VERSION ""

NS_ :

BS_:

BU_: VT3 VT2 VT1 Implement
VAL_TABLE_ NetworkInterconnUnitParametrics 16 "NetworkInterconnectionUnitType" 15 "NumberOfPorts" 14 "UptimeSinceLastPowerOnReset " 13 "AverageNumOfMsgsFilteredPerSec" 12 "AverageNumOfMsgsForwardedPerSec" 11 "AverageNumOfMsgsReceivedPerSec" 10 "NumOfMsgsWithExcessTransitDelayTime " 9 "NumOfMsgsLostDueToBufferOverflow " 8 "AverageTransitDelayTime" 7 "MaxTransitDelayTime" 6 "MaxNumOfMsgsFilteredPerSec" 5 "MaxNumOfMsgsForwardedPerSec" 4 "MaxNumOfMsgsReceivedPerSec" 3 "NumberOfFilterDatabaseEntries" 2 "MaxFilterDatabaseSize" 1 "BufferSize" 0 "RequestAllParameters" ;
VAL_TABLE_ FMI 0 "Above normal (most severe)" 1 "Below normal (most severe)" 2 "Data erratic" 3 "Voltage above normal" 4 "Voltage below normal" 5 "Current below normal" 6 "Current above normal" 7 "Mechanical system not responding" 8 "Abnormal frequency" 9 "Abnormal update rate" 10 "Abnormal rate of change" 11 "Root cause not known" 12 "Bad intelligent device" 13 "Out of calibration" 14 "Special intstructions" 15 "Above normal (least severe)" 16 "Above normal (moderately severe)" 17 "Below normal (least severe)" 18 "Below normal (moderately severe)" 19 "Received network data in error" 31 "Not available" 20 "Data Drifted High" 21 "Data Drifted Low" ;

BO_ 3221225472 VECTOR__INDEPENDENT_SIG_MSG: 0 Vector__XXX
 SG_ NumOfReportedFuncCharacteristics : 0|8@1+ (1,0) [0|255] "" Vector__XXX
 SG_ FirstListedFuncCharacteristic : 0|8@1+ (1,0) [0|255] "" Vector__XXX
 SG_ FirstListedFuncGen : 0|8@1+ (1,0) [0|255] "" Vector__XXX
 SG_ NumOfFirstListedFuncOptionBytes : 0|8@1+ (1,0) [0|2] "" Vector__XXX
 SG_ VTFuncOptions : 0|8@1+ (1,0) [0|250] "" Vector__XXX
 SG_ AuxType1_SupportFunc0 : 0|1@1+ (1,0) [0|1] "" Vector__XXX
 SG_ AuxType1_SupportFunc1 : 0|1@1+ (1,0) [0|1] "" Vector__XXX
 SG_ AuxType1_SupportFunc2 : 0|1@1+ (1,0) [0|1] "" Vector__XXX
 SG_ AuxType2_SupportFunc00 : 0|1@1+ (1,0) [0|1] "" Vector__XXX
 SG_ AuxType2_SupportFunc01 : 0|1@1+ (1,0) [0|1] "" Vector__XXX
 SG_ AuxType2_SupportFunc02 : 0|1@1+ (1,0) [0|1] "" Vector__XXX
 SG_ AuxType2_SupportFunc03 : 0|1@1+ (1,0) [0|1] "" Vector__XXX
 SG_ AuxType2_SupportFunc04 : 0|1@1+ (1,0) [0|1] "" Vector__XXX
 SG_ AuxType2_SupportFunc05 : 0|1@1+ (1,0) [0|1] "" Vector__XXX
 SG_ AuxType2_SupportFunc06 : 0|1@1+ (1,0) [0|1] "" Vector__XXX
 SG_ AuxType2_SupportFunc07 : 0|1@1+ (1,0) [0|1] "" Vector__XXX
 SG_ AuxType2_SupportFunc08 : 0|1@1+ (1,0) [0|1] "" Vector__XXX
 SG_ AuxType2_SupportFunc09 : 0|1@1+ (1,0) [0|1] "" Vector__XXX
 SG_ AuxType2_SupportFunc10 : 0|1@1+ (1,0) [0|1] "" Vector__XXX
 SG_ AuxType2_SupportFunc11 : 0|1@1+ (1,0) [0|1] "" Vector__XXX
 SG_ AuxType2_SupportFunc12 : 0|1@1+ (1,0) [0|1] "" Vector__XXX
 SG_ AuxType2_SupportFunc13 : 0|1@1+ (1,0) [0|1] "" Vector__XXX
 SG_ AuxType2_SupportFunc14 : 0|1@1+ (1,0) [0|1] "" Vector__XXX
 SG_ TCBasicFuncOptions : 0|8@1+ (1,0) [0|255] "" Vector__XXX
 SG_ TCGeoSupportedChannels : 0|8@1+ (1,0) [0|250] "" Vector__XXX
 SG_ TCGeoFuncOptions : 0|8@1+ (1,0) [0|0] "" Vector__XXX
 SG_ TCSectionNumberOfBooms : 0|8@1+ (1,0) [1|250] "" Vector__XXX
 SG_ TCSectionNumberOfSections : 0|8@1+ (1,0) [1|250] "" Vector__XXX
 SG_ BasicTECU_Class1NoOptions : 0|1@1+ (1,0) [0|1] "" Vector__XXX
 SG_ BasicTECU_Class2NoOptions : 0|1@1+ (1,0) [0|1] "" Vector__XXX
 SG_ BasicTECU_ClassRequiredLighting : 0|1@1+ (1,0) [0|1] "" Vector__XXX
 SG_ BasicTECU_NavigationOption : 0|1@1+ (1,0) [0|1] "" Vector__XXX
 SG_ BasicTECU_FrontHitchOption : 0|1@1+ (1,0) [0|1] "" Vector__XXX
 SG_ BasicTECU_GuidanceOption : 0|1@1+ (1,0) [0|1] "" Vector__XXX
 SG_ AdvanceTECU_Class3NoOptions : 0|1@1+ (1,0) [0|1] "" Vector__XXX
 SG_ AdvanceTECU_FullLightingMsgSet : 0|1@1+ (1,0) [0|1] "" Vector__XXX
 SG_ AdvanceTECU_NavigationOption : 0|1@1+ (1,0) [0|1] "" Vector__XXX
 SG_ AdvanceTECU_FrontHitchOption : 0|1@1+ (1,0) [0|1] "" Vector__XXX
 SG_ AdvanceTECU_GuidanceOption : 0|1@1+ (1,0) [0|1] "" Vector__XXX
 SG_ AdvanceTECU_PowertrainOption : 0|1@1+ (1,0) [0|1] "" Vector__XXX
 SG_ AdvanceTECU_MotionInitiationOpti : 0|1@1+ (1,0) [0|1] "" Vector__XXX
 SG_ SequenceControlFuncOptions : 0|8@1+ (1,0) [0|255] "" Vector__XXX
 SG_ StopAllImplementOperationsOption : 0|8@1+ (1,0) [0|0] "" Vector__XXX
 SG_ DiagnosticOptions : 0|8@1+ (1,0) [0|255] "" Vector__XXX
 SG_ MachineSelSpeedExitReason : 0|6@1+ (1,0) [0|63] "" Vector__XXX
 SG_ NumberOfOptionsBytes : 0|8@1+ (1,0) [0|250] "" Vector__XXX
 SG_ AuxControlType1FuncOptions : 0|8@1- (1,0) [0|255] "" Vector__XXX
 SG_ ImmediateOperandValue : 0|32@1+ (1,0) [0|0] "" Vector__XXX
 SG_ CertTypeAuxControlFunc : 0|1@1+ (1,0) [0|1] "" Vector__XXX
 SG_ CertTypeAuxControlInUnit : 0|1@1+ (1,0) [0|1] "" Vector__XXX
 SG_ CertTypeDataLogger : 0|1@1+ (1,0) [0|1] "" Vector__XXX
 SG_ CertTypeDataLoggerWSMaster : 0|1@1+ (1,0) [0|1] "" Vector__XXX
 SG_ CertTypeDataLoggerWSMember : 0|1@1+ (1,0) [0|1] "" Vector__XXX
 SG_ CertTypeFileClient : 0|1@1+ (1,0) [0|1] "" Vector__XXX
 SG_ CertTypeSecControlClient : 0|1@1+ (1,0) [0|1] "" Vector__XXX
 SG_ CertTypeSeqControlMaster : 0|1@1+ (1,0) [0|1] "" Vector__XXX
 SG_ CertTypeTCSectionControl : 0|1@1+ (1,0) [0|1] "" Vector__XXX
 SG_ CertTypeTCSectionControlWSMember : 0|1@1+ (1,0) [0|1] "" Vector__XXX

BO_ 2565340673 VT21_MyWS: 33 Implement
 SG_ UnsupportedVtFunction m253 : 8|8@1+ (1,0) [0|255] "" Vector__XXX
 SG_ AuxiliaryInputID_1 m34 : 120|16@1+ (1,0) [0|65535] "" Vector__XXX
 SG_ AuxiliaryFunctionID_1 m34 : 104|16@1+ (1,0) [0|65535] "" Vector__XXX
 SG_ NumOfPreferredFunctions m34 : 96|8@1- (1,0) [0|255] "" Vector__XXX
 SG_ ModelIdentificationCode m34 : 80|16@1+ (1,0) [0|65535] "" Vector__XXX
 SG_ ArbitraryAddressCapable m34 : 79|1@1+ (1,0) [0|1] "" Vector__XXX
 SG_ IndustryGroup m34 : 76|3@1+ (1,0) [0|7] "" Vector__XXX
 SG_ VehicleSystemInstance m34 : 72|4@1+ (1,0) [0|15] "" Vector__XXX
 SG_ VehicleSystem2 m34 : 65|7@1+ (1,0) [0|127] "" Vector__XXX
 SG_ ZoomValue_PanZoom m16 : 64|32@1- (1,0) [-32|32] "" Vector__XXX
 SG_ OperatingState2 m33 : 57|1@1+ (1,0) [0|1] "" Vector__XXX
 SG_ Function m34 : 56|8@1+ (1,0) [0|255] "" Vector__XXX
 SG_ OperatingState1 m33 : 56|1@1+ (1,0) [0|1] "" Vector__XXX
 SG_ YPosChangeTopLeftLong m180 : 56|16@1- (1,0) [-32768|32767] "" Vector__XXX
 SG_ LineDirection m169 : 56|8@1+ (1,0) [0|1] "" Vector__XXX
 SG_ FunctionInstance m34 : 51|5@1+ (1,0) [0|31] "" Vector__XXX
 SG_ ECUInstance m34 : 48|3@1+ (1,0) [0|7] "" Vector__XXX
 SG_ NewValueY m182 : 48|16@1+ (1,0) [0|65535] "" Vector__XXX
 SG_ GraphicRepresentationObjectID m181 : 48|16@1+ (1,0) [0|255] "" Vector__XXX
 SG_ FontStyle m170 : 48|8@1+ (1,0) [0|255] "" Vector__XXX
 SG_ YPosChangeTopLeft m165 : 48|8@1+ (1,-127) [-127|128] "" Vector__XXX
 SG_ OffTimeDuration_Audio m163 : 48|16@1+ (1,0) [0|65535] "ms" Vector__XXX
 SG_ ButtonKeyCode m1 : 48|8@1+ (1,0) [0|255] "" Vector__XXX
 SG_ SoftKeyCode m0 : 48|8@1+ (1,0) [0|255] "" Vector__XXX
 SG_ Status_2 m9 : 48|8@1+ (1,0) [0|1] "" Vector__XXX
 SG_ NewViewportHeight m17 : 48|16@1+ (1,0) [0|65535] "" Vector__XXX
 SG_ ViewportY_PanZoom m16 : 48|16@1- (1,0) [-32768|32767] "" Vector__XXX
 SG_ ViewportY m14 : 48|16@1- (1,0) [-32768|32767] "" Vector__XXX
 SG_ EllipseHeight m11 : 48|16@1+ (1,0) [0|65535] "" Vector__XXX
 SG_ RectangleHeight_Draw m10 : 48|16@1+ (1,0) [0|65535] "" Vector__XXX
 SG_ EndPixelOffsetY m9 : 48|16@1- (1,0) [-32768|32767] "" Vector__XXX
 SG_ PixelOffsetY m8 : 48|16@1- (1,0) [-32768|32767] "" Vector__XXX
 SG_ CursorOffsetY m1 : 48|16@1- (1,0) [-32768|32767] "" Vector__XXX
 SG_ CursorPosY m0 : 48|16@1- (1,0) [-32768|32767] "" Vector__XXX
 SG_ NewStringValue m179 : 40|16@1+ (1,0) [0|65535] "" Vector__XXX
 SG_ Value2 m33 : 40|16@1+ (1,0) [0|65535] "" Vector__XXX
 SG_ NewHeigthAttribute m183 : 40|16@1+ (1,0) [0|0] "" Vector__XXX
 SG_ FontType m170 : 40|8@1+ (1,0) [0|255] "" Vector__XXX
 SG_ XPosChangeTopLeftLong m180 : 40|16@1- (1,0) [-32768|32767] "" Vector__XXX
 SG_ FillPatternObjectID m172 : 40|16@1+ (1,0) [0|65535] "" Vector__XXX
 SG_ LineArt m171 : 40|16@1+ (1,0) [0|65535] "" Vector__XXX
 SG_ LabelFontType m181 : 40|8@1+ (1,0) [0|255] "" Vector__XXX
 SG_ Height m169 : 40|16@1+ (1,0) [0|65535] "" Vector__XXX
 SG_ NewHeight m166 : 40|16@1+ (1,0) [0|65535] "" Vector__XXX
 SG_ XPosChangeTopLeft m165 : 40|8@1+ (1,-127) [-127|128] "" Vector__XXX
 SG_ TouchState m2 : 40|8@1+ (1,0) [0|255] "" Vector__XXX
 SG_ TextLength m13 : 40|8@1+ (1,0) [0|255] "bytes" Vector__XXX
 SG_ ManufacturerCode m34 : 37|11@1+ (1,0) [0|2047] "" Vector__XXX
 SG_ AuxErrorAnyOther m37 : 33|1@1+ (1,0) [0|1] "" Vector__XXX
 SG_ CursorPosX m0 : 32|16@1- (1,0) [-32768|32767] "" Vector__XXX
 SG_ CursorOffsetX m1 : 32|16@1- (1,0) [-32768|32767] "" Vector__XXX
 SG_ ForegroundColour m2 : 32|8@1+ (1,0) [0|255] "" Vector__XXX
 SG_ BackgroundColour m3 : 32|8@1+ (1,0) [0|255] "" Vector__XXX
 SG_ LineAttributesObjectID m4 : 32|16@1+ (1,0) [0|65535] "" Vector__XXX
 SG_ FillAttributesObjectID m5 : 32|16@1+ (1,0) [0|65535] "" Vector__XXX
 SG_ FontAttributesObjectID m6 : 32|16@1+ (1,0) [0|65535] "" Vector__XXX
 SG_ RectangleWidth_Erase m7 : 32|16@1+ (1,0) [0|65535] "" Vector__XXX
 SG_ RectangleHeight_Erase m7 : 48|16@1+ (1,0) [0|65535] "" Vector__XXX
 SG_ PixelOffsetX m8 : 32|16@1- (1,0) [-32768|32767] "" Vector__XXX
 SG_ EndPixelOffsetX m9 : 32|16@1- (1,0) [-32768|32767] "" Vector__XXX
 SG_ RectangleWidth_Draw m10 : 32|16@1+ (1,0) [0|65535] "" Vector__XXX
 SG_ EllipseWidth m11 : 32|16@1+ (1,0) [0|65535] "" Vector__XXX
 SG_ NumberOfPoints m12 : 32|8@1+ (1,0) [0|255] "" Vector__XXX
 SG_ TextOption m13 : 32|8@1+ (1,0) [0|1] "" Vector__XXX
 SG_ ViewportX m14 : 32|16@1- (1,0) [-32768|32767] "" Vector__XXX
 SG_ ZoomValue m15 : 32|32@1- (1,0) [-32|32] "" Vector__XXX
 SG_ ViewportX_PanZoom m16 : 32|16@1- (1,0) [-32768|32767] "" Vector__XXX
 SG_ NewViewportWidth m17 : 32|16@1+ (1,0) [0|65535] "" Vector__XXX
 SG_ ObjectID m18 : 32|16@1+ (1,0) [0|65534] "" Vector__XXX
 SG_ PictureGraphicsID_Canvas m19 : 32|16@1+ (1,0) [0|65534] "" Vector__XXX
 SG_ PictureGraphicsID_Viewport m20 : 32|16@1+ (1,0) [0|65534] "" Vector__XXX
 SG_ LastWideChar m193 : 32|16@1+ (1,0) [0|65535] "" Vector__XXX
 SG_ LockTimeout m189 : 32|16@1+ (1,0) [0|65535] "" Vector__XXX
 SG_ NewValueX m182 : 32|16@1+ (1,0) [0|65535] "" Vector__XXX
 SG_ NewObjectID m177 : 32|16@1+ (1,0) [0|65535] "" Vector__XXX
 SG_ NewAttributeValue m175 : 32|32@1+ (1,0) [0|0] "" Vector__XXX
 SG_ NewSoftKeyMaskObjectID m174 : 32|16@1+ (1,0) [0|65535] "" Vector__XXX
 SG_ FillColour m172 : 32|8@1+ (1,0) [0|255] "" Vector__XXX
 SG_ LineWidth m171 : 32|8@1+ (1,0) [0|255] "" Vector__XXX
 SG_ FontSize m170 : 32|8@1+ (1,0) [0|255] "" Vector__XXX
 SG_ NewValue m168 : 32|32@1+ (1,0) [0|65535] "" Vector__XXX
 SG_ OnTimeDuration_Audio m163 : 32|16@1+ (1,0) [0|65535] "ms" Vector__XXX
 SG_ AuxErrorInvalidInputID m37 : 32|1@1+ (1,0) [0|1] "" Vector__XXX
 SG_ VTChangeNumericValueValue m5 : 32|32@1+ (1,0) [0|4294967295] "" Vector__XXX
 SG_ ButtonObjectParentID m1 : 32|16@1+ (1,0) [0|65535] "" Vector__XXX
 SG_ KeyObjectParentID m0 : 32|16@1+ (1,0) [0|65535] "" Vector__XXX
 SG_ ObjectId_2 m9 : 32|16@1+ (1,0) [0|65535] "" Vector__XXX
 SG_ Value1 m33 : 24|16@1+ (1,0) [0|65535] "" Vector__XXX
 SG_ TotalNumberOfBytes m179 : 24|16@1- (1,0) [0|0] "bytes" Vector__XXX
 SG_ AttributeIDToChange m175 : 24|8@1+ (1,0) [0|0] "" Vector__XXX
 SG_ SubCommandID m184M : 24|8@1+ (1,0) [0|0] "" Vector__XXX
 SG_ NewWidthAttribute m183 : 24|16@1+ (1,0) [0|65535] "" Vector__XXX
 SG_ IndexOfThePointToReplace m182 : 24|8@1+ (1,0) [0|255] "" Vector__XXX
 SG_ StringVariableObjectID m181 : 24|16@1+ (1,0) [0|65535] "" Vector__XXX
 SG_ ChangeChildLocationObjectID m165 : 24|16@1+ (1,0) [0|65535] "" Vector__XXX
 SG_ ListIndex m177 : 24|8@1+ (1,0) [0|255] "" Vector__XXX
 SG_ NewPriority m176 : 24|8@1+ (1,0) [0|255] "" Vector__XXX
 SG_ AttributeID m185 : 24|8@1+ (1,0) [0|16777200] "" Vector__XXX
 SG_ NewActiveMaskObjectID m173 : 24|16@1+ (1,0) [0|65535] "" Vector__XXX
 SG_ FillType m172 : 24|8@1+ (1,0) [0|255] "" Vector__XXX
 SG_ LineColour m171 : 24|8@1+ (1,0) [0|255] "" Vector__XXX
 SG_ FontColour m170 : 24|8@1+ (1,0) [0|255] "" Vector__XXX
 SG_ Width m169 : 24|16@1+ (1,0) [0|65535] "" Vector__XXX
 SG_ NewBackgroundColour m167 : 24|8@1+ (1,0) [0|255] "" Vector__XXX
 SG_ NewWidth m166 : 24|16@1+ (1,0) [0|65535] "" Vector__XXX
 SG_ ChangeChildPositionObjectID m180 : 24|16@1+ (1,0) [0|65535] "" Vector__XXX
 SG_ SetFocusOpenForEditing m162 : 24|8@1+ (1,0) [0|255] "" Vector__XXX
 SG_ EnableOrDisable m161 : 24|8@1+ (1,0) [0|1] "" Vector__XXX
 SG_ ShowOrHide m160 : 24|8@1+ (1,0) [0|1] "" Vector__XXX
 SG_ AuxInputEnable m37 : 24|8@1+ (1,0) [0|1] "" Vector__XXX
 SG_ AssignmentErrorNotAccepted m36 : 24|1@1+ (1,0) [0|1] "" Vector__XXX
 SG_ ObjectOfChangedStringValueID m8 : 24|16@1+ (1,0) [0|65535] "" Vector__XXX
 SG_ VTChangeSoftKeyMaskObjectID m7 : 24|16@1+ (1,0) [0|65535] "" Vector__XXX
 SG_ VTSelectInputObjectStatus m3 : 24|8@1+ (1,0) [0|1] "" Vector__XXX
 SG_ YPosition m2 : 24|16@1+ (1,0) [0|65535] "" Vector__XXX
 SG_ AuxiliaryFunctionID m32 : 24|16@1+ (1,0) [0|65535] "" Vector__XXX
 SG_ Status_1 m9 : 24|8@1+ (1,0) [0|1] "" Vector__XXX
 SG_ IdentityNumber m34 : 16|21@1+ (1,0) [0|2097152] "" Vector__XXX
 SG_ FirstWideChar m193 : 16|16@1+ (1,0) [0|65535] "" Vector__XXX
 SG_ MemoryRequired m192 : 16|32@1+ (1,0) [0|4294967295] "" Vector__XXX
 SG_ ObjectIDOfDataMaskToLock m189 : 16|16@1+ (1,0) [0|65535] "" Vector__XXX
 SG_ DataOrAlarmMaskObjectID m174 : 16|16@1+ (1,0) [0|65535] "" Vector__XXX
 SG_ Frequency_Audio m163 : 16|16@1+ (1,0) [0|65535] "hz" Vector__XXX
 SG_ ButtonObjectID m1 : 16|16@1+ (1,0) [0|65535] "" Vector__XXX
 SG_ KeyObjectID m0 : 16|16@1+ (1,0) [0|65535] "" Vector__XXX
 SG_ WSMaintenanceVersion m255M : 16|8@1+ (1,0) [0|255] "" Vector__XXX
 SG_ AuxiliaryInputNumber m32 : 16|8@1+ (1,0) [0|255] "" Vector__XXX
 SG_ ExtendedVersionLabelToDelete m214 : 8|256@1+ (1,0) [0|3338120000] "" Vector__XXX
 SG_ ExtendedVersionLabelToLoad m213 : 8|256@1+ (1,0) [0|3338120000] "" Vector__XXX
 SG_ ExtendedVersionLabelToStore m212 : 8|256@1+ (1,0) [0|3338120000] "" Vector__XXX
 SG_ MacroObjectID_2 m188 : 8|16@1+ (1,0) [0|65535] "" Vector__XXX
 SG_ AuxCapabilitiesRequestType m39 : 8|8@1+ (1,0) [0|255] "" Vector__XXX
 SG_ WSMaintenanceInitiating m3 : 8|1@1+ (1,0) [0|1] "" Vector__XXX
 SG_ VersionLabelToDelete m210 : 8|56@1+ (1,0) [0|3338120000] "" Vector__XXX
 SG_ VersionLabelToLoad m209 : 8|56@1+ (1,0) [0|3338120000] "" Vector__XXX
 SG_ VersionLabelToStore m208 : 8|56@1+ (1,0) [0|3338120000] "" Vector__XXX
 SG_ CodePlane m193 : 8|8@1+ (1,0) [0|16] "" Vector__XXX
 SG_ MacroObjectID m190 : 8|8@1+ (1,0) [0|255] "" Vector__XXX
 SG_ LockUnlockCommand m189 : 8|8@1+ (1,0) [0|1] "" Vector__XXX
 SG_ ColourMapObjectID m186 : 8|16@1+ (1,0) [0|65535] "" Vector__XXX
 SG_ ObjectToGetAttributeID m185 : 8|16@1+ (1,0) [0|65535] "" Vector__XXX
 SG_ GraphicsContextObjectID m184 : 8|16@1+ (1,0) [0|65535] "" Vector__XXX
 SG_ PolygonObjectToScaleID m183 : 8|16@1+ (1,0) [0|65535] "" Vector__XXX
 SG_ PolygonObjectToChangeID m182 : 8|16@1+ (1,0) [0|65535] "" Vector__XXX
 SG_ ObjectToAssociateLabelWithID m181 : 8|16@1+ (1,0) [0|65535] "" Vector__XXX
 SG_ ParentObjectID m8 : 8|16@1+ (1,0) [0|65535] "" Vector__XXX
 SG_ ObjectToChangeStringValueID m179 : 8|16@1+ (1,0) [0|65535] "" Vector__XXX
 SG_ ListInputObjectID m177 : 8|16@1+ (1,0) [0|65535] "" Vector__XXX
 SG_ AlarmMaskObjectID m176 : 8|16@1+ (1,0) [0|65535] "" Vector__XXX
 SG_ ObjectToChangeAttributeID m175 : 8|16@1+ (1,0) [0|65535] "" Vector__XXX
 SG_ MaskType m174 : 8|8@1+ (1,0) [0|255] "" Vector__XXX
 SG_ WorkingSetObjectID m173 : 8|16@1+ (1,0) [0|65535] "" Vector__XXX
 SG_ ObjectToChangeFillAttributesID m172 : 8|16@1+ (1,0) [0|65535] "" Vector__XXX
 SG_ ObjectToChangeLineAttributesID m171 : 8|16@1+ (1,0) [0|65535] "" Vector__XXX
 SG_ ObjectToChangeFontID m170 : 8|16@1+ (1,0) [0|65535] "" Vector__XXX
 SG_ ObjectToChangeEndPointID m169 : 8|16@1+ (1,0) [0|65535] "" Vector__XXX
 SG_ ObjectToChangeNumValueID m168 : 8|16@1+ (1,0) [0|65535] "" Vector__XXX
 SG_ ObjectToChangeColourID m167 : 8|16@1+ (1,0) [0|65535] "" Vector__XXX
 SG_ ObjectToSizeID m166 : 8|16@1+ (1,0) [0|65535] "" Vector__XXX
 SG_ ChangeChildLocationParentObjectI m165 : 8|16@1+ (1,0) [0|65535] "" Vector__XXX
 SG_ AudioVolume m164 : 8|8@1+ (1,0) [0|100] "%" Vector__XXX
 SG_ NumberOfRepetitions_Audio m163 : 8|8@1+ (1,0) [0|255] "" Vector__XXX
 SG_ SelectInputObjectID m162 : 8|16@1+ (1,0) [0|65535] "" Vector__XXX
 SG_ ObjectoEnableDisbaleID m161 : 8|16@1+ (1,0) [0|65535] "" Vector__XXX
 SG_ ObjectToShowHideID m160 : 8|16@1+ (1,0) [0|65535] "" Vector__XXX
 SG_ InputStatusObjectId m37 : 8|16@1+ (1,0) [0|255] "" Vector__XXX
 SG_ AuxModelIdentification m35 : 8|16@1+ (1,0) [0|65535] "" Vector__XXX
 SG_ NumberOfInpuUnits m34 : 8|8@1+ (1,0) [0|255] "" Vector__XXX
 SG_ AuxiliaryFunctionObjectID m36 : 8|16@1+ (1,0) [0|65535] "" Vector__XXX
 SG_ ObjectPoolRecord m17 : 8|56@1+ (1,0) [0|3338120000] "" Vector__XXX
 SG_ ChangeChildPositionParentObjectI m180 : 8|16@1+ (1,0) [0|65535] "" Vector__XXX
 SG_ VTChangeSoftKeyMaskParentID m7 : 8|16@1+ (1,0) [0|65535] "" Vector__XXX
 SG_ VTChangeActiveMaskObjectID m6 : 8|16@1+ (1,0) [0|65535] "" Vector__XXX
 SG_ VTChangeNumericValueObjectID m5 : 8|16@1+ (1,0) [0|65535] "" Vector__XXX
 SG_ VTEscObjectID m4 : 8|16@1+ (1,0) [0|65535] "" Vector__XXX
 SG_ VTSelectInputObjectID m3 : 8|16@1+ (1,0) [0|65535] "" Vector__XXX
 SG_ XPosition m2 : 8|16@1+ (1,0) [0|65535] "" Vector__XXX
 SG_ ButtonActivationCode m1 : 8|8@1+ (1,0) [0|2] "" Vector__XXX
 SG_ KeyActivationCode m0 : 8|8@1+ (1,0) [0|2] "" Vector__XXX
 SG_ InputObjectId m33 : 8|16@1+ (1,0) [0|255] "" Vector__XXX
 SG_ SourceAddressOfAuxiliaryInputDev m32 : 8|8@1+ (1,0) [0|255] "" Vector__XXX
 SG_ ObjectId_1 m9 : 8|16@1+ (1,0) [0|65535] "" Vector__XXX
 SG_ VTFunctionECUtoVT M : 0|8@1+ (1,0) [0|255] "" Vector__XXX

BO_ 2633895169 WSMSTR_MyWS: 8 Implement
 SG_ NumberOfMembers : 0|8@1+ (1,0) [0|0] "" Vector__XXX

BO_ 2565799425 ACL_MyWS: 8 Implement
 SG_ ArbitraryAddressCapable : 63|1@1+ (1,0) [0|1] "" Vector__XXX
 SG_ IndustryGroup M : 60|3@1+ (1,0) [0|7] "" Vector__XXX
 SG_ VehicleSystemInstance : 56|4@1+ (1,0) [0|15] "" Vector__XXX
 SG_ VehicleSystem m0 : 49|7@1+ (1,0) [0|127] "" Vector__XXX
 SG_ VehicleSystem5 m5 : 49|7@1+ (1,0) [0|127] "" Vector__XXX
 SG_ VehicleSystem4 m4 : 49|7@1+ (1,0) [0|127] "" Vector__XXX
 SG_ VehicleSystem3 m3 : 49|7@1+ (1,0) [0|127] "" Vector__XXX
 SG_ VehicleSystem2 m2 : 49|7@1+ (1,0) [0|127] "" Vector__XXX
 SG_ VehicleSystem1 m1 : 49|7@1+ (1,0) [0|127] "" Vector__XXX
 SG_ Function : 40|8@1+ (1,0) [0|255] "" Vector__XXX
 SG_ FunctionInstance : 35|5@1+ (1,0) [0|31] "" Vector__XXX
 SG_ ECUInstance : 32|3@1+ (1,0) [0|7] "" Vector__XXX
 SG_ ManufacturerCode : 21|11@1+ (1,0) [0|2047] "" Vector__XXX
 SG_ IdentityNumber : 0|21@1+ (1,0) [0|2097152] "" Vector__XXX

BO_ 2364597502 HB: 1 Vector__XXX
 SG_ HeartbeatSequenceNumber : 0|8@1+ (1,0) [0|0] "" Vector__XXX

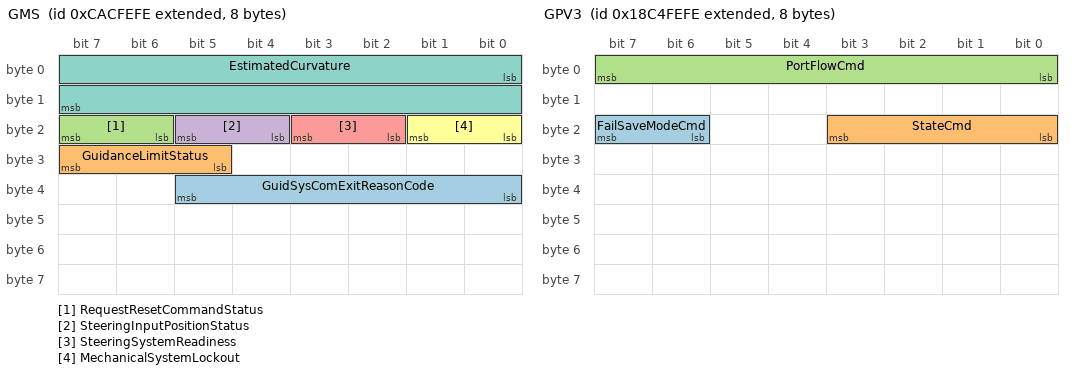
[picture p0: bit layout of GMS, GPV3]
BO_ 2360147710 GMS: 8 Vector__XXX
 SG_ GuidSysComExitReasonCode : 32|6@1+ (1,0) [0|63] "" Vector__XXX
 SG_ GuidanceLimitStatus : 29|3@1+ (1,0) [0|7] "" Vector__XXX
 SG_ RequestResetCommandStatus : 22|2@1+ (1,0) [0|3] "" Vector__XXX
 SG_ SteeringInputPositionStatus : 20|2@1+ (1,0) [0|3] "" Vector__XXX
 SG_ SteeringSystemReadiness : 18|2@1+ (1,0) [0|3] "" Vector__XXX
 SG_ MechanicalSystemLockout : 16|2@1+ (1,0) [0|3] "" Vector__XXX
 SG_ EstimatedCurvature : 0|16@1+ (0.25,-8032) [-8032|8031.75] "1/km" Vector__XXX

BO_ 2360213246 GSC: 8 Vector__XXX
 SG_ CurvatureCommandStatus : 16|2@1+ (1,0) [0|3] "" Vector__XXX
 SG_ CurvatureCommand : 0|16@1+ (0.25,-8032) [-8032|8031.75] "1/km" Vector__XXX

BO_ 2563047166 GPV3: 8 Vector__XXX
 SG_ FailSaveModeCmd : 22|2@1+ (1,0) [0|3] "" Vector__XXX
 SG_ StateCmd : 16|4@1+ (1,0) [0|15] "" Vector__XXX
 SG_ PortFlowCmd : 0|8@1+ (0.4,0) [0|100] "%" Vector__XXX

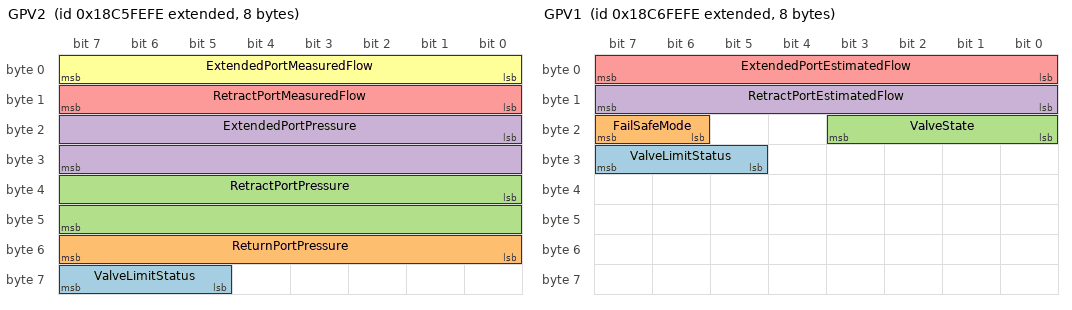
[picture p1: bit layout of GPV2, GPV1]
BO_ 2563112702 GPV2: 8 Vector__XXX
 SG_ ValveLimitStatus : 61|3@1+ (1,0) [0|7] "" Vector__XXX
 SG_ ReturnPortPressure : 48|8@1+ (16,0) [0|4000] "kPa" Vector__XXX
 SG_ RetractPortPressure : 32|16@1+ (5,0) [0|321275] "kPa" Vector__XXX
 SG_ ExtendedPortPressure : 16|16@1+ (5,0) [0|321275] "kPa" Vector__XXX
 SG_ RetractPortMeasuredFlow : 8|8@1+ (1,-125) [-125|125] "%" Vector__XXX
 SG_ ExtendedPortMeasuredFlow : 0|8@1+ (1,-125) [-125|125] "%" Vector__XXX

BO_ 2563178238 GPV1: 8 Vector__XXX
 SG_ ValveLimitStatus : 29|3@1+ (1,0) [0|7] "" Vector__XXX
 SG_ FailSafeMode : 22|2@1+ (1,0) [0|3] "" Vector__XXX
 SG_ ValveState : 16|4@1+ (1,0) [0|15] "" Vector__XXX
 SG_ RetractPortEstimatedFlow : 8|8@1+ (1,-125) [-125|125] "%" Vector__XXX
 SG_ ExtendedPortEstimatedFlow : 0|8@1+ (1,-125) [-125|125] "%" Vector__XXX

BO_ 2628452094 FSClient: 9 Vector__XXX
 SG_ VI_VolumeName m64 : 56|16@1+ (1,0) [0|65535] "" Vector__XXX
 SG_ VI_Flag_OverwriteExisting m64 : 48|1@1+ (1,0) [0|1] "" Vector__XXX
 SG_ MF_DestinationPathNameLength m48 : 40|16@1+ (1,0) [0|65535] "" Vector__XXX
 SG_ RF_ReportHiddenFiles m34 : 40|8@1+ (1,0) [0|255] "" Vector__XXX
 SG_ SF_Offset m33 : 32|32@1- (1,0) [-2147483648|2147483647] "" Vector__XXX
 SG_ RF_Count m34 : 24|16@1+ (1,0) [0|65535] "" Vector__XXX
 SG_ SF_PositionMode m33 : 24|8@1+ (1,0) [0|255] "" Vector__XXX
 SG_ OF_PathName m32 : 24|16@1+ (1,0) [0|65535] "" Vector__XXX
 SG_ MF_SourcePathNameLength m48 : 24|16@1+ (1,0) [0|65535] "" Vector__XXX
 SG_ WF_Count m35 : 24|16@1+ (1,0) [0|65535] "" Vector__XXX
 SG_ DF_PathName m49 : 24|16@1+ (1,0) [0|65535] "" Vector__XXX
 SG_ SA_PathName m51 : 24|16@1+ (1,0) [0|65535] "" Vector__XXX
 SG_ VI_Space m64 : 16|32@1+ (1,0) [0|4294967295] "" Vector__XXX
 SG_ OF_FlagExclusiveAccess m32 : 20|1@1+ (1,0) [0|1] "" Vector__XXX
 SG_ OF_FlagAppend m32 : 19|1@1+ (1,0) [0|1] "" Vector__XXX
 SG_ SET_ATTR_Hidden m51 : 18|2@1+ (1,0) [0|3] "" Vector__XXX
 SG_ OF_FlagCreateNew m32 : 18|1@1+ (1,0) [0|1] "" Vector__XXX
 SG_ MF_MoveModeRecursive m48 : 18|1@1+ (1,0) [0|1] "" Vector__XXX
 SG_ DF_DeleteModeRecursive m49 : 18|1@1+ (1,0) [0|1] "" Vector__XXX
 SG_ MF_MoveModeForce m48 : 17|1@1+ (1,0) [0|1] "" Vector__XXX
 SG_ DF_DeleteModeForce m49 : 17|1@1+ (1,0) [0|1] "" Vector__XXX
 SG_ VI_Flag_UsingSpaceSpecified m64 : 49|1@1+ (1,0) [0|1] "" Vector__XXX
 SG_ SET_ATTR_ReadOnly m51 : 16|2@1+ (1,0) [0|3] "" Vector__XXX
 SG_ CF_Handle m36 : 16|8@1+ (1,0) [0|255] "" Vector__XXX
 SG_ WF_Handle m35 : 16|8@1+ (1,0) [0|255] "" Vector__XXX
 SG_ RF_Handle m34 : 16|8@1+ (1,0) [0|255] "" Vector__XXX
 SG_ SF_Handle m33 : 16|8@1+ (1,0) [0|255] "" Vector__XXX
 SG_ OF_FlagReadWrite m32 : 16|2@1+ (1,0) [0|3] "" Vector__XXX
 SG_ CCD_PathName m17 : 16|16@1+ (1,0) [0|65535] "" Vector__XXX
 SG_ MF_MoveModeCopy m48 : 16|1@1+ (1,0) [0|1] "" Vector__XXX
 SG_ DF_DeleteMode m49 : 16|1@1+ (1,0) [0|1] "" Vector__XXX
 SG_ GA_PathName m50 : 16|16@1+ (1,0) [0|65535] "" Vector__XXX
 SG_ FDT_PathName m52 : 16|16@1+ (1,0) [0|65535] "" Vector__XXX
 SG_ VS_VolumeName m2 : 16|16@1+ (1,0) [0|0] "" Vector__XXX
 SG_ VS_RequestVolumeToPrepareForRemo m2 : 9|1@1- (1,0) [0|1] "" Vector__XXX
 SG_ CCD_TAN m17 : 8|8@1+ (1,0) [0|255] "" Vector__XXX
 SG_ GCD_TAN m16 : 8|8@1+ (1,0) [0|255] "" Vector__XXX
 SG_ FDT_TAN m52 : 8|8@1+ (1,0) [0|255] "" Vector__XXX
 SG_ SA_TAN m51 : 8|8@1+ (1,0) [0|255] "" Vector__XXX
 SG_ GA_TAN m50 : 8|8@1+ (1,0) [0|255] "" Vector__XXX
 SG_ RF_TAN m34 : 8|8@1+ (1,0) [0|255] "" Vector__XXX
 SG_ CF_TAN m36 : 8|8@1+ (1,0) [0|255] "" Vector__XXX
 SG_ WF_TAN m35 : 8|8@1+ (1,0) [0|255] "" Vector__XXX
 SG_ SF_TAN m33 : 8|8@1+ (1,0) [0|255] "" Vector__XXX
 SG_ OF_TAN m32 : 8|8@1+ (1,0) [0|255] "" Vector__XXX
 SG_ MF_TAN m48 : 8|8@1+ (1,0) [0|255] "" Vector__XXX
 SG_ DF_TAN m49 : 8|8@1+ (1,0) [0|255] "" Vector__XXX
 SG_ VI_TAN m64 : 8|8@1+ (1,0) [0|255] "" Vector__XXX
 SG_ VS_ReportVolumeUsedByClient m2 : 8|1@1+ (1,0) [0|1] "" Vector__XXX
 SG_ CM_VersionNumber m0 : 8|8@1+ (1,0) [0|255] "" Vector__XXX
 SG_ FSClientCommand M : 0|8@1+ (1,0) [0|255] "" Vector__XXX

BO_ 2628517630 FSServer: 35 Vector__XXX
 SG_ GCD_PathName m16 : 88|16@1+ (1,0) [0|65535] "" Vector__XXX
 SG_ GCD_FreeSpace m16 : 56|32@1+ (512,0) [0|4294966744] "Bytes" Vector__XXX
 SG_ FDT_TimeHour m52 : 51|5@1+ (1,0) [0|23] "Hour" Vector__XXX
 SG_ FDT_TimeMinutes m52 : 45|6@1+ (1,0) [0|59] "Minutes" Vector__XXX
 SG_ FDT_TimeSeconds m52 : 40|5@1+ (2,0) [0|58] "Seconds" Vector__XXX
 SG_ OF_ATTR_VolumeIsCaseSensitive m32 : 39|1@1+ (1,0) [0|1] "" Vector__XXX
 SG_ OF_ATTR_VolumeRemovable m32 : 38|1@1+ (1,0) [0|1] "" Vector__XXX
 SG_ OF_ATTR_SupportsLongFilenames m32 : 37|1@1+ (1,0) [0|1] "" Vector__XXX
 SG_ OF_ATTR_Directory m32 : 36|1@1+ (1,0) [0|1] "" Vector__XXX
 SG_ OF_ATTR_IsVolume m32 : 35|1@1+ (1,0) [0|1] "" Vector__XXX
 SG_ FDT_DateYear m52 : 33|7@1+ (1,1980) [1980|2107] "Year" Vector__XXX
 SG_ OF_ATTR_Hidden m32 : 33|1@1+ (1,0) [0|1] "" Vector__XXX
 SG_ SF_Position m33 : 32|32@1+ (1,0) [0|4294967295] "" Vector__XXX
 SG_ OF_ATTR_ReadOnly m32 : 32|1@1+ (1,0) [0|1] "" Vector__XXX
 SG_ GA_Size m50 : 32|32@1+ (1,0) [0|4294967295] "" Vector__XXX
 SG_ VS_VolumeName m2 : 32|16@1+ (1,0) [0|65535] "" Vector__XXX
 SG_ VI_VolumeIsCaseSensitive m64 : 31|1@1+ (1,0) [0|1] "" Vector__XXX
 SG_ GA_ATTR_VolumeIsCaseSensitive m50 : 31|1@1+ (1,0) [0|1] "" Vector__XXX
 SG_ VI_ATTR_VolumeRemovable m64 : 30|1@1+ (1,0) [0|1] "" Vector__XXX
 SG_ GA_ATTR_VolumeRemovable m50 : 30|1@1+ (1,0) [0|1] "" Vector__XXX
 SG_ VI_ATTR_SupportsLongFilenames m64 : 29|1@1+ (1,0) [0|1] "" Vector__XXX
 SG_ FDT_DateMonth m52 : 29|4@1+ (1,0) [0|12] "Month" Vector__XXX
 SG_ GA_ATTR_SupportsLongFilenames m50 : 29|1@1+ (1,0) [0|1] "" Vector__XXX
 SG_ GA_ATTR_Directory m50 : 28|1@1+ (1,0) [0|1] "" Vector__XXX
 SG_ VI_ATTR_Directory m64 : 28|1@1+ (1,0) [0|1] "" Vector__XXX
 SG_ VI_ATTR_IsVolume m64 : 27|1@1+ (1,0) [0|1] "" Vector__XXX
 SG_ GA_ATTR_IsVolume m50 : 27|1@1+ (1,0) [0|1] "" Vector__XXX
 SG_ VI_ATTR_VolSupportsHiddenAttr m64 : 26|1@1+ (1,0) [0|1] "" Vector__XXX
 SG_ GA_ATTR_VolSupportsHiddenAttr m50 : 26|1@1+ (1,0) [0|1] "" Vector__XXX
 SG_ VI_ATTR_Hidden m64 : 25|1@1+ (1,0) [0|1] "" Vector__XXX
 SG_ GA_ATTR_Hidden m50 : 25|1@1+ (1,0) [0|1] "" Vector__XXX
 SG_ VI_ATTR_ReadOnly m64 : 24|1@1+ (1,0) [0|1] "" Vector__XXX
 SG_ FDT_DateDay m52 : 24|5@1+ (1,0) [0|31] "Day" Vector__XXX
 SG_ GA_ATTR_ReadOnly m50 : 24|1@1+ (1,0) [0|1] "" Vector__XXX
 SG_ OF_Handle m32 : 24|8@1+ (1,0) [0|255] "" Vector__XXX
 SG_ GCD_TotalSpace m16 : 24|32@1+ (512,0) [0|4294966744] "Bytes" Vector__XXX
 SG_ RF_Count m34 : 24|16@1+ (1,0) [0|65535] "Bytes" Vector__XXX
 SG_ GSP_SupportMultipleVolumes m1 : 24|1@1+ (1,0) [0|255] "" Vector__XXX
 SG_ WF_Count m35 : 24|16@1+ (1,0) [0|65535] "" Vector__XXX
 SG_ VS_ErrorCode m2 : 24|8@1+ (1,0) [0|255] "" Vector__XXX
 SG_ FDT_ErrorCode m52 : 16|8@1+ (1,0) [0|255] "" Vector__XXX
 SG_ RF_ErrorCode m34 : 16|8@1+ (1,0) [0|255] "" Vector__XXX
 SG_ SF_ErrorCode m33 : 16|8@1+ (1,0) [0|255] "" Vector__XXX
 SG_ FSNumberOfOpenFiles m0 : 16|8@1- (1,0) [0|255] "" Vector__XXX
 SG_ OF_ErrorCode m32 : 16|8@1+ (1,0) [0|255] "" Vector__XXX
 SG_ WF_ErrorCode m35 : 16|8@1+ (1,0) [0|255] "" Vector__XXX
 SG_ CF_ErrorCode m36 : 16|8@1+ (1,0) [0|255] "" Vector__XXX
 SG_ MF_ErrorCode m48 : 16|8@1+ (1,0) [0|255] "" Vector__XXX
 SG_ GA_ErrorCode m50 : 16|8@1+ (1,0) [0|255] "" Vector__XXX
 SG_ SA_ErrorCode m51 : 16|8@1+ (1,0) [0|255] "" Vector__XXX
 SG_ GCD_ErrorCode m16 : 16|8@1+ (1,0) [0|255] "" Vector__XXX
 SG_ CCD_ErrorCode m17 : 16|8@1+ (1,0) [0|255] "" Vector__XXX
 SG_ GSP_MaxNrSimultaneousFilesOpen m1 : 16|8@1+ (1,0) [0|255] "" Vector__XXX
 SG_ DF_ErrorCode m49 : 16|8@1+ (1,0) [0|255] "" Vector__XXX
 SG_ VI_ErrorCode m64 : 16|8@1+ (1,0) [0|255] "" Vector__XXX
 SG_ VS_MaxTimeBeforeVolRemoval m2 : 16|8@1+ (1,0) [0|250] "min/bit" Vector__XXX
 SG_ FSBusyWriting m0 : 9|1@1+ (1,0) [0|1] "" Vector__XXX
 SG_ FSBusyReading m0 : 8|1@1+ (1,0) [0|1] "" Vector__XXX
 SG_ OF_TAN m32 : 8|8@1+ (1,0) [0|255] "" Vector__XXX
 SG_ SF_TAN m33 : 8|8@1+ (1,0) [0|255] "" Vector__XXX
 SG_ RF_TAN m34 : 8|8@1+ (1,0) [0|255] "" Vector__XXX
 SG_ WF_TAN m35 : 8|8@1+ (1,0) [0|255] "" Vector__XXX
 SG_ CF_TAN m36 : 8|8@1+ (1,0) [0|255] "" Vector__XXX
 SG_ MF_TAN m48 : 8|8@1+ (1,0) [0|255] "" Vector__XXX
 SG_ GA_TAN m50 : 8|8@1+ (1,0) [0|255] "" Vector__XXX
 SG_ SA_TAN m51 : 8|8@1+ (1,0) [0|255] "" Vector__XXX
 SG_ FDT_TAN m52 : 8|8@1+ (1,0) [0|255] "" Vector__XXX
 SG_ GCD_TAN m16 : 8|8@1+ (1,0) [0|255] "" Vector__XXX
 SG_ CCD_TAN m17 : 8|8@1+ (1,0) [0|255] "" Vector__XXX
 SG_ GSP_VersionNumber m1 : 8|8@1+ (1,0) [0|255] "" Vector__XXX
 SG_ DF_TAN m49 : 8|8@1+ (1,0) [0|255] "" Vector__XXX
 SG_ VI_TAN m64 : 8|8@1+ (1,0) [0|255] "" Vector__XXX
 SG_ VS_VolumeStatus m2 : 8|8@1+ (1,0) [0|3] "" Vector__XXX
 SG_ FSServerCommand M : 0|8@1+ (1,0) [0|255] "" Vector__XXX

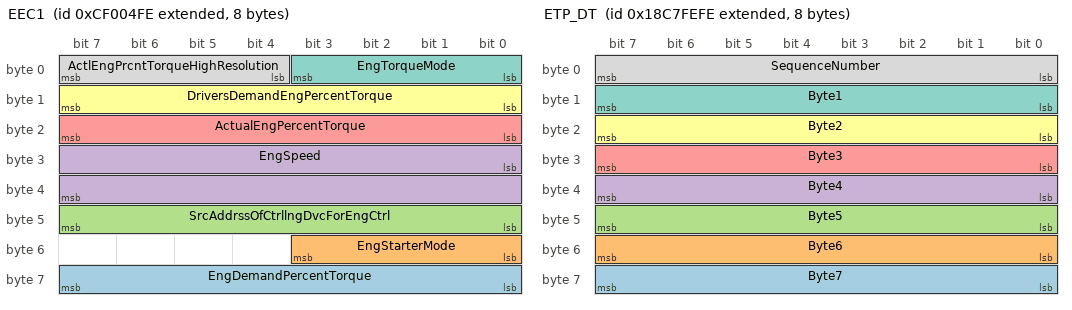
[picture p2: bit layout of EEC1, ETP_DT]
BO_ 2364540158 EEC1: 8 Vector__XXX
 SG_ EngDemandPercentTorque : 56|8@1+ (1,-125) [-125|125] "%" Vector__XXX
 SG_ EngStarterMode : 48|4@1+ (1,0) [0|15] "" Vector__XXX
 SG_ SrcAddrssOfCtrllngDvcForEngCtrl : 40|8@1+ (1,0) [0|255] "" Vector__XXX
 SG_ EngSpeed : 24|16@1+ (0.125,0) [0|8031.875] "rpm" Vector__XXX
 SG_ ActualEngPercentTorque : 16|8@1+ (1,-125) [-125|125] "%" Vector__XXX
 SG_ DriversDemandEngPercentTorque : 8|8@1+ (1,-125) [-125|125] "%" Vector__XXX
 SG_ EngTorqueMode : 0|4@1+ (1,0) [0|15] "" Vector__XXX
 SG_ ActlEngPrcntTorqueHighResolution : 4|4@1+ (0.125,0) [0|0.875] "%" Vector__XXX

BO_ 2563243774 ETP_DT: 8 Vector__XXX
 SG_ Byte7 : 56|8@1+ (1,0) [0|255] "" Vector__XXX
 SG_ Byte6 : 48|8@1+ (1,0) [0|255] "" Vector__XXX
 SG_ Byte5 : 40|8@1+ (1,0) [0|255] "" Vector__XXX
 SG_ Byte4 : 32|8@1+ (1,0) [0|255] "" Vector__XXX
 SG_ Byte3 : 24|8@1+ (1,0) [0|255] "" Vector__XXX
 SG_ Byte2 : 16|8@1+ (1,0) [0|255] "" Vector__XXX
 SG_ Byte1 : 8|8@1+ (1,0) [0|255] "" Vector__XXX
 SG_ SequenceNumber : 0|8@1+ (1,0) [1|255] "" Vector__XXX

BO_ 2563309310 ETP_CM: 8 Vector__XXX
 SG_ PGNumber : 40|24@1+ (1,0) [0|16777200] "" Vector__XXX
 SG_ DataPacketOffset m22 : 16|24@1+ (1,0) [0|16777215] "" Vector__XXX
 SG_ NextPacketNumberToSend m21 : 16|24@1+ (1,0) [1|16777215] "" Vector__XXX
 SG_ NumberOfBytesTransfered m23 : 8|32@1+ (1,0) [1786|117440505] "" Vector__XXX
 SG_ NumberOfPacketsOffset m22 : 8|8@1+ (1,0) [1|255] "" Vector__XXX
 SG_ NumberOfPacketsToSend m21 : 8|8@1+ (1,0) [1|255] "" Vector__XXX
 SG_ NumberOfBytesToTransfer m20 : 8|32@1+ (1,0) [1786|117440505] "" Vector__XXX
 SG_ ControlByte M : 0|8@1+ (1,0) [0|255] "" Vector__XXX
 SG_ ConnectionAbortReason m255 : 8|8@1+ (1,0) [0|255] "" Vector__XXX

BO_ 2314732030 GNSSPositionRapidUpdate: 8 Vector__XXX
 SG_ Longitude : 32|32@1- (1E-007,0) [-180|180] "deg" Vector__XXX
 SG_ Latitude : 0|32@1- (1E-007,0) [-90|90] "deg" Vector__XXX

BO_ 2583168510 GNSSPositionData: 47 Vector__XXX
 SG_ AgeOfDGNSSCorrections1 : 360|16@1+ (0.01,0) [0|655.32] "sec" Vector__XXX
 SG_ ReferenceStationID1 : 348|12@1+ (1,0) [0|4095] "" Vector__XXX
 SG_ RefrenceStationType1 : 344|4@1+ (1,0) [0|15] "" Vector__XXX
 SG_ NumberOfReferenceStations : 336|8@1+ (1,0) [0|252] "" Vector__XXX
 SG_ GeoidalSeparation : 304|32@1- (0.01,0) [-21470000|21470000] "m" Vector__XXX
 SG_ PDOP : 288|16@1- (0.01,0) [-327.64|327.64] "" Vector__XXX
 SG_ HDOP : 272|16@1- (0.01,0) [-327.64|327.64] "" Vector__XXX
 SG_ NumberOfSVs : 264|8@1+ (1,0) [0|252] "" Vector__XXX
 SG_ GNSSIntegrity : 256|2@1+ (1,0) [0|3] "" Vector__XXX
 SG_ GNSSMethod : 252|4@1+ (1,0) [0|15] "" Vector__XXX
 SG_ TypeOfSystem : 248|4@1+ (1,0) [0|4] "" Vector__XXX
 SG_ AltitudeHigh : 216|32@1- (4294.967295,0) [-1705215488|1705215488] "m" Vector__XXX
 SG_ AltitudeLow : 184|32@1+ (1E-006,0) [0|4294] "m" Vector__XXX
 SG_ LongitudeHigh : 152|32@1- (4.29497E-007,0) [-180|180] "deg" Vector__XXX
 SG_ LongitudeLow : 120|32@1+ (1E-016,0) [0|4.294E-007] "deg" Vector__XXX
 SG_ LatitudeHigh : 88|32@1- (4.29497E-007,0) [-90|90] "deg" Vector__XXX
 SG_ LatitudeLow : 56|32@1+ (1E-016,0) [0|4.294E-007] "deg" Vector__XXX
 SG_ PositionTime : 24|32@1+ (0.0001,0) [0|86401] "hour" Vector__XXX
 SG_ PositionDate : 8|16@1+ (1,0) [0|65532] "day" Vector__XXX
 SG_ SequenceID : 0|8@1+ (1,0) [0|255] "" Vector__XXX

BO_ 2583299838 GNSSPseudoRangeNoiseStatistic: 15 Vector__XXX
 SG_ STDofAltError : 104|16@1+ (0.01,0) [0|655.32] "m" Vector__XXX
 SG_ STDofLonError : 88|16@1+ (0.01,0) [0|655.32] "m" Vector__XXX
 SG_ STDofLatError : 72|16@1+ (0.01,0) [0|655.32] "m" Vector__XXX
 SG_ OrientationOfMinorAxis : 56|16@1+ (0.0001,0) [0|6.2832] "rad" Vector__XXX
 SG_ STDofMinorAxis : 40|16@1+ (0.01,0) [0|655.32] "m" Vector__XXX
 SG_ STDofMajorAxis : 24|16@1+ (0.01,0) [0|655.32] "m" Vector__XXX
 SG_ RMSofPositionUncertainty : 8|16@1+ (0.01,0) [0|655.32] "m" Vector__XXX
 SG_ SequenceID : 0|8@1+ (1,0) [0|255] "" Vector__XXX

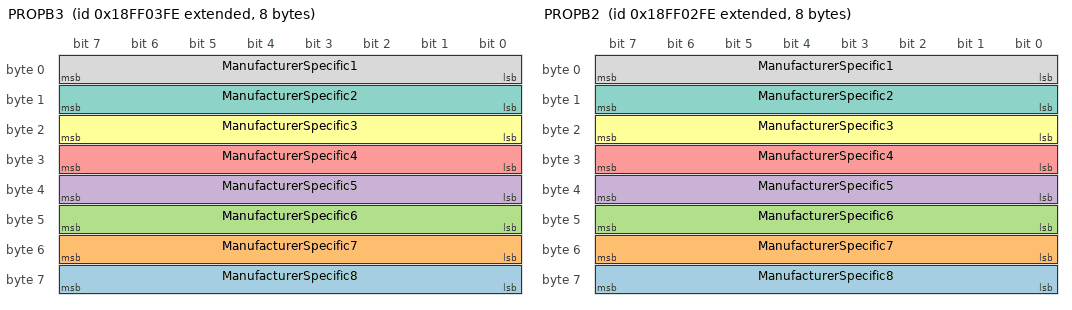
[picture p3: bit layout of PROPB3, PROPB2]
BO_ 2566849534 PROPB3: 8 Vector__XXX
 SG_ ManufacturerSpecific8 : 56|8@1+ (1,0) [0|255] "" Vector__XXX
 SG_ ManufacturerSpecific7 : 48|8@1+ (1,0) [0|255] "" Vector__XXX
 SG_ ManufacturerSpecific6 : 40|8@1+ (1,0) [0|255] "" Vector__XXX
 SG_ ManufacturerSpecific5 : 32|8@1+ (1,0) [0|255] "" Vector__XXX
 SG_ ManufacturerSpecific4 : 24|8@1+ (1,0) [0|255] "" Vector__XXX
 SG_ ManufacturerSpecific3 : 16|8@1+ (1,0) [0|255] "" Vector__XXX
 SG_ ManufacturerSpecific2 : 8|8@1+ (1,0) [0|255] "" Vector__XXX
 SG_ ManufacturerSpecific1 : 0|8@1+ (1,0) [0|255] "" Vector__XXX

BO_ 2566849278 PROPB2: 8 Vector__XXX
 SG_ ManufacturerSpecific8 : 56|8@1+ (1,0) [0|255] "" Vector__XXX
 SG_ ManufacturerSpecific7 : 48|8@1+ (1,0) [0|255] "" Vector__XXX
 SG_ ManufacturerSpecific6 : 40|8@1+ (1,0) [0|255] "" Vector__XXX
 SG_ ManufacturerSpecific5 : 32|8@1+ (1,0) [0|255] "" Vector__XXX
 SG_ ManufacturerSpecific4 : 24|8@1+ (1,0) [0|255] "" Vector__XXX
 SG_ ManufacturerSpecific3 : 16|8@1+ (1,0) [0|255] "" Vector__XXX
 SG_ ManufacturerSpecific2 : 8|8@1+ (1,0) [0|255] "" Vector__XXX
 SG_ ManufacturerSpecific1 : 0|8@1+ (1,0) [0|255] "" Vector__XXX

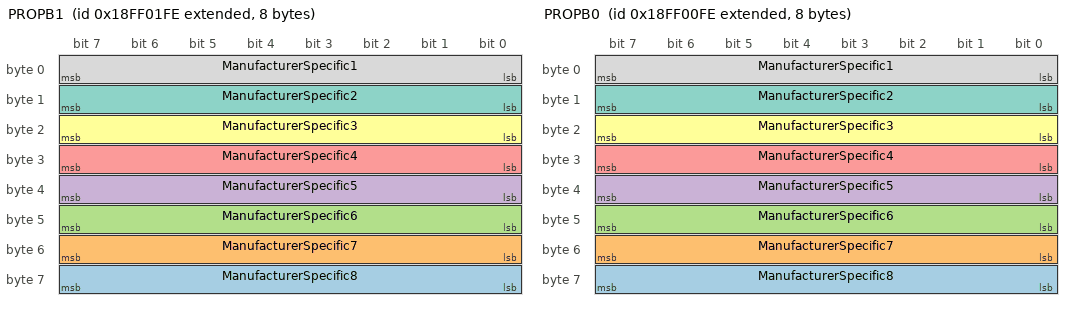
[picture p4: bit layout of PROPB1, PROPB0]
BO_ 2566849022 PROPB1: 8 Vector__XXX
 SG_ ManufacturerSpecific8 : 56|8@1+ (1,0) [0|255] "" Vector__XXX
 SG_ ManufacturerSpecific7 : 48|8@1+ (1,0) [0|255] "" Vector__XXX
 SG_ ManufacturerSpecific6 : 40|8@1+ (1,0) [0|255] "" Vector__XXX
 SG_ ManufacturerSpecific5 : 32|8@1+ (1,0) [0|255] "" Vector__XXX
 SG_ ManufacturerSpecific4 : 24|8@1+ (1,0) [0|255] "" Vector__XXX
 SG_ ManufacturerSpecific3 : 16|8@1+ (1,0) [0|255] "" Vector__XXX
 SG_ ManufacturerSpecific2 : 8|8@1+ (1,0) [0|255] "" Vector__XXX
 SG_ ManufacturerSpecific1 : 0|8@1+ (1,0) [0|255] "" Vector__XXX

BO_ 2566848766 PROPB0: 8 Vector__XXX
 SG_ ManufacturerSpecific8 : 56|8@1+ (1,0) [0|255] "" Vector__XXX
 SG_ ManufacturerSpecific7 : 48|8@1+ (1,0) [0|255] "" Vector__XXX
 SG_ ManufacturerSpecific6 : 40|8@1+ (1,0) [0|255] "" Vector__XXX
 SG_ ManufacturerSpecific5 : 32|8@1+ (1,0) [0|255] "" Vector__XXX
 SG_ ManufacturerSpecific4 : 24|8@1+ (1,0) [0|255] "" Vector__XXX
 SG_ ManufacturerSpecific3 : 16|8@1+ (1,0) [0|255] "" Vector__XXX
 SG_ ManufacturerSpecific2 : 8|8@1+ (1,0) [0|255] "" Vector__XXX
 SG_ ManufacturerSpecific1 : 0|8@1+ (1,0) [0|255] "" Vector__XXX

CM_ BO_ 3221225472 "This is a message for not used signals, created by Vector CANdb++ DBC OLE DB Provider.";
CM_ SG_ 3221225472 NumOfReportedFuncCharacteristics "Number of functionality characteristics reported in this message";
CM_ SG_ 3221225472 FirstListedFuncCharacteristic "This parameter reports which functionalities characteristics are supported by a control function connected to 
the ISO 11783 network.";
CM_ SG_ 3221225472 FirstListedFuncGen "This parameter reports the generation of the first listed functionality.";
CM_ SG_ 3221225472 VTFuncOptions "This parameter reports which VT functionality options are supported by an implement working set master or a 
VT that is connected to the ISO 11783 network. ";
CM_ SG_ 3221225472 TCBasicFuncOptions "This  parameter  reports  which  basic  task  controller  functionality  options  are  supported  by  an  implement 
working set master or a task controller that is connected to the ISO 11783 network.";
CM_ SG_ 3221225472 TCGeoSupportedChannels "This  parameter  reports  the  number  of  control  channels  are  required  by  a  TC-GEO  implement  working  set 
master or supported by a TC-GEO service type task controller that is connected to the ISO 11783 network. ";
CM_ SG_ 3221225472 TCGeoFuncOptions "This parameter reports which task controller geo functionality options are supported by an implement working 
set master or a task controller that is connected to the ISO 11783 network. ";
CM_ SG_ 3221225472 TCSectionNumberOfBooms "This parameter reports how many booms are required by an implement working set master or supported by a 
task controller geo that is connected to the ISO 11783 network. ";
CM_ SG_ 3221225472 TCSectionNumberOfSections "This parameter reports how many sections are required by an implement working set master or supported by 
a task controller geo that is connected to the ISO 11783 network. ";
CM_ SG_ 3221225472 SequenceControlFuncOptions "This parameter reports which sequence control (SQC) functionality options are supported by an implement 
working set master or a sequence control master that is connected to the ISO 11783 network. ";
CM_ SG_ 3221225472 StopAllImplementOperationsOption "This  parameter  reports  which  stop  all  implement  operations  functionality  options  are  supported  by  an 
implement working set master or a stop all implement operations input unit that is connected to the ISO 11783 
network. ";
CM_ SG_ 3221225472 DiagnosticOptions "This  parameter  reports  which  diagnostics  functionality  options  are  supported  by  a  controller  or  external 
diagnostic tool that is connected to the ISO 11783 network. ";
CM_ SG_ 3221225472 MachineSelSpeedExitReason "Parameter used to indicate why the vehicle speed control unit cannot currently accept remote commands or 
has most recently stopped accepting remote commands. ";
CM_ SG_ 3221225472 NumberOfOptionsBytes "This parameter reports the number of bytes that follow to report which options are supported by a functionality 
provided by a control function connected to the ISO 11783 network. ";
CM_ SG_ 3221225472 AuxControlType1FuncOptions "This  parameter  reports  which  Auxiliary  control  type  1  functionality  type  functions  are  supported  by  an 
implement working set auxiliary function or an auxiliary function input unit that is connected to the ISO 11783 
network. ";
CM_ SG_ 3221225472 CertTypeAuxControlFunc "Parameter used to indicate the type of compliance test performed. ";
CM_ SG_ 3221225472 CertTypeAuxControlInUnit "Parameter used to indicate the type of compliance test performed.";
CM_ SG_ 3221225472 CertTypeDataLogger "Parameter used to indicate the type of compliance test performed. ";
CM_ SG_ 3221225472 CertTypeDataLoggerWSMaster "Parameter used to indicate the type of compliance test performed. ";
CM_ SG_ 3221225472 CertTypeDataLoggerWSMember "Parameter used to indicate the type of compliance test performed. ";
CM_ SG_ 3221225472 CertTypeFileClient "Parameter used to indicate the type of compliance test performed. ";
CM_ SG_ 3221225472 CertTypeSecControlClient "Parameter used to indicate the type of compliance test performed. ";
CM_ SG_ 3221225472 CertTypeSeqControlMaster "Parameter used to indicate the type of compliance test performed. ";
CM_ SG_ 3221225472 CertTypeTCSectionControl "Parameter used to indicate the type of compliance test performed. ";
CM_ SG_ 3221225472 CertTypeTCSectionControlWSMember "Parameter used to indicate the type of compliance test performed. ";
CM_ BO_ 2565340673 "ECU to VT";
CM_ SG_ 2565340673 AuxErrorAnyOther "Any other error";
CM_ SG_ 2565340673 AuxErrorInvalidInputID "Invalid Auxiliary Input Object ID";
CM_ SG_ 2565340673 AuxInputEnable "Auxiliary Input Enable";
CM_ SG_ 2565340673 AuxModelIdentification "Model Identification Code of the Auxiliary Input Unit";
CM_ BO_ 2633895169 "Working Set Master";
CM_ BO_ 2565799425 "Address Claimed";
CM_ BO_ 2360147710 "Guidance Machine Status: It provides information and status from the steering control system to the guidance system.";
CM_ SG_ 2360147710 GuidSysComExitReasonCode "Parameter used to indicate why the guidance system cannot currently accept remote commands or has most 
recently stopped accepting remote commands. ";
CM_ SG_ 2360147710 GuidanceLimitStatus "Parameter used to report the Tractor ECU's present limit status associated with guidance commands that are 
persistent (i.e. not transient/temporary/one-shot). ";
CM_ SG_ 2360147710 RequestResetCommandStatus "The machine steering system request to the automatic guidance system to change Curvature Command Status state.";
CM_ SG_ 2360147710 SteeringInputPositionStatus "The machine steering system indicates if manual steering is in correct position for guidance to function.";
CM_ SG_ 2360147710 SteeringSystemReadiness "The machine steering system indicates that it is free from faults that would preclude guidance system operation.";
CM_ SG_ 2360147710 MechanicalSystemLockout "The state of a lockout switch that allows operators to disable automatic steering system functions.";
CM_ SG_ 2360147710 EstimatedCurvature "The machine steering system's estimate of the curvature of the current turn.";
CM_ BO_ 2360213246 "Guidance System Command";
CM_ SG_ 2360213246 CurvatureCommandStatus "This parameter indicates whether the guidance system is attempting to control steering with this command.";
CM_ SG_ 2360213246 CurvatureCommand "Desired course curvature over ground that a machine's steering system is required to achieve.";
CM_ BO_ 2563047166 "General Purpose valve command";
CM_ BO_ 2563112702 "General Purpose valve measured flow";
CM_ SG_ 2563112702 ValveLimitStatus "Parameter used to report the tractor ECUs present limit status associated with a parameter whose commands are persistent";
CM_ BO_ 2563178238 "General purpose valve estimated flow";
CM_ SG_ 2563178238 ValveLimitStatus "Parameter used to report the tractor ECUs present limit status associated with a parameter whose commands are persistent";
CM_ BO_ 2628452094 "File Client to Server";
CM_ SG_ 2628452094 VI_VolumeName "Length of path name string for Initailize Volume Request";
CM_ SG_ 2628452094 VI_Flag_OverwriteExisting "Create a new volume if not yet existing (fails if existing volume)";
CM_ SG_ 2628452094 MF_DestinationPathNameLength "Length of destination path name string for Move File";
CM_ SG_ 2628452094 RF_ReportHiddenFiles "Report Hidden Files";
CM_ SG_ 2628452094 SF_Offset "Offset for Seek File";
CM_ SG_ 2628452094 RF_Count "Number of bytes or number of directory entries to be read";
CM_ SG_ 2628452094 SF_PositionMode "Position Mode for Seek File";
CM_ SG_ 2628452094 OF_PathName "Length of path name string for Open File";
CM_ SG_ 2628452094 MF_SourcePathNameLength "Length of source path name string for Move File";
CM_ SG_ 2628452094 WF_Count "Byte count of data to be written to file";
CM_ SG_ 2628452094 DF_PathName "Length of path name string for Delete File";
CM_ SG_ 2628452094 SA_PathName "Length of path name string for Set File Attributes";
CM_ SG_ 2628452094 VI_Space "The space in units of 512";
CM_ SG_ 2628452094 OF_FlagExclusiveAccess "Open file with exclusive access (fails if already open)";
CM_ SG_ 2628452094 OF_FlagAppend "Open file for appending data to the end of the file";
CM_ SG_ 2628452094 SET_ATTR_Hidden "SetFile Attribute Hidden";
CM_ SG_ 2628452094 OF_FlagCreateNew "Create a new file if not yet existing";
CM_ SG_ 2628452094 MF_MoveModeRecursive "Recursive mode for Move File";
CM_ SG_ 2628452094 DF_DeleteModeRecursive "Recursive mode for Move File";
CM_ SG_ 2628452094 MF_MoveModeForce "Force mode for Move File";
CM_ SG_ 2628452094 DF_DeleteModeForce "Force mode for Move File";
CM_ SG_ 2628452094 VI_Flag_UsingSpaceSpecified "Create volume using space specified";
CM_ SG_ 2628452094 SET_ATTR_ReadOnly "SetFile Attribute Read-Only";
CM_ SG_ 2628452094 CF_Handle "Handle for Close File";
CM_ SG_ 2628452094 WF_Handle "Handle for Write File";
CM_ SG_ 2628452094 RF_Handle "Handle for Read File";
CM_ SG_ 2628452094 SF_Handle "Handle for Seek File";
CM_ SG_ 2628452094 OF_FlagReadWrite "Read/Write/Both/Directory Flag for Open File";
CM_ SG_ 2628452094 CCD_PathName "Length of path name string for Change Current Directory";
CM_ SG_ 2628452094 MF_MoveModeCopy "Copy mode for Move File";
CM_ SG_ 2628452094 DF_DeleteMode "Copy mode for Move File";
CM_ SG_ 2628452094 GA_PathName "Length of path name string for Get File Attributes";
CM_ SG_ 2628452094 FDT_PathName "Length of path name string for Get File Date and Time";
CM_ SG_ 2628452094 CCD_TAN "Transaction Number for Change Default Directory";
CM_ SG_ 2628452094 GCD_TAN "Transaction Number for Get Default Directory";
CM_ SG_ 2628452094 FDT_TAN "Transaction Number for Get File Data & Time";
CM_ SG_ 2628452094 SA_TAN "Transaction Number for Set File Attribute";
CM_ SG_ 2628452094 GA_TAN "Transaction Number for Get File Attribute";
CM_ SG_ 2628452094 RF_TAN "Transaction Number for Read File";
CM_ SG_ 2628452094 CF_TAN "Transaction Number for Close File";
CM_ SG_ 2628452094 WF_TAN "Transaction Number for Write File";
CM_ SG_ 2628452094 SF_TAN "Transaction Number for Seek File";
CM_ SG_ 2628452094 OF_TAN "Transaction Number for Open File";
CM_ SG_ 2628452094 MF_TAN "Transaction Number for Move File";
CM_ SG_ 2628452094 DF_TAN "Transaction Number for Delete File";
CM_ SG_ 2628452094 VI_TAN "Transaction Number for Initailize Volume Request";
CM_ SG_ 2628452094 FSClientCommand "File Server - Client Command";
CM_ BO_ 2628517630 "File Server to Client";
CM_ SG_ 2628517630 GCD_PathName "Length of path name string for Get Current Directory";
CM_ SG_ 2628517630 GCD_FreeSpace "Free Volume Space for Get Current Directory";
CM_ SG_ 2628517630 FDT_TimeHour "Hour of File Time";
CM_ SG_ 2628517630 FDT_TimeMinutes "Minutes of File Time";
CM_ SG_ 2628517630 FDT_TimeSeconds "Day of File Time";
CM_ SG_ 2628517630 FDT_DateYear "Year of File Date";
CM_ SG_ 2628517630 SF_Position "Position of Seek File response";
CM_ SG_ 2628517630 GA_Size "The number of bytes in a file.";
CM_ SG_ 2628517630 GA_ATTR_VolumeRemovable "Attribute Removable MediaAttribute Removable Media";
CM_ SG_ 2628517630 FDT_DateMonth "Month of File Date";
CM_ SG_ 2628517630 GA_ATTR_SupportsLongFilenames "File Attribute ArchiveFile Attribute Archive";
CM_ SG_ 2628517630 VI_ATTR_Directory "File Attribute DirectoryFile Attribute DirectoryFile Attribute DirectoryFile Attribute Directory";
CM_ SG_ 2628517630 GA_ATTR_IsVolume "File Attribute SystemFile Attribute System";
CM_ SG_ 2628517630 GA_ATTR_Hidden "File Attribute HiddenFile Attribute Hidden";
CM_ SG_ 2628517630 FDT_DateDay "Day of File Date";
CM_ SG_ 2628517630 GA_ATTR_ReadOnly "File Attribute Read-OnlyFile Attribute Read-Only";
CM_ SG_ 2628517630 OF_Handle "Handle for Open File";
CM_ SG_ 2628517630 GCD_TotalSpace "Total Volume Space for Get Current Directory";
CM_ SG_ 2628517630 RF_Count "Number of read bytes or number of read directory entries";
CM_ SG_ 2628517630 GSP_SupportMultipleVolumes "File Server Capabilities for Get File Server Properties";
CM_ SG_ 2628517630 WF_Count "Number of written bytes";
CM_ SG_ 2628517630 FDT_ErrorCode "Error Code for Get File Data & Time";
CM_ SG_ 2628517630 RF_ErrorCode "Error Code for Read File";
CM_ SG_ 2628517630 SF_ErrorCode "ErrorCode for Seek File";
CM_ SG_ 2628517630 FSNumberOfOpenFiles "Number of open files";
CM_ SG_ 2628517630 OF_ErrorCode "Error Code for Open File";
CM_ SG_ 2628517630 WF_ErrorCode "Error Code for Write File";
CM_ SG_ 2628517630 CF_ErrorCode "Error Code for Close File";
CM_ SG_ 2628517630 MF_ErrorCode "Error Code for Move File";
CM_ SG_ 2628517630 GA_ErrorCode "Error Code for Get File Attribute";
CM_ SG_ 2628517630 SA_ErrorCode "Error Code for Set File Attribute";
CM_ SG_ 2628517630 GCD_ErrorCode "ErrorCode for Get Current Directory";
CM_ SG_ 2628517630 CCD_ErrorCode "Error Code for Change Current Directory";
CM_ SG_ 2628517630 GSP_MaxNrSimultaneousFilesOpen "The number of files that can maximally be opened simultaneous at the File Server.";
CM_ SG_ 2628517630 DF_ErrorCode "Error Code for Delete File";
CM_ SG_ 2628517630 VI_ErrorCode "Error Code for Volume Initialization";
CM_ SG_ 2628517630 FSBusyWriting "Busy writing";
CM_ SG_ 2628517630 FSBusyReading "Busy reading";
CM_ SG_ 2628517630 OF_TAN "Transaction Number for Open File";
CM_ SG_ 2628517630 SF_TAN "Transaction Number for Seek File";
CM_ SG_ 2628517630 RF_TAN "Transaction Number for Rename File";
CM_ SG_ 2628517630 WF_TAN "Transaction Number for Write File";
CM_ SG_ 2628517630 CF_TAN "Transaction Number for Close File";
CM_ SG_ 2628517630 MF_TAN "Transaction Number for Move File";
CM_ SG_ 2628517630 GA_TAN "Transaction Number for Get File Attributes";
CM_ SG_ 2628517630 SA_TAN "Transaction Number for Set File Attributes";
CM_ SG_ 2628517630 FDT_TAN "Transaction Number for Get File Data & Time";
CM_ SG_ 2628517630 GCD_TAN "Transaction Number for Get Current Directory";
CM_ SG_ 2628517630 CCD_TAN "Transaction Number for Change Current Directory";
CM_ SG_ 2628517630 GSP_VersionNumber "The version of ISO11783-13 that this File Server meets.";
CM_ SG_ 2628517630 DF_TAN "Transaction Number for Delete File";
CM_ SG_ 2628517630 VI_TAN "Transaction Number for Volume Initialization";
CM_ SG_ 2628517630 FSServerCommand "File Server Command";
CM_ BO_ 2364540158 "Electronic Engine Controller #1";
CM_ SG_ 2364540158 EngStarterMode "There are several phases in a starting action and different reasons why a start cannot take place.";
CM_ SG_ 2364540158 SrcAddrssOfCtrllngDvcForEngCtrl "The source address of the SAE J1939 device currently controlling the engine.";
CM_ SG_ 2364540158 ActualEngPercentTorque "The calculated output torque of the engine.";
CM_ SG_ 2364540158 DriversDemandEngPercentTorque "The requested torque output of the engine by the driver.";
CM_ SG_ 2364540158 EngTorqueMode "State signal which indicates which engine torque mode is currently generating, limiting, or controlling the torque.";
CM_ SG_ 2364540158 ActlEngPrcntTorqueHighResolution "This parameter displays an additional torque in percent of the reference engine torque.";
CM_ BO_ 2563243774 "Extended TP (Data)";
CM_ BO_ 2563309310 "Extended TP (Command)";
CM_ BO_ 2314732030 "This PGN provides latitude and longitude referenced to WGS84";
CM_ BO_ 2583168510 "This PGN conveys a comprehensive set of Global Navigation Satellite System (GNSS) parameters, including position 
information
";
CM_ SG_ 2583168510 AgeOfDGNSSCorrections1 "Age of Differential corrections";
CM_ SG_ 2583168510 ReferenceStationID1 "Reference Station ID";
CM_ SG_ 2583168510 NumberOfReferenceStations "Numeric count, event counter, sequence counter";
CM_ SG_ 2583168510 GeoidalSeparation "The difference between the earth ellipsoid and mean-sea-level (geoid) defined by the reference datum used in the position solution ' -' = mean-sea-level below ellipsoid
";
CM_ SG_ 2583168510 PDOP "Dilution of Precision (DOP) indicates the contribution of satellite configuration geometry to positioning error
";
CM_ SG_ 2583168510 HDOP "Dilution of Precision (DOP) indicates the contribution of satellite configuration geometry to positioning error
";
CM_ SG_ 2583168510 NumberOfSVs "Numeric count, event counter, sequence counter";
CM_ SG_ 2583168510 AltitudeHigh "Altitude referenced to WGS-84";
CM_ SG_ 2583168510 AltitudeLow "Altitude referenced to WGS-84";
CM_ SG_ 2583168510 LongitudeHigh "Longitude referenced to WGS-84";
CM_ SG_ 2583168510 LongitudeLow "Longitude referenced to WGS-84";
CM_ SG_ 2583168510 LatitudeHigh "Latitude referenced to WGS-84";
CM_ SG_ 2583168510 LatitudeLow "Latitude referenced to WGS-84";
CM_ SG_ 2583168510 PositionTime "24 hour clock, 0 =  midnight,  time is in UTC";
CM_ SG_ 2583168510 PositionDate "Days since January 1, 1970,  Date is relative to UTC Time";
CM_ SG_ 2583168510 SequenceID "An upward counting number used to tie related information together between different PGNs.
";
CM_ BO_ 2583299838 "GNSS pseudorange measurement noise statistics can be translated in the position domain in order to give statistical measures 
of the quality of the position solution. Intended for use with a Receiver Autonomous Integrity Monitoring (RAIM) application.
";
CM_ SG_ 2583299838 STDofAltError "Error distances expressed in meters";
CM_ SG_ 2583299838 STDofLonError "Error distances expressed in meters";
CM_ SG_ 2583299838 STDofLatError "Error distances expressed in meters.";
CM_ SG_ 2583299838 OrientationOfMinorAxis "Degrees clockwise relative to True North.";
CM_ SG_ 2583299838 STDofMinorAxis "Error distances expressed in meters.";
CM_ SG_ 2583299838 STDofMajorAxis "Error distances expressed in meters.";
CM_ SG_ 2583299838 RMSofPositionUncertainty "Error distances expressed in meters.";
CM_ SG_ 2583299838 SequenceID "An upward counting number used to tie related information together between different PGNs.
";
CM_ BO_ 2566849534 "Proprietary B3";
CM_ BO_ 2566849278 "Proprietary B2";
CM_ BO_ 2566849022 "Proprietary B1";
CM_ BO_ 2566848766 "Proprietary B0";
BA_DEF_  "ISO11783_11_SpecVersion" STRING ;
BA_DEF_  "ISO11783_7_SpecVersion" STRING ;
BA_DEF_  "ISO11783_6_SpecVersion" STRING ;
BA_DEF_ SG_  "DDI" INT 0 65535;
BA_DEF_ BO_  "SingleFrame" INT 0 1;
BA_DEF_ BU_  "NodeLayerModules" STRING ;
BA_DEF_  "ProtocolType" STRING ;
BA_DEF_  "BusType" STRING ;
BA_DEF_ BU_  "NmStationAddress" INT 0 255;
BA_DEF_ BU_  "NmJ1939AAC" INT 0 1;
BA_DEF_ BU_  "NmJ1939IndustryGroup" INT 0 7;
BA_DEF_ BU_  "NmJ1939Function" INT 0 255;
BA_DEF_ BU_  "NmJ1939FunctionInstance" INT 0 7;
BA_DEF_ BU_  "NmJ1939ManufacturerCode" INT 0 2047;
BA_DEF_ BU_  "NmJ1939IdentityNumber" INT 0 2097151;
BA_DEF_ BO_  "VFrameFormat" ENUM  "StandardCAN","ExtendedCAN","reserved","J1939PG","vector_leerstring";
BA_DEF_ BO_  "GenMsgSendType" ENUM  "cyclic","NotUsed","IfActive","NotUsed","NotUsed","NotUsed","NotUsed","NotUsed","noMsgSendType","vector_leerstring";
BA_DEF_ BO_  "GenMsgCycleTime" INT 0 3600000;
BA_DEF_ BO_  "GenMsgRequestable" INT 0 1;
BA_DEF_ BO_  "GenMsgCycleTimeFast" INT 0 3600000;
BA_DEF_ SG_  "SPN" INT 0 524287;
BA_DEF_  "DatabaseVersion" STRING ;
BA_DEF_ SG_  "GenSigSendType" ENUM  "Cyclic","OnWrite","OnWriteWithRepetition","OnChange","OnChangeWithRepetition","IfActive","IfActiveWithRepetition","NoSigSendType";
BA_DEF_ SG_  "SigType" ENUM  "Default","Range","RangeSigned","ASCII","Discrete","Control","ReferencePGN","DTC","StringDelimiter","StringLength","StringLengthControl","MessageCounter","MessageChecksum";
BA_DEF_  "ISO11783_12_SpecVersion" STRING ;
BA_DEF_  "ISO11783_13_SpecVersion" STRING ;
BA_DEF_ SG_  "GenSigStartValue" INT -2147483648 2147483647;
BA_DEF_ BU_  "ISO11783IOPVersion" ENUM  "0","1","2","3","4";
BA_DEF_ BU_  "ISO11783PDDVersion" ENUM  "0","1","2","3";
BA_DEF_ SG_  "SystemSignalLongSymbol" STRING ;
BA_DEF_DEF_  "ISO11783_11_SpecVersion" "";
BA_DEF_DEF_  "ISO11783_7_SpecVersion" "";
BA_DEF_DEF_  "ISO11783_6_SpecVersion" "";
BA_DEF_DEF_  "DDI" 0;
BA_DEF_DEF_  "SingleFrame" 1;
BA_DEF_DEF_  "NodeLayerModules" "";
BA_DEF_DEF_  "ProtocolType" "";
BA_DEF_DEF_  "BusType" "";
BA_DEF_DEF_  "NmStationAddress" 254;
BA_DEF_DEF_  "NmJ1939AAC" 0;
BA_DEF_DEF_  "NmJ1939IndustryGroup" 0;
BA_DEF_DEF_  "NmJ1939Function" 0;
BA_DEF_DEF_  "NmJ1939FunctionInstance" 0;
BA_DEF_DEF_  "NmJ1939ManufacturerCode" 0;
BA_DEF_DEF_  "NmJ1939IdentityNumber" 0;
BA_DEF_DEF_  "VFrameFormat" "J1939PG";
BA_DEF_DEF_  "GenMsgSendType" "noMsgSendType";
BA_DEF_DEF_  "GenMsgCycleTime" 0;
BA_DEF_DEF_  "GenMsgRequestable" 1;
BA_DEF_DEF_  "GenMsgCycleTimeFast" 0;
BA_DEF_DEF_  "SPN" 0;
BA_DEF_DEF_  "DatabaseVersion" "";
BA_DEF_DEF_  "GenSigSendType" "NoSigSendType";
BA_DEF_DEF_  "SigType" "Default";
BA_DEF_DEF_  "ISO11783_12_SpecVersion" "";
BA_DEF_DEF_  "ISO11783_13_SpecVersion" "";
BA_DEF_DEF_  "GenSigStartValue" 0;
BA_DEF_DEF_  "ISO11783IOPVersion" "3";
BA_DEF_DEF_  "ISO11783PDDVersion" "3";
BA_DEF_DEF_  "SystemSignalLongSymbol" "";
BA_ "ISO11783_12_SpecVersion" "2013-01-29 IS (ISO/TC 23/SC 19)";
BA_ "DatabaseVersion" "7.5 SP2";
BA_ "ProtocolType" "ISO11783";
BA_ "ISO11783_6_SpecVersion" "2010-05-11 FDIS";
BA_ "ISO11783_7_SpecVersion" "2009-01-29 FDIS";
BA_ "ISO11783_11_SpecVersion" "2007-04-01 IS";
BA_ "BusType" "CAN";
BA_ "ISO11783_13_SpecVersion" "2010-01-29 2007 With Amendments ";
BA_ "NmJ1939FunctionInstance" BU_ VT3 2;
BA_ "NmStationAddress" BU_ VT3 40;
BA_ "NmJ1939AAC" BU_ VT3 1;
BA_ "NmJ1939IndustryGroup" BU_ VT3 2;
BA_ "NmJ1939Function" BU_ VT3 29;
BA_ "NmJ1939ManufacturerCode" BU_ VT3 1861;
BA_ "NmJ1939IdentityNumber" BU_ VT3 3;
BA_ "NmJ1939FunctionInstance" BU_ VT2 1;
BA_ "NmStationAddress" BU_ VT2 39;
BA_ "NmJ1939AAC" BU_ VT2 1;
BA_ "NmJ1939IndustryGroup" BU_ VT2 2;
BA_ "NmJ1939Function" BU_ VT2 29;
BA_ "NmJ1939ManufacturerCode" BU_ VT2 1861;
BA_ "NmJ1939IdentityNumber" BU_ VT2 2;
BA_ "NmStationAddress" BU_ VT1 38;
BA_ "NmJ1939AAC" BU_ VT1 1;
BA_ "NmJ1939IndustryGroup" BU_ VT1 2;
BA_ "NmJ1939Function" BU_ VT1 29;
BA_ "NmJ1939ManufacturerCode" BU_ VT1 1861;
BA_ "NmJ1939IdentityNumber" BU_ VT1 1;
BA_ "NmStationAddress" BU_ Implement 1;
BA_ "NmJ1939AAC" BU_ Implement 1;
BA_ "NmJ1939IdentityNumber" BU_ Implement 1111;
BA_ "NodeLayerModules" BU_ Implement "ISO11783_IL.dll";
BA_ "GenMsgSendType" BO_ 2565340673 2;
BA_ "GenMsgCycleTime" BO_ 2565340673 1000;
BA_ "GenMsgSendType" BO_ 2364597502 0;
BA_ "GenMsgCycleTime" BO_ 2364597502 100;
BA_ "GenMsgSendType" BO_ 2360147710 8.48332452797837E-317;
BA_ "GenMsgCycleTime" BO_ 2360147710 100;
BA_ "GenMsgSendType" BO_ 2360213246 8.48390950170305E-317;
BA_ "GenMsgCycleTime" BO_ 2360213246 100;
BA_ "GenMsgSendType" BO_ 2563047166 8.48466048148473E-317;
BA_ "GenMsgCycleTime" BO_ 2563047166 1000;
BA_ "GenMsgSendType" BO_ 2563112702 8.48555770469758E-317;
BA_ "GenMsgCycleTime" BO_ 2563112702 100;
BA_ "GenMsgSendType" BO_ 2563178238 8.48652212083826E-317;
BA_ "GenMsgCycleTime" BO_ 2563178238 100;
BA_ "GenMsgSendType" BO_ 2314732030 8.51951780093012E-317;
BA_ "GenMsgCycleTime" BO_ 2314732030 100;
BA_ "GenMsgSendType" BO_ 2583168510 8.52390115134002E-317;
BA_ "GenMsgCycleTime" BO_ 2583168510 100;
BA_ "SingleFrame" BO_ 2583168510 0;
BA_ "GenMsgSendType" BO_ 2583299838 8.52558097453588E-317;
BA_ "GenMsgCycleTime" BO_ 2583299838 1000;
BA_ "SingleFrame" BO_ 2583299838 0;
BA_ "GenMsgSendType" BO_ 2566849534 8.52715012702708E-317;
BA_ "GenMsgCycleTime" BO_ 2566849534 100;
BA_ "GenMsgSendType" BO_ 2566849278 8.52871927951827E-317;
BA_ "GenMsgCycleTime" BO_ 2566849278 100;
BA_ "GenMsgSendType" BO_ 2566849022 8.53028843200946E-317;
BA_ "GenMsgCycleTime" BO_ 2566849022 100;
BA_ "GenMsgSendType" BO_ 2566848766 8.53185758450065E-317;
BA_ "GenMsgCycleTime" BO_ 2566848766 100;
BA_ "GenSigStartValue" SG_ 3221225472 TCSectionNumberOfBooms 1;
BA_ "GenSigStartValue" SG_ 3221225472 TCSectionNumberOfSections 1;
BA_ "SystemSignalLongSymbol" SG_ 3221225472 AdvanceTECU_MotionInitiationOpti "AdvanceTECU_MotionInitiationOption";
BA_ "SystemSignalLongSymbol" SG_ 3221225472 StopAllImplementOperationsOption "StopAllImplementOperationsOptions";
BA_ "SPN" SG_ 3221225472 MachineSelSpeedExitReason 5818;
BA_ "SPN" SG_ 2565340673 ArbitraryAddressCapable 2844;
BA_ "SPN" SG_ 2565340673 IndustryGroup 2846;
BA_ "SPN" SG_ 2565340673 VehicleSystemInstance 2843;
BA_ "SPN" SG_ 2565340673 Function 2841;
BA_ "SPN" SG_ 2565340673 FunctionInstance 2839;
BA_ "SPN" SG_ 2565340673 ECUInstance 2840;
BA_ "SigType" SG_ 2565340673 NewStringValue 9;
BA_ "SigType" SG_ 2565340673 ManufacturerCode 1;
BA_ "SPN" SG_ 2565340673 ManufacturerCode 2838;
BA_ "SPN" SG_ 2565340673 IdentityNumber 2837;
BA_ "SigType" SG_ 2565340673 ExtendedVersionLabelToDelete 3;
BA_ "SigType" SG_ 2565340673 ExtendedVersionLabelToLoad 3;
BA_ "SigType" SG_ 2565340673 ExtendedVersionLabelToStore 3;
BA_ "SigType" SG_ 2565340673 VersionLabelToDelete 3;
BA_ "SigType" SG_ 2565340673 VersionLabelToLoad 3;
BA_ "SigType" SG_ 2565340673 VersionLabelToStore 3;
BA_ "SystemSignalLongSymbol" SG_ 2565340673 ChangeChildLocationParentObjectI "ChangeChildLocationParentObjectID";
BA_ "SystemSignalLongSymbol" SG_ 2565340673 ChangeChildPositionParentObjectI "ChangeChildPositionParentObjectID";
BA_ "SigType" SG_ 2633895169 NumberOfMembers 3;
BA_ "SPN" SG_ 2565799425 ArbitraryAddressCapable 2844;
BA_ "SPN" SG_ 2565799425 IndustryGroup 2846;
BA_ "SPN" SG_ 2565799425 VehicleSystemInstance 2843;
BA_ "SPN" SG_ 2565799425 Function 2841;
BA_ "SPN" SG_ 2565799425 FunctionInstance 2839;
BA_ "SPN" SG_ 2565799425 ECUInstance 2840;
BA_ "SigType" SG_ 2565799425 ManufacturerCode 1;
BA_ "SPN" SG_ 2565799425 ManufacturerCode 2838;
BA_ "SPN" SG_ 2565799425 IdentityNumber 2837;
BA_ "SPN" SG_ 2364597502 HeartbeatSequenceNumber 7345;
BA_ "SigType" SG_ 2364597502 HeartbeatSequenceNumber 1;
BA_ "SPN" SG_ 2360147710 GuidSysComExitReasonCode 5725;
BA_ "SPN" SG_ 2360147710 GuidanceLimitStatus 5726;
BA_ "SigType" SG_ 2360147710 RequestResetCommandStatus 4;
BA_ "SPN" SG_ 2360147710 RequestResetCommandStatus 5240;
BA_ "SigType" SG_ 2360147710 SteeringInputPositionStatus 4;
BA_ "SPN" SG_ 2360147710 SteeringInputPositionStatus 5241;
BA_ "SigType" SG_ 2360147710 SteeringSystemReadiness 4;
BA_ "SPN" SG_ 2360147710 SteeringSystemReadiness 5242;
BA_ "SigType" SG_ 2360147710 MechanicalSystemLockout 4;
BA_ "SPN" SG_ 2360147710 MechanicalSystemLockout 5243;
BA_ "SigType" SG_ 2360147710 EstimatedCurvature 1;
BA_ "SPN" SG_ 2360147710 EstimatedCurvature 5238;
BA_ "SigType" SG_ 2360213246 CurvatureCommandStatus 4;
BA_ "SPN" SG_ 2360213246 CurvatureCommandStatus 5239;
BA_ "SigType" SG_ 2360213246 CurvatureCommand 1;
BA_ "SPN" SG_ 2360213246 CurvatureCommand 5237;
BA_ "SigType" SG_ 2563047166 FailSaveModeCmd 4;
BA_ "SPN" SG_ 2563047166 StateCmd 2933;
BA_ "SPN" SG_ 2563047166 PortFlowCmd 2944;
BA_ "SigType" SG_ 2563047166 PortFlowCmd 1;
BA_ "SPN" SG_ 2563112702 ValveLimitStatus 5192;
BA_ "SPN" SG_ 2563112702 ReturnPortPressure 2943;
BA_ "SigType" SG_ 2563112702 ReturnPortPressure 1;
BA_ "SPN" SG_ 2563112702 RetractPortPressure 2942;
BA_ "SigType" SG_ 2563112702 RetractPortPressure 1;
BA_ "SPN" SG_ 2563112702 ExtendedPortPressure 2941;
BA_ "SigType" SG_ 2563112702 ExtendedPortPressure 1;
BA_ "SPN" SG_ 2563112702 RetractPortMeasuredFlow 2938;
BA_ "SigType" SG_ 2563112702 RetractPortMeasuredFlow 1;
BA_ "SPN" SG_ 2563112702 ExtendedPortMeasuredFlow 2937;
BA_ "SigType" SG_ 2563112702 ExtendedPortMeasuredFlow 1;
BA_ "SPN" SG_ 2563178238 ValveLimitStatus 5193;
BA_ "SPN" SG_ 2563178238 FailSafeMode 2934;
BA_ "SigType" SG_ 2563178238 FailSafeMode 4;
BA_ "SPN" SG_ 2563178238 ValveState 2932;
BA_ "SPN" SG_ 2563178238 RetractPortEstimatedFlow 2940;
BA_ "SigType" SG_ 2563178238 RetractPortEstimatedFlow 1;
BA_ "SPN" SG_ 2563178238 ExtendedPortEstimatedFlow 2939;
BA_ "SigType" SG_ 2563178238 ExtendedPortEstimatedFlow 1;
BA_ "SigType" SG_ 2628452094 VI_VolumeName 9;
BA_ "SigType" SG_ 2628452094 OF_PathName 9;
BA_ "SigType" SG_ 2628452094 DF_PathName 9;
BA_ "SigType" SG_ 2628452094 SA_PathName 9;
BA_ "SigType" SG_ 2628452094 CCD_PathName 9;
BA_ "SigType" SG_ 2628452094 GA_PathName 9;
BA_ "SigType" SG_ 2628452094 FDT_PathName 9;
BA_ "SigType" SG_ 2628452094 VS_VolumeName 8;
BA_ "SystemSignalLongSymbol" SG_ 2628452094 VS_RequestVolumeToPrepareForRemo "VS_RequestVolumeToPrepareForRemoval";
BA_ "SigType" SG_ 2628517630 GCD_PathName 9;
BA_ "SigType" SG_ 2628517630 VS_VolumeName 9;
BA_ "SPN" SG_ 2364540158 EngDemandPercentTorque 2432;
BA_ "SigType" SG_ 2364540158 EngDemandPercentTorque 1;
BA_ "SPN" SG_ 2364540158 EngStarterMode 1675;
BA_ "SPN" SG_ 2364540158 SrcAddrssOfCtrllngDvcForEngCtrl 1483;
BA_ "SPN" SG_ 2364540158 EngSpeed 190;
BA_ "SigType" SG_ 2364540158 EngSpeed 1;
BA_ "SPN" SG_ 2364540158 ActualEngPercentTorque 513;
BA_ "SigType" SG_ 2364540158 ActualEngPercentTorque 1;
BA_ "SPN" SG_ 2364540158 DriversDemandEngPercentTorque 512;
BA_ "SigType" SG_ 2364540158 DriversDemandEngPercentTorque 1;
BA_ "SPN" SG_ 2364540158 EngTorqueMode 899;
BA_ "SPN" SG_ 2364540158 ActlEngPrcntTorqueHighResolution 4154;
BA_ "SigType" SG_ 2563243774 Byte7 1;
BA_ "SigType" SG_ 2563243774 Byte6 1;
BA_ "SigType" SG_ 2563243774 Byte5 1;
BA_ "SigType" SG_ 2563243774 Byte4 1;
BA_ "SigType" SG_ 2563243774 Byte3 1;
BA_ "SigType" SG_ 2563243774 Byte2 1;
BA_ "SigType" SG_ 2563243774 Byte1 1;
BA_ "SigType" SG_ 2563243774 SequenceNumber 1;
BA_ "GenSigStartValue" SG_ 2563243774 SequenceNumber 1;
BA_ "SigType" SG_ 2563309310 PGNumber 6;
BA_ "SigType" SG_ 2563309310 DataPacketOffset 1;
BA_ "SigType" SG_ 2563309310 NextPacketNumberToSend 1;
BA_ "GenSigStartValue" SG_ 2563309310 NextPacketNumberToSend 1;
BA_ "SigType" SG_ 2563309310 NumberOfBytesTransfered 1;
BA_ "GenSigStartValue" SG_ 2563309310 NumberOfBytesTransfered 1786;
BA_ "SigType" SG_ 2563309310 NumberOfPacketsOffset 1;
BA_ "GenSigStartValue" SG_ 2563309310 NumberOfPacketsOffset 1;
BA_ "SigType" SG_ 2563309310 NumberOfPacketsToSend 1;
BA_ "GenSigStartValue" SG_ 2563309310 NumberOfPacketsToSend 1;
BA_ "SigType" SG_ 2563309310 NumberOfBytesToTransfer 1;
BA_ "GenSigStartValue" SG_ 2563309310 NumberOfBytesToTransfer 1786;
BA_ "SigType" SG_ 2563309310 ControlByte 1;
BA_ "SigType" SG_ 2583168510 AgeOfDGNSSCorrections1 1;
BA_ "SigType" SG_ 2583168510 ReferenceStationID1 1;
BA_ "SigType" SG_ 2583168510 NumberOfReferenceStations 1;
BA_ "SigType" SG_ 2583168510 GeoidalSeparation 2;
BA_ "SigType" SG_ 2583168510 PDOP 2;
BA_ "SigType" SG_ 2583168510 HDOP 2;
BA_ "SigType" SG_ 2583168510 NumberOfSVs 1;
BA_ "SigType" SG_ 2583168510 GNSSIntegrity 4;
BA_ "SigType" SG_ 2583168510 LongitudeLow 1;
BA_ "SigType" SG_ 2583168510 LatitudeLow 1;
BA_ "SigType" SG_ 2583168510 PositionTime 1;
BA_ "SigType" SG_ 2583168510 PositionDate 1;
BA_ "SigType" SG_ 2583168510 SequenceID 1;
BA_ "SigType" SG_ 2583299838 STDofAltError 1;
BA_ "SigType" SG_ 2583299838 STDofLonError 1;
BA_ "SigType" SG_ 2583299838 STDofLatError 1;
BA_ "SigType" SG_ 2583299838 OrientationOfMinorAxis 1;
BA_ "SigType" SG_ 2583299838 STDofMinorAxis 1;
BA_ "SigType" SG_ 2583299838 STDofMajorAxis 1;
BA_ "SigType" SG_ 2583299838 RMSofPositionUncertainty 1;
BA_ "SigType" SG_ 2583299838 SequenceID 1;
BA_ "SigType" SG_ 2566849534 ManufacturerSpecific8 1;
BA_ "SigType" SG_ 2566849534 ManufacturerSpecific7 1;
BA_ "SigType" SG_ 2566849534 ManufacturerSpecific6 1;
BA_ "SigType" SG_ 2566849534 ManufacturerSpecific5 1;
BA_ "SigType" SG_ 2566849534 ManufacturerSpecific4 1;
BA_ "SigType" SG_ 2566849534 ManufacturerSpecific3 1;
BA_ "SigType" SG_ 2566849534 ManufacturerSpecific2 1;
BA_ "SigType" SG_ 2566849534 ManufacturerSpecific1 1;
BA_ "SigType" SG_ 2566849278 ManufacturerSpecific8 1;
BA_ "SigType" SG_ 2566849278 ManufacturerSpecific7 1;
BA_ "SigType" SG_ 2566849278 ManufacturerSpecific6 1;
BA_ "SigType" SG_ 2566849278 ManufacturerSpecific5 1;
BA_ "SigType" SG_ 2566849278 ManufacturerSpecific4 1;
BA_ "SigType" SG_ 2566849278 ManufacturerSpecific3 1;
BA_ "SigType" SG_ 2566849278 ManufacturerSpecific2 1;
BA_ "SigType" SG_ 2566849278 ManufacturerSpecific1 1;
BA_ "SigType" SG_ 2566849022 ManufacturerSpecific8 1;
BA_ "SigType" SG_ 2566849022 ManufacturerSpecific7 1;
BA_ "SigType" SG_ 2566849022 ManufacturerSpecific6 1;
BA_ "SigType" SG_ 2566849022 ManufacturerSpecific5 1;
BA_ "SigType" SG_ 2566849022 ManufacturerSpecific4 1;
BA_ "SigType" SG_ 2566849022 ManufacturerSpecific3 1;
BA_ "SigType" SG_ 2566849022 ManufacturerSpecific2 1;
BA_ "SigType" SG_ 2566849022 ManufacturerSpecific1 1;
BA_ "SigType" SG_ 2566848766 ManufacturerSpecific8 1;
BA_ "SigType" SG_ 2566848766 ManufacturerSpecific7 1;
BA_ "SigType" SG_ 2566848766 ManufacturerSpecific6 1;
BA_ "SigType" SG_ 2566848766 ManufacturerSpecific5 1;
BA_ "SigType" SG_ 2566848766 ManufacturerSpecific4 1;
BA_ "SigType" SG_ 2566848766 ManufacturerSpecific3 1;
BA_ "SigType" SG_ 2566848766 ManufacturerSpecific2 1;
BA_ "SigType" SG_ 2566848766 ManufacturerSpecific1 1;
VAL_ 3221225472 FirstListedFuncCharacteristic 0 "No functionalities reported " 1 "Virtual terminal " 2 "Virtual terminal working set " 3 "Auxiliary control Type 1 inputs " 4 "Auxiliary control Type 1 functions " 5 "Auxiliary control Type 2 inputs " 6 "Auxiliary control Type 2 functions" 7 "Task controller basic" 8 "Task controller basic working set " 9 "Task controller geo  " 10 "Task controller geo working set " 11 "Task controller section control " 12 "Task controller section control working set " 13 "Basic Tractor ECU  " 14 "Basic Tractor ECU implement set " 15 "Advance Tractor ECU  " 16 "Advance Tractor ECU implement set " 17 "File server " 18 "File server client " 19 "Sequence control server" 20 "Sequence control client " 21 "Stop all implement operations input" 22 "Stop all implement operations implement set " 23 "Diagnostic tool " 24 "Diagnostic ECU " 253 "Error indication" 254 "Not available" ;
VAL_ 3221225472 MachineSelSpeedExitReason 0 "No reason/all clear " 1 "Operator presence not detected" 2 "Implement released control of function " 3 "Operator override of function" 4 "Operator control not in valid position" 5 "Remote command timeout" 6 "Remote command out of range/invalid " 7 "Function not calibrated " 8 "Operator control fault " 9 "Function fault " 22 "Vehicle transmission gear does not allow remote commands" 62 "Error" 63 "Not available (parameter not supported)" ;
VAL_ 3221225472 CertTypeAuxControlFunc 0 "Not certified" 1 "Certification test performed" ;
VAL_ 3221225472 CertTypeAuxControlInUnit 0 "Not certified" 1 "Certification test performed" ;
VAL_ 3221225472 CertTypeDataLogger 0 "Not certified" 1 "Certification test performed" ;
VAL_ 3221225472 CertTypeDataLoggerWSMaster 0 "Not certified" 1 "Certification test performed" ;
VAL_ 3221225472 CertTypeDataLoggerWSMember 0 "Not certified" 1 "Certification test performed" ;
VAL_ 3221225472 CertTypeFileClient 0 "Not certified" 1 "Certification test performed" ;
VAL_ 3221225472 CertTypeSecControlClient 0 "Not certified" 1 "Certification test performed" ;
VAL_ 3221225472 CertTypeSeqControlMaster 0 "Not certified" 1 "Certification test performed" ;
VAL_ 3221225472 CertTypeTCSectionControl 0 "Not certified" 1 "Certification test performed" ;
VAL_ 3221225472 CertTypeTCSectionControlWSMember 0 "Not certified" 1 "Certification test performed" ;
VAL_ 2565340673 IndustryGroup 7 "Reserved for SAE" 5 "IndustrialProcessCtrlStationary" 4 "Marine" 3 "Construction" 2 "Agricultural and Forestry" 1 "On-Highway" 0 "Global" 6 "Reserved for SAE" ;
VAL_ 2565340673 VehicleSystem2 0 "Non-specific System" 127 "Not Available" 1 "Tractor" 2 "Tillage" 3 "Secondary Tillage" 4 "Planters/Seeders" 5 "Fertilizers" 6 "Sprayers" 7 "Harvesters" 8 "Root Harvesters" 9 "Forage" 10 "Irrigation" 11 "Transport/Trailer" 12 "Farm Yard Operations" 13 "Powered Auxiliary Device" 14 "Special Crops" 15 "Earth Work" 16 "Skidder" 17 "Sensor Systems" 19 "Timber Harvesters" 20 "Forwarders" 21 "Timber loaders" 22 "Timber Processing Machines" 23 "Mulchers" 24 "Utility Vehicles" 25 "Slurry Applicators" ;
VAL_ 2565340673 OperatingState2 0 "InputNotActivatedInLearnMode" 1 "InputActivatedInLearnMode" ;
VAL_ 2565340673 Function 43 "Transmission Display" 44 "Exhaust Emission Control" 45 "Vehicle Dynamic Stability Control" 46 "Oil Sensor Unit" 47 "Information System Controller" 48 "Ramp Control" 49 "Clutch/Converter Control" 50 "Auxiliary Heater" 51 "Forward-Looking Collision Warning System" 52 "Chassis Controller" 53 "Alternator/Charging System" 54 "Communications Unit, Cellular" 55 "Communications Unit, Satellite" 56 "Communications Unit, Radio" 57 "Steering Column Unit" 58 "Fan Drive Control" 59 "Starter" 60 "Cab Display" 61 "File Server/Printer" 62 "On-Board Diagnostic Unit" 63 "Engine Valve Controller" 64 "Endurance Braking" 65 "Gas Flow Measurement" 66 "I/O Controller" 67 "Electrical System Controller" 68 "Aftertreatment system gas measurement" 69 "Engine Emission Aftertreatement System" 70 "Auxiliary Regeneration Device" 71 "Transfer Case Control" 72 "Coolant Valve Controller" 73 "Rollover Detection Control" 74 "Lubrication System" 75 "Supplemental Fan" 76 "Temperature Sensor" 77 "Fuel Properties Sensor" 78 "Fire Suppression System" 79 "Reserved" 80 "Reserved" 81 "Reserved" 82 "Reserved" 83 "Reserved" 84 "Reserved" 85 "Reserved" 86 "Reserved" 87 "Reserved" 88 "Reserved" 89 "Reserved" 90 "Reserved" 91 "Reserved" 92 "Reserved" 93 "Reserved" 94 "Reserved" 95 "Reserved" 96 "Reserved" 97 "Reserved" 98 "Reserved" 99 "Reserved" 100 "Reserved" 0 "Engine" 1 "Auxiliary Power Unit (APU)" 2 "Electric Propulsion Control" 3 "Transmission" 4 "Battery Pack Monitor" 5 "Shift Control/Console" 6 "Power TakeOff - (Main or Rear)" 7 "Axle - Steering" 8 "Axle - Drive" 9 "Brakes - System Controller" 10 "Brakes - Steer Axle" 11 "Brakes - Drive Axle" 12 "Retarder - Engine" 13 "Retarder - Driveline" 14 "Cruise Control" 15 "Fuel System" 16 "Steering Controller" 17 "Suspension - Steer Axle" 18 "Suspension - Drive Axle" 19 "Instrument Cluster" 20 "Trip Recorder" 21 "Cab Climate Control" 22 "Aerodynamic Control" 23 "Vehicle Navigation" 24 "Vehicle Security" 25 "Network Interconnect ECU" 26 "Body Controller" 27 "Power TakeOff (Secondary or Front)" 28 "Off Vehicle Gateway" 29 "Virtual Terminal (in cab)" 30 "Management Computer" 31 "Propulsion Battery Charger" 32 "Headway Controller" 33 "System Monitor" 34 "Hydraulic Pump Controller" 35 "Suspension - System Controller" 36 "Pneumatic - System Controller" 37 "Cab Controller" 38 "Tire Pressure Control" 39 "Ignition Control Module" 40 "Seat Control" 41 "Lighting - Operator Controls" 42 "Water Pump Control" 101 "Reserved" 102 "Reserved" 103 "Reserved" 104 "Reserved" 105 "Reserved" 106 "Reserved" 107 "Reserved" 108 "Reserved" 109 "Reserved" 110 "Reserved" 111 "Reserved" 112 "Reserved" 113 "Reserved" 114 "Reserved" 115 "Reserved" 116 "Reserved" 117 "Reserved" 118 "Reserved" 119 "Reserved" 120 "Reserved" 121 "Reserved" 122 "Reserved" 123 "Reserved" 124 "Reserved" 125 "Reserved" 126 "Reserved" 127 "Reserved" ;
VAL_ 2565340673 OperatingState1 0 "LearnModeInactive" 1 "LearnModeActive" ;
VAL_ 2565340673 Status_2 0 "Hidden" 1 "Shown" ;
VAL_ 2565340673 ManufacturerCode 234 "Mondial electronic GmbH" 235 "SailorMade Marine Telemetry - Tetra Technology Ltd." 236 "Norac Systems International Inc" 237 "Agtron Enterprises Inc" 238 "ZF Friedrichshafen AG" 239 "May & Scofield Ltd" 240 "Vanair Mfg" 241 "Schneider Automation SAS " 242 "Kokusandenki Co. Ltd" 243 "eRide, Inc." 244 "Techno-Matic" 245 "Capstan Ag Systems, Inc." 246 "Class 1, Inc" 247 "ePULSE" 248 "Cooper Standard Automotive Active Systems Group" 264 "Autolync" 265 "MTS Sensor Technologie GmbH" 266 "International Thermal Research Ltd" 267 "Red Lion Controls, Inc" 268 "Accurate Technologies" 269 "Saft America Inc.,  Space & Defense Division" 270 "Tennant" 271 "Cole Hersee" 312 "Lectronix, Inc." 313 "Ilmor Engineering, Inc" 314 "CSM GmbH" 315 "Icom Incorporated" 316 "ITT Flow Control" 317 "Navtronics Bvba" 318 "SAT Plan" 319 "Cadec Global" 320 "Miedema Landbouwwerktuigenfabriek B.V." 321 "Ultra Electronics, Electrics" 322 "MICHENKA s.r.o." 323 "Mobileye Vision Technologies Ltd." 324 "Snap-on Diagnostics" 325 "ASM Automation Sensorik Messtechnik GmbH" 326 "Akron Brass Company" 327 "Sonceboz SA" 272 "Gross Mechanical Laboratories, Inc" 273 "Active Research Limited" 274 "LTW Technology Co., LTD" 275 "Navico Egersund AS" 276 "Aqua-Hot Heating Systems" 277 "LHP Telematics" 278 "Takata Electronics" 279 "Geometris LP" 280 "Leica Geosystems Pty Ltd" 299 "Rauch Landmaschinen GmbH" 300 "Systron Donner Automotive" 301 "Parker Hannifin (UK) Ltd FDE group" 302 "Nissin Kogyo Co., LTD" 303 "CTS Corporation" 304 "EmpirBus AB" 305 "NovAtel Inc" 306 "Sleipner Motor AB" 307 "MBW Technologies" 308 "Cyntrx" 309 "Krauss-Maffei Wegmann GmbH & Co. KG" 310 "TECNORD srl" 311 "Patrick Power Products" 281 "Precision Governors LLC" 282 "Medallion Instrumentation Systems" 283 "CWF Hamilton & Co Ltd" 284 "Mobile Tech Chile" 285 "Sea Recovery Corp" 286 "Coelmo srl" 287 "NTech Industries, Inc" 288 "Mitsubishi FUSO Truck & Bus Corp." 289 "Watlow" 290 "Kuebler GmbH" 291 "Groeneveld Transport Efficiency BV" 292 "IKUSI - Angel Iglesias S.A." 293 "Spyder Controls Corp." 294 "Grayhill Inc." 295 "BEP Marine" 296 "micro dynamics GmbH" 297 "Zonar Systems Inc" 298 "Holley Performance" 253 "Mobile Control Systems" 254 "GE Sensing" 255 "MEAS France" 256 "Tyco Electronics AMP" 257 "Honda Motor Co., Ltd" 258 "ARAG" 259 "Jetter AG" 260 "Reichhardt GmbH" 261 "Red Dot Corporation" 262 "HydraForce, Inc" 263 "IMMI" 223 "Vaueo Retarder Co., Ltd." 224 "EMMI Network, S.L." 225 "SKF" 226 "Monaco Coach Corporation" 227 "Lykketronic A/S" 228 "ZF Marine Electronics" 229 "Garmin International Inc." 230 "Saucon Technologies" 231 "Topcon Positioning Systems, Inc." 0 "Reserved" 1 "Allied Signal Inc." 2 "Allison Transmission, GMC" 3 "Ametek, US Gauge Division" 4 "Ametek-Dixson" 5 "AMP Inc." 6 "Berifors Electronics AB" 7 "Case Corp." 8 "Caterpillar Inc." 9 "Chrysler Corp." 10 "Cummins Engine Co." 11 "Dearborn Group Inc." 12 "Deere & Company, Precision Farming" 13 "Delco Electronics" 14 "Detroit Diesel Corporation" 15 "Dickey-John Corp." 16 "Eaton Corp." 17 "Eaton Corp. Res & Dev" 18 "Eaton Corp, Transmission Division" 19 "Eaton Corp. Trucking Info Services" 20 "Eaton Ltd" 21 "Echilin Inc., Midland Brake Inc." 22 "Ford Motor Co., Electronic Concepts $ Systems" 23 "Ford Motor Co., Heavy Truck" 24 "Ford Motor Co., Vehicle Controls" 25 "Daimler Trucks North America LLC" 26 "General Motors Corp., Service Technology Group" 27 "GMC" 28 "Grote Ind. Inc." 29 "Hino Motors Ltd." 30 "Isuzu Motors Ltd." 31 "J Pollak Corp." 32 "Jacobs Vehicle Systems" 33 "John Deere" 34 "Kelsey Hayes Co." 35 "Kenworth Truck Co." 36 "Lucas Ltd." 37 "Mack Trucks Inc." 38 "Micro Processor Systems Inc." 39 "Microfirm Inc." 40 "Motorola AIEG Inc." 41 "Motorola Inc." 42 "International Truck and Engine Corp. Engine Electronics" 43 "International Truck and Engine Corp. Vehicle Electronics" 44 "Nippondenso Co. Ltd." 45 "PACCAR" 46 "Noregon Systems, Inc" 47 "Phillips Semiconductor" 48 "Pollak Alphabet" 49 "RE America Inc." 50 "Robert Bosch Corp" 51 "Robert Bosch GmbH" 52 "Meritor Automotive, Inc." 53 "Continental Automotive Systems US, Inc." 54 "Meritor Wabco" 55 "Ryder System Inc." 56 "SAIC" 57 "Sauer-Danfoss Co." 58 "SPX Corporation, OTC Division" 59 "VES Inc." 60 "Volvo Trucks North America Inc." 61 "Volvo Truck Corp." 62 "Wabco" 63 "ZF Industries Inc." 64 "unused" 65 "MAN Nutzfahrzeuge AG" 66 "John Deere Construction Equipment Division" 67 "Funk Manufacturing Company" 68 "Scania" 69 "Trimble Navigation" 70 "Flex-Coil Limited" 71 "Vansco Electronics Ltd." 72 "Sisu Corporation" 73 "LeTourneau, Inc." 74 "Eaton Axle-Brake Division" 75 "Deere & Co. Agricultural Division" 76 "unused" 77 "Deere Power Systems Group" 78 "Frank W. Murphy Manufacturing, Inc." 79 "Daimler Benz AG - Engine Division (PBM)" 80 "Twin Disc, Inc." 81 "Fire Research Corp" 82 "Bobcat/Ingersoll-Rand" 83 "Bendix VORAD Technologies" 84 "New Holland UK Limited" 85 "Kohler Co." 86 "C.E. Niehoff & Company" 87 "J.C. Bamford Excavators Ltd (JCB)" 88 "Satloc Precision GPS" 89 "Kverneland Group, Electronics Division" 90 "Knorr-Bremse SfN GmbH" 91 "BSG Bodensee Steuergeraete GmbH" 92 "Ag-Chem Equipment Co., Inc." 93 "Perkins Engines Company Ltd." 94 "CNH Global N.V." 95 "Pacific Insight Electronics Corp." 96 "Mech@tronic IT GmbH" 97 "Ag Leader Technology, Inc." 98 "Mueller-Elektronik GmbH & Co." 99 "International Transmissions Ltd (ITL)" 100 "VDO Technik AG" 101 "Sensoria" 102 "AGCO GmbH & Co." 103 "CLAAS Agrosystems GmbH & Co. KG" 104 "Claas Selbstfahrende Erntemaschinen GmbH" 105 "Kiepe Elektrik GmbH & Co. KG" 106 "BAE Systems Controls, Inc." 107 "Grimme Landmaschinen GmbH & Co. KG" 108 "WTK-Elecktronik GmbH" 109 "TeeJet Technologies Denmark" 110 "EPIQ Sensor-Nite" 111 "Maschinenfabrik Bernard Krone GmbH" 112 "MECALAC" 113 "Stress-Tek, Inc." 114 "EControls, Inc." 115 "NACCO Materials Handling Group, Inc." 116 "BEELINE Technologies" 117 "HUSCO International" 118 "Intron GmbH" 119 "IntegriNautics" 120 "RDS Technology Ltd." 121 "HED (Hydro Electronic Devices, Inc.)" 122 "FG Wilson (Engineering) Limited" 123 "Basler Electric" 124 "Hydac Electronic" 125 "Nevada Automotive Test Center" 126 "Driver Tech" 127 "Holland USA" 128 "Gerhard Duecker GmbH & Co. KG" 129 "OMNEX Control Systems, Inc." 130 "Nido - Universal Machines B.V." 131 "ITT Industries" 132 "Mulag-Fahrzeugwerk" 133 "Bucher Schoerling GmbH" 134 "Iris Technology Ltd." 135 "Airmar Technology Corporation" 136 "Komatsu Ltd." 137 "Maretron" 138 "Georg Fritzmeier GmbH & Co. KG" 139 "Caterpillar Trimble Control Technologies (CTCT), LLC" 140 "Lowrance Electronics, Inc." 141 "Thales Navigation Ltd." 142 "TRW Automotive (Commercial Steering Systems)" 143 "W. Gmeiner GmbH & Co." 144 "Mercury Marine" 145 "MurCal Controls" 146 "Maxima Technologies" 147 "Nautibus Electronic GmbH" 148 "Blue Water Data, Inc." 149 "Holset" 150 "Fleetguard" 151 "Raven Industries Inc. - Flow Controls Division" 152 "elobau GmbH & Co. KG" 153 "Woodward, Industrial Controls Division" 154 "Westerbeke Corporation" 155 "Vetronix Corporation" 156 "ITT Industries - Cannon" 157 "ISSPRO Inc." 158 "Firestone Industrial Products Company" 159 "NTech Industries Inc." 160 "Nido" 161 "Offshore Systems (UK) Limited" 162 "Axiomatic Technologies" 163 "BRP Inc." 164 "DaimlerChrysler Off-Highway" 165 "CPAC Systems AB" 166 "Phoenix International" 167 "JLG Industries Inc." 168 "Xantrex" 169 "Marlin Technologies Inc." 170 "Computronics Corporation Ltd." 171 "Wachendorff Elektronik GmbH & Co. KG" 172 "Yanmar Marine USA" 173 "Ryeso, Inc." 174 "AB Volvo Penta" 175 "Veris Technologies, Inc." 176 "Moritz Aerospace" 177 "Diagnostic System Associates" 178 "Siemens VDO Automotive AG" 179 "TeeJet Technologies Denmark" 180 "Smart Power Systems" 181 "Coretronics, Inc." 182 "Vehicle Systems Engineering B.V." 183 "KDS Controls, Inc." 184 "EIA Electronics" 185 "Beede Electrical Instrument Company" 186 "Altronic, Inc." 187 "Air-Weigh" 188 "EMP Corp." 189 "QUALCOMM" 190 "Hella KGaA Hueck & Co." 191 "XRS Corporation" 192 "Floscan" 193 "Nobletec" 194 "TriMark Corporation" 195 "General Engine Products" 196 "LEMKEN GmbH & Co. KG" 197 "Mechron Power Systems" 198 "Mystic Valley Communications" 199 "Actia Corp." 200 "MGM Brakes" 201 "Disenos y Tecnologia S.A." 202 "Curtis Instruments, Inc." 203 "MILtronik GmbH" 204 "The Morey Corporation" 205 "SmarTire Systems Inc" 206 "port GmbH" 207 "Otto Engineering" 208 "Drew Technologies, Inc." 209 "Bell Equip. Co. SA (PTY) LTD" 210 "Iteris, Inc." 211 "DNA Group" 212 "Sure Power Industries, Inc." 213 "CNH Belgium N.V." 214 "MC elettronica Srl" 215 "Aetna Engineering/Fireboy-Xintex" 216 "Paneltronics Inc." 217 "RM Michaelides Software & Elektronik GmbH" 218 "Gits Manufacturing Company" 219 "Cat OEM Solutions" 220 "Beede Electrical Instrument Company, Inc." 221 "SiE" 222 "Generac Power Systems, Inc." 1850 "Teleflex" 1851 "Raymarine" 1852 "Navionics" 1853 "Japan Radio Co." 1854 "Northstar Technologies" 1855 "Furuno USA" 1856 "Trimble" 1857 "Simrad" 1858 "Litton" 1859 "Kvasar AB" 1860 "MMP" 1861 "Vector North America" 1862 "Sanshin" 1863 "Thomas G. Faria Co." 232 "TSD Integrated Controls" 233 "Yacht Monitoring Solutions Inc." 249 "Schaltbau GmbH" 250 "Kuhn Group" 251 "German Agricultural Society" 252 "Sensor-Technik Wiedemann GmbH" 328 "Qwerty Electronik AB" 329 "Deif A/S" 330 "Kidde Aerospace and Defense" 331 "Horton, Inc." 332 "HWH Corporation" 333 "Hadley Products Corporation" 334 "Takata-Petri AG" 335 "Evo Electric Ltd" 336 "APE s.r.o." 337 "Carraro S.p.A." 338 "GRAF-SYTECO" 339 "Competence Center ISOBUS e.V." 340 "Continental AG" 341 "Boning GmbH & Co" 342 "THOMAS MAGNETE GmbH" 343 "Baumer Group" 344 "Parvus Corporation" 345 "Korean Maritime University" 346 "Control Solutions" 347 "Honeywell" 348 "Amazonen Werke H. Dreyer" 349 "Suonentiet" 350 "Noris Marine Systems GmbH & Co KG" 351 "Thrane & Thrane" 352 "SAME DEUTZ-FAHR" 353 "Hegemon Electronics, Inc." 354 "Junkkari OY" 355 "Mastervolt International B.V." 356 "Fischer Panda Generators, Inc" 357 "Hardi International A/S" 358 "Victron Energy BV" 359 "Ludwig Bergmann GmbH" 360 "HJS Emission Technology GmbH & Co KG" 361 "InMach" 362 "Alois Poettinger Maschinenfabrik GmbH" 363 "BEI Duncan" 364 "OEM Controls Inc." 365 "Digi-Star, LLC" 366 "Viewnyx Corp." 367 "Fliegl Agrartechnik" 368 "HANSENHOF_electronic" 369 "Power Torque Engineering Ltd" 370 "Rolls-Royce Marine AS" 371 "Heinzmann GmbH & Co. KG" 373 "Electronic Design Inc." 374 "Northern Lights, Inc." 381 "B&G" 372 "Delphi" 375 "Williams Controls Inc." 376 "Quake Global" 377 "ifm electronic gmbh" 378 "Glendinning Marine Products" 379 "Yamabiko Corporation" 380 "Suntech International Ltd." 382 "National Agricultural and Food Research Organization" 383 "MCL Industries" 384 "Camano Light" 385 "Johnson Outdoor Marine Electronics" 386 "JLG Automation BVBA" 387 "Orscheln Products, LLC" 388 "Innomatix, LLC" 389 "Benchmark Electronics, Minnesota Division" 390 "Partech Inc." 391 "Electronic Design for Industry, Inc" 392 "Tianyuan Technology Co Ltd." 393 "Harvest Tec, Inc" 394 "Capi 2 Nederland BV" 395 "GENTEC S.R.L." 396 "Beyond Measure" 397 "Sanyo-kiki Co Ltd." 398 "Hilite International" 399 "ISEKI & Co., Ltd." 400 "Livorsi Marine" 401 "Torqeedo GmbH" 402 "Simma Software, Inc." 403 "Trackwell ADS, Inc." 404 "Com Nav Marine Ltd" 405 "Wema System AS" 406 "Vecima Networks Inc." 407 "Comtech Mobile Datacom" 408 "Corvus Energy Ltd." 409 "Transfluid S.r.L." 410 "COBO S.p.A. Divisione 3B6" 411 "Hy-Drive Technologies Ltd." 412 "WebTech Wireless Inc." 413 "Datapross Nijbroek bv" 414 "Cattron Group International" 415 "Valid Manufacturing Ltd." 416 "Kubota Corporation" 417 "KZValve" 418 "Intellistick Inc" 419 "Fusion Electronics Ltd" 420 "Vermeer Corporation, ACS Group" 421 "Vertex Standard Co., Ltd" 422 "True Heading AB" 423 "BSM Wireless, Inc." 424 "Odyne LLC" 425 "Methode Electronics Inc, MDI" 426 "Egersund Marine Electronics AS" 427 "em-trak Marine Electronics Ltd" 428 "Mfg_428" 429 "Rota Engineering Ltd." 455 "ADZ NAGANO GmbH" 456 "General Kinetics" 457 "RUSELPROM-ElectricDrive Ltd" 458 "Control Solutions, Inc." 459 "Alltek Marine Electronics Corp" 460 "San Giorgio S.E.I.N." 461 "HAWE Hydraulik SE" 462 "IHI Shibaura Machinery Corporation" 463 "PROBOTIQ" 464 "Leach International Corporation" 465 "Ashcroft Inc" 466 "Veethree Electronics and Marine LLC" 467 "Lely Industries N.V." 468 "Tyco Fire Protection Products" 469 "RA Consulting GmbH" 470 "SI-TEX Marine Electronics" 471 "Sea Cross Marine AB" 472 "Tenneco Inc." 473 "Boss Industries, Inc." 474 "Persen Technologies Inc." 475 "GME" 476 "Hummingbird Marine Electronics" 477 "OilQuick AB" 478 "OceanSat BV" 479 "Vapor Bus International" 430 "Auteq Telematica S.A." 431 "Tohatsu Corporation" 432 "S&A Systems, Inc." 433 "Rowe Electronics" 434 "Stored Energy Systems" 435 "Zunhammer GmbH" 436 "Kinze Manufacturing" 437 "Digital Yacht Limited" 438 "Comar Systems Ltd" 439 "Hyundai Heavy Industries" 440 "Cummins Power Generation" 441 "PTG Reifendruckregelsysteme GmbH" 442 "Horsch Maschinen GmbH" 443 "SignalQuest, Inc." 444 "ITT Power Solutions" 445 "KAT MECHATRONIC, Electronic Product Division" 446 "CertTech, L.L.C." 447 "Great Plains Mfg." 448 "Stanadyne Corporation, Electronics Systems" 449 "Polaris Industries Inc" 450 "Dycor Technologies Ltd." 451 "Parker Hannifin Corp" 452 "WIKA Alexander Wiegand SE & Co. KG" 453 "Cooper Bussmann" 454 "NGK Spark Plug Co. Ltd" 480 "EnerDel, Inc." 481 "Chetco Digital Instruments" 482 "Tricon Electronics" 483 "Valeo" 484 "Headsight Inc." 485 "MATT automotive" 486 "Westport Innovations Inc." 487 "DSE Test Solutions A/S" 488 "The Charles Machine Works, Inc." 489 "Appareo Systems" 490 "QuikQ" 491 "Penny and Giles Ltd" 492 "Inergy Automotive Systems" 493 "Watcheye" 494 "Synerject" 495 "HOLMER Maschinenbau GmbH" 496 "W. Gessmann GmbH" 497 "SENTRON Sistemas Embarcados" 498 "Innovative Design Solutions, Inc." 499 "LCJ Capteurs" 500 "Oxbo International Corporation" 501 "Agrotronix S.A." 502 "Attwood Corporation" 503 "Naviop S.R.L." 504 "Vesper Marine" 505 "Yetter Farm Equipment" 506 "IHI STAR Machinery Corporation" 507 "Test Center ISOBUS" 508 "Transtech Innovations" 509 "MOTORTECH GmbH" 510 "Marinesoft Co. Ltd" 511 "Sulky" 512 "Inpower LLC" 513 "FarmscanAg" 514 "DISTek Integration, Inc." 515 "GINAF Trucks Nederland B.V." 516 "AVAT Automation GmbH" 517 "Noland Engineering" 518 "Transas USA Inc." 519 "Peeters Landbouwmachines b.v." 520 "Trapeze" ;
VAL_ 2565340673 TextOption 0 "Opaque" 1 "Transparent" ;
VAL_ 2565340673 ButtonObjectParentID 2 "ButtonsStillHeld" 1 "ButtonHasBeenLatched" 0 "ButtonHasBeenUnlatched" ;
VAL_ 2565340673 KeyObjectParentID 2 "KeyIsStillHeld" 1 "KeyHasBeenPressed" 0 "KeyHasBeenReleased" ;
VAL_ 2565340673 SubCommandID 0 "SetGraphicsCursor" 1 "MoveGraphicsCursor" 2 "SetForegroundColour" 3 "SetBackgroundColour" 4 "SetLineAttributesObjectID" 5 "SetFillAttributesObjectID" 6 "SetFontAttributesID" 7 "EraseRectangle" 8 "DrawPoint" 9 "DrawLine" 10 "DrawRectangle" 11 "DrawClosedEllipse" 12 "DrawPolygon" 13 "DrawText" 14 "PanViewport" 15 "ZoomViewport" 16 "PanAndZoomViewport" 17 "ChangeViewportSize" 18 "DrawVTObject" 19 "CopyCanvasToPictureGraphic" 20 "CopyViewportToPictureGraphic" ;
VAL_ 2565340673 EnableOrDisable 1 "Enable" 0 "Disable" ;
VAL_ 2565340673 ShowOrHide 1 "Show" 0 "Hide" ;
VAL_ 2565340673 AssignmentErrorNotAccepted 1 "AssignmentNotAccepted" 0 "AssignmentAccepted" ;
VAL_ 2565340673 Status_1 0 "Hidden" 1 "Shown" ;
VAL_ 2565340673 ButtonObjectID 2 "ButtonsStillHeld" 1 "ButtonHasBeenLatched" 0 "ButtonHasBeenUnlatched" ;
VAL_ 2565340673 KeyObjectID 2 "KeyIsStillHeld" 1 "KeyHasBeenPressed" 0 "KeyHasBeenReleased" ;
VAL_ 2565340673 WSMaintenanceVersion 3 "CompliantWithVTVersion3" 4 "CompliantWithVTVersion4" 255 "CompliantWithVTVersion2AndPrior" ;
VAL_ 2565340673 AuxCapabilitiesRequestType 0 "RequestCapabilitiesOfAuxiliaryInputs" 1 "RequestCapabilitiesOfAuxFunctions" ;
VAL_ 2565340673 LockUnlockCommand 0 "UnlockMask" 1 "LockMask" ;
VAL_ 2565340673 MaskType 2 "Alarm" 1 "Data" ;
VAL_ 2565340673 ButtonActivationCode 2 "ButtonsStillHeld" 1 "ButtonHasBeenLatched" 0 "ButtonHasBeenUnlatched" 3 "ButtonPressAborted" ;
VAL_ 2565340673 KeyActivationCode 2 "KeyIsStillHeld" 1 "KeyHasBeenPressed" 0 "KeyHasBeenReleased" 3 "KeyPressAborted" ;
VAL_ 2565340673 VTFunctionECUtoVT 253 "UnsupportedVTFunction" 8 "VTChangeStringValueResponse" 180 "ChangeChildPosition" 17 "ObjectPoolTransfer" 196 "GetWindowMaskData" 7 "VTChangeSoftKeyMaskResponse" 6 "VTChangeActiveMaskResponse" 5 "VTChangeNumericValueResponse" 4 "VTESCResponse" 3 "VTSelectInputObjectResponse" 179 "ChangeStringValue" 255 "WorkingSetMaintenance" 223 "GetVersions" 210 "DeleteVersion" 209 "LoadVersion" 208 "StoreVersion" 199 "GetHardware" 195 "GetTextFontData" 194 "GetNumberOfSoftKeys" 192 "GetMemory" 178 "DeleteObjectPool" 177 "ChangeListItem" 176 "ChangePriority" 175 "ChangeAttribute" 174 "ChangeSoftKeyMask" 173 "ChangeActiveMask" 172 "ChangeFillAttributes" 171 "ChangeLineAttributes" 170 "ChangeFontAttributes" 169 "ChangeEndPoint" 168 "ChangeNumericValue" 167 "ChangeBackgroundColour" 166 "ChangeSize" 165 "ChangeChildLocation" 164 "SetAudioVolume" 163 "ControlAudioDevice" 162 "SelectInputObject" 161 "EnableDisableObject" 160 "ShowHideObject" 146 "ESC" 32 "AuxiliaryAssignmentResponse" 18 "EndOfObjectPool" 2 "PointingEventResponse" 1 "ButtonActivationResponse" 0 "SoftKeyActivationResponse" 181 "SetObjectLabel" 182 "ChangePolygonPoint" 183 "ChangePolygonScale" 184 "GraphicsContextCommand" 185 "GetAttribute" 186 "SelectColourMap" 9 "VTOnUserLayoutHideShowResponse" 34 "AuxiliaryPreferredAssignment" 189 "LockUnlockMask" 190 "ExecuteMacro" 35 "AuxiliaryInputMaintenance" 37 "AuxiliaryInputStatusEnableCommandResponse" 193 "GetSupported WideChars" 33 "Auxiliary Input Status" 36 "AuxiliaryAssignmentResponseType2" 187 "Identify VT" 197 "GetSupportedObjects" 188 "ExecuteExtendedMacro" 211 "ExtendedGetVersions" 212 "ExtendedStoreVersion" 213 "ExtendedLoadVersion" 214 "ExtendedDeleteVersion" 39 "AuxiliaryCapabilitiesRequest" ;
VAL_ 2565799425 IndustryGroup 7 "Reserved for SAE" 5 "IndustrialProcessCtrlStationary" 4 "Marine" 3 "Construction" 2 "Agricultural and Forestry" 1 "On-Highway" 0 "Global" ;
VAL_ 2565799425 VehicleSystem 127 "Not Available" 0 "Non-specific System" ;
VAL_ 2565799425 VehicleSystem5 0 "Ind. Process Control Stationary" 127 "Not Available" ;
VAL_ 2565799425 VehicleSystem4 0 "Non-specific System" 127 "Not Available" 10 "System Tools" 20 "Safety Systems" 25 "Inter/Intranetwork Device" 30 "Electrical Distribution" 40 "Steering and Control Surfaces" 50 "Propulsion" 60 "Navigation" 70 "Communications" 80 "Instrumentation/General Systems (deprecate)" 90 "Internal Environment" 100 "Deck, Cargo and Fishing Equipment" 35 "Electrical Generation" 75 "Sensor Communication Interface" 85 "External Environment" 120 "Display" 125 "Entertainment" ;
VAL_ 2565799425 VehicleSystem3 0 "Non-specific System" 127 "Not Available" 1 "Skid Steer Loader" 2 "Articulated Dump Truck" 3 "Backhoe" 4 "Crawler" 5 "Excavator" 6 "Forklift" 7 "Four Wheel Drive Loader" 8 "Grader" ;
VAL_ 2565799425 VehicleSystem2 0 "Non-specific System" 127 "Not Available" 1 "Tractor" 2 "Tillage" 3 "Secondary Tillage" 4 "Planters/Seeders" 5 "Fertilizers" 6 "Sprayers" 7 "Harvesters" 8 "Root Harvesters" 9 "Forage" 10 "Irrigation" 11 "Transport/Trailer" 12 "Farm Yard Operations" 13 "Powered Auxiliary Device" 14 "Special Crops" 15 "Earth Work" 16 "Skidder" 17 "Sensor Systems" 19 "Timber Harvesters" 20 "Forwarders" 21 "Timber loaders" 22 "Timber Processing Machines" 23 "Mulchers" 24 "Utility Vehicles" 25 "Slurry Applicators" ;
VAL_ 2565799425 VehicleSystem1 0 "Non-specific System" 127 "Not Available" 1 "Tractor" 2 "Trailer" ;
VAL_ 2565799425 Function 43 "Transmission Display" 44 "Exhaust Emission Control" 45 "Vehicle Dynamic Stability Control" 46 "Oil Sensor Unit" 47 "Information System Controller" 48 "Ramp Control" 49 "Clutch/Converter Control" 50 "Auxiliary Heater" 51 "Forward-Looking Collision Warning System" 52 "Chassis Controller" 53 "Alternator/Charging System" 54 "Communications Unit, Cellular" 55 "Communications Unit, Satellite" 56 "Communications Unit, Radio" 57 "Steering Column Unit" 58 "Fan Drive Control" 59 "Starter" 60 "Cab Display" 61 "File Server/Printer" 62 "On-Board Diagnostic Unit" 63 "Engine Valve Controller" 64 "Endurance Braking" 65 "Gas Flow Measurement" 66 "I/O Controller" 67 "Electrical System Controller" 68 "Aftertreatment system gas measurement" 69 "Engine Emission Aftertreatement System" 70 "Auxiliary Regeneration Device" 71 "Transfer Case Control" 72 "Coolant Valve Controller" 73 "Rollover Detection Control" 74 "Lubrication System" 75 "Supplemental Fan" 76 "Temperature Sensor" 77 "Fuel Properties Sensor" 78 "Fire Suppression System" 79 "Reserved" 80 "Reserved" 81 "Reserved" 82 "Reserved" 83 "Reserved" 84 "Reserved" 85 "Reserved" 86 "Reserved" 87 "Reserved" 88 "Reserved" 89 "Reserved" 90 "Reserved" 91 "Reserved" 92 "Reserved" 93 "Reserved" 94 "Reserved" 95 "Reserved" 96 "Reserved" 97 "Reserved" 98 "Reserved" 99 "Reserved" 100 "Reserved" 0 "Engine" 1 "Auxiliary Power Unit (APU)" 2 "Electric Propulsion Control" 3 "Transmission" 4 "Battery Pack Monitor" 5 "Shift Control/Console" 6 "Power TakeOff - (Main or Rear)" 7 "Axle - Steering" 8 "Axle - Drive" 9 "Brakes - System Controller" 10 "Brakes - Steer Axle" 11 "Brakes - Drive Axle" 12 "Retarder - Engine" 13 "Retarder - Driveline" 14 "Cruise Control" 15 "Fuel System" 16 "Steering Controller" 17 "Suspension - Steer Axle" 18 "Suspension - Drive Axle" 19 "Instrument Cluster" 20 "Trip Recorder" 21 "Cab Climate Control" 22 "Aerodynamic Control" 23 "Vehicle Navigation" 24 "Vehicle Security" 25 "Network Interconnect ECU" 26 "Body Controller" 27 "Power TakeOff (Secondary or Front)" 28 "Off Vehicle Gateway" 29 "Virtual Terminal (in cab)" 30 "Management Computer" 31 "Propulsion Battery Charger" 32 "Headway Controller" 33 "System Monitor" 34 "Hydraulic Pump Controller" 35 "Suspension - System Controller" 36 "Pneumatic - System Controller" 37 "Cab Controller" 38 "Tire Pressure Control" 39 "Ignition Control Module" 40 "Seat Control" 41 "Lighting - Operator Controls" 42 "Water Pump Control" 101 "Reserved" 102 "Reserved" 103 "Reserved" 104 "Reserved" 105 "Reserved" 106 "Reserved" 107 "Reserved" 108 "Reserved" 109 "Reserved" 110 "Reserved" 111 "Reserved" 112 "Reserved" 113 "Reserved" 114 "Reserved" 115 "Reserved" 116 "Reserved" 117 "Reserved" 118 "Reserved" 119 "Reserved" 120 "Reserved" 121 "Reserved" 122 "Reserved" 123 "Reserved" 124 "Reserved" 125 "Reserved" 126 "Reserved" 127 "Reserved" ;
VAL_ 2565799425 ManufacturerCode 234 "Mondial electronic GmbH" 235 "SailorMade Marine Telemetry - Tetra Technology Ltd." 236 "Norac Systems International Inc" 237 "Agtron Enterprises Inc" 238 "ZF Friedrichshafen AG" 239 "May & Scofield Ltd" 240 "Vanair Mfg" 241 "Schneider Automation SAS " 242 "Kokusandenki Co. Ltd" 243 "eRide, Inc." 244 "Techno-Matic" 245 "Capstan Ag Systems, Inc." 246 "Class 1, Inc" 247 "ePULSE" 248 "Cooper Standard Automotive Active Systems Group" 264 "Autolync" 265 "MTS Sensor Technologie GmbH" 266 "International Thermal Research Ltd" 267 "Red Lion Controls, Inc" 268 "Accurate Technologies" 269 "Saft America Inc.,  Space & Defense Division" 270 "Tennant" 271 "Cole Hersee" 312 "Lectronix, Inc." 313 "Ilmor Engineering, Inc" 314 "CSM GmbH" 315 "Icom Incorporated" 316 "ITT Flow Control" 317 "Navtronics Bvba" 318 "SAT Plan" 319 "Cadec Global" 320 "Miedema Landbouwwerktuigenfabriek B.V." 321 "Ultra Electronics, Electrics" 322 "MICHENKA s.r.o." 323 "Mobileye Vision Technologies Ltd." 324 "Snap-on Diagnostics" 325 "ASM Automation Sensorik Messtechnik GmbH" 326 "Akron Brass Company" 327 "Sonceboz SA" 272 "Gross Mechanical Laboratories, Inc" 273 "Active Research Limited" 274 "LTW Technology Co., LTD" 275 "Navico Egersund AS" 276 "Aqua-Hot Heating Systems" 277 "LHP Telematics" 278 "Takata Electronics" 279 "Geometris LP" 280 "Leica Geosystems Pty Ltd" 299 "Rauch Landmaschinen GmbH" 300 "Systron Donner Automotive" 301 "Parker Hannifin (UK) Ltd FDE group" 302 "Nissin Kogyo Co., LTD" 303 "CTS Corporation" 304 "EmpirBus AB" 305 "NovAtel Inc" 306 "Sleipner Motor AB" 307 "MBW Technologies" 308 "Cyntrx" 309 "Krauss-Maffei Wegmann GmbH & Co. KG" 310 "TECNORD srl" 311 "Patrick Power Products" 281 "Precision Governors LLC" 282 "Medallion Instrumentation Systems" 283 "CWF Hamilton & Co Ltd" 284 "Mobile Tech Chile" 285 "Sea Recovery Corp" 286 "Coelmo srl" 287 "NTech Industries, Inc" 288 "Mitsubishi FUSO Truck & Bus Corp." 289 "Watlow" 290 "Kuebler GmbH" 291 "Groeneveld Transport Efficiency BV" 292 "IKUSI - Angel Iglesias S.A." 293 "Spyder Controls Corp." 294 "Grayhill Inc." 295 "BEP Marine" 296 "micro dynamics GmbH" 297 "Zonar Systems Inc" 298 "Holley Performance" 253 "Mobile Control Systems" 254 "GE Sensing" 255 "MEAS France" 256 "Tyco Electronics AMP" 257 "Honda Motor Co., Ltd" 258 "ARAG" 259 "Jetter AG" 260 "Reichhardt GmbH" 261 "Red Dot Corporation" 262 "HydraForce, Inc" 263 "IMMI" 223 "Vaueo Retarder Co., Ltd." 224 "EMMI Network, S.L." 225 "SKF" 226 "Monaco Coach Corporation" 227 "Lykketronic A/S" 228 "ZF Marine Electronics" 229 "Garmin International Inc." 230 "Saucon Technologies" 231 "Topcon Positioning Systems, Inc." 0 "Reserved" 1 "Allied Signal Inc." 2 "Allison Transmission, GMC" 3 "Ametek, US Gauge Division" 4 "Ametek-Dixson" 5 "AMP Inc." 6 "Berifors Electronics AB" 7 "Case Corp." 8 "Caterpillar Inc." 9 "Chrysler Corp." 10 "Cummins Engine Co." 11 "Dearborn Group Inc." 12 "Deere & Company, Precision Farming" 13 "Delco Electronics" 14 "Detroit Diesel Corporation" 15 "Dickey-John Corp." 16 "Eaton Corp." 17 "Eaton Corp. Res & Dev" 18 "Eaton Corp, Transmission Division" 19 "Eaton Corp. Trucking Info Services" 20 "Eaton Ltd" 21 "Echilin Inc., Midland Brake Inc." 22 "Ford Motor Co., Electronic Concepts $ Systems" 23 "Ford Motor Co., Heavy Truck" 24 "Ford Motor Co., Vehicle Controls" 25 "Daimler Trucks North America LLC" 26 "General Motors Corp., Service Technology Group" 27 "GMC" 28 "Grote Ind. Inc." 29 "Hino Motors Ltd." 30 "Isuzu Motors Ltd." 31 "J Pollak Corp." 32 "Jacobs Vehicle Systems" 33 "John Deere" 34 "Kelsey Hayes Co." 35 "Kenworth Truck Co." 36 "Lucas Ltd." 37 "Mack Trucks Inc." 38 "Micro Processor Systems Inc." 39 "Microfirm Inc." 40 "Motorola AIEG Inc." 41 "Motorola Inc." 42 "International Truck and Engine Corp. Engine Electronics" 43 "International Truck and Engine Corp. Vehicle Electronics" 44 "Nippondenso Co. Ltd." 45 "PACCAR" 46 "Noregon Systems, Inc" 47 "Phillips Semiconductor" 48 "Pollak Alphabet" 49 "RE America Inc." 50 "Robert Bosch Corp" 51 "Robert Bosch GmbH" 52 "Meritor Automotive, Inc." 53 "Continental Automotive Systems US, Inc." 54 "Meritor Wabco" 55 "Ryder System Inc." 56 "SAIC" 57 "Sauer-Danfoss Co." 58 "SPX Corporation, OTC Division" 59 "VES Inc." 60 "Volvo Trucks North America Inc." 61 "Volvo Truck Corp." 62 "Wabco" 63 "ZF Industries Inc." 64 "unused" 65 "MAN Nutzfahrzeuge AG" 66 "John Deere Construction Equipment Division" 67 "Funk Manufacturing Company" 68 "Scania" 69 "Trimble Navigation" 70 "Flex-Coil Limited" 71 "Vansco Electronics Ltd." 72 "Sisu Corporation" 73 "LeTourneau, Inc." 74 "Eaton Axle-Brake Division" 75 "Deere & Co. Agricultural Division" 76 "unused" 77 "Deere Power Systems Group" 78 "Frank W. Murphy Manufacturing, Inc." 79 "Daimler Benz AG - Engine Division (PBM)" 80 "Twin Disc, Inc." 81 "Fire Research Corp" 82 "Bobcat/Ingersoll-Rand" 83 "Bendix VORAD Technologies" 84 "New Holland UK Limited" 85 "Kohler Co." 86 "C.E. Niehoff & Company" 87 "J.C. Bamford Excavators Ltd (JCB)" 88 "Satloc Precision GPS" 89 "Kverneland Group, Electronics Division" 90 "Knorr-Bremse SfN GmbH" 91 "BSG Bodensee Steuergeraete GmbH" 92 "Ag-Chem Equipment Co., Inc." 93 "Perkins Engines Company Ltd." 94 "CNH Global N.V." 95 "Pacific Insight Electronics Corp." 96 "Mech@tronic IT GmbH" 97 "Ag Leader Technology, Inc." 98 "Mueller-Elektronik GmbH & Co." 99 "International Transmissions Ltd (ITL)" 100 "VDO Technik AG" 101 "Sensoria" 102 "AGCO GmbH & Co." 103 "CLAAS Agrosystems GmbH & Co. KG" 104 "Claas Selbstfahrende Erntemaschinen GmbH" 105 "Kiepe Elektrik GmbH & Co. KG" 106 "BAE Systems Controls, Inc." 107 "Grimme Landmaschinen GmbH & Co. KG" 108 "WTK-Elecktronik GmbH" 109 "TeeJet Technologies Denmark" 110 "EPIQ Sensor-Nite" 111 "Maschinenfabrik Bernard Krone GmbH" 112 "MECALAC" 113 "Stress-Tek, Inc." 114 "EControls, Inc." 115 "NACCO Materials Handling Group, Inc." 116 "BEELINE Technologies" 117 "HUSCO International" 118 "Intron GmbH" 119 "IntegriNautics" 120 "RDS Technology Ltd." 121 "HED (Hydro Electronic Devices, Inc.)" 122 "FG Wilson (Engineering) Limited" 123 "Basler Electric" 124 "Hydac Electronic" 125 "Nevada Automotive Test Center" 126 "Driver Tech" 127 "Holland USA" 128 "Gerhard Duecker GmbH & Co. KG" 129 "OMNEX Control Systems, Inc." 130 "Nido - Universal Machines B.V." 131 "ITT Industries" 132 "Mulag-Fahrzeugwerk" 133 "Bucher Schoerling GmbH" 134 "Iris Technology Ltd." 135 "Airmar Technology Corporation" 136 "Komatsu Ltd." 137 "Maretron" 138 "Georg Fritzmeier GmbH & Co. KG" 139 "Caterpillar Trimble Control Technologies (CTCT), LLC" 140 "Lowrance Electronics, Inc." 141 "Thales Navigation Ltd." 142 "TRW Automotive (Commercial Steering Systems)" 143 "W. Gmeiner GmbH & Co." 144 "Mercury Marine" 145 "MurCal Controls" 146 "Maxima Technologies" 147 "Nautibus Electronic GmbH" 148 "Blue Water Data, Inc." 149 "Holset" 150 "Fleetguard" 151 "Raven Industries Inc. - Flow Controls Division" 152 "elobau GmbH & Co. KG" 153 "Woodward, Industrial Controls Division" 154 "Westerbeke Corporation" 155 "Vetronix Corporation" 156 "ITT Industries - Cannon" 157 "ISSPRO Inc." 158 "Firestone Industrial Products Company" 159 "NTech Industries Inc." 160 "Nido" 161 "Offshore Systems (UK) Limited" 162 "Axiomatic Technologies" 163 "BRP Inc." 164 "DaimlerChrysler Off-Highway" 165 "CPAC Systems AB" 166 "Phoenix International" 167 "JLG Industries Inc." 168 "Xantrex" 169 "Marlin Technologies Inc." 170 "Computronics Corporation Ltd." 171 "Wachendorff Elektronik GmbH & Co. KG" 172 "Yanmar Marine USA" 173 "Ryeso, Inc." 174 "AB Volvo Penta" 175 "Veris Technologies, Inc." 176 "Moritz Aerospace" 177 "Diagnostic System Associates" 178 "Siemens VDO Automotive AG" 179 "TeeJet Technologies Denmark" 180 "Smart Power Systems" 181 "Coretronics, Inc." 182 "Vehicle Systems Engineering B.V." 183 "KDS Controls, Inc." 184 "EIA Electronics" 185 "Beede Electrical Instrument Company" 186 "Altronic, Inc." 187 "Air-Weigh" 188 "EMP Corp." 189 "QUALCOMM" 190 "Hella KGaA Hueck & Co." 191 "XRS Corporation" 192 "Floscan" 193 "Nobletec" 194 "TriMark Corporation" 195 "General Engine Products" 196 "LEMKEN GmbH & Co. KG" 197 "Mechron Power Systems" 198 "Mystic Valley Communications" 199 "Actia Corp." 200 "MGM Brakes" 201 "Disenos y Tecnologia S.A." 202 "Curtis Instruments, Inc." 203 "MILtronik GmbH" 204 "The Morey Corporation" 205 "SmarTire Systems Inc" 206 "port GmbH" 207 "Otto Engineering" 208 "Drew Technologies, Inc." 209 "Bell Equip. Co. SA (PTY) LTD" 210 "Iteris, Inc." 211 "DNA Group" 212 "Sure Power Industries, Inc." 213 "CNH Belgium N.V." 214 "MC elettronica Srl" 215 "Aetna Engineering/Fireboy-Xintex" 216 "Paneltronics Inc." 217 "RM Michaelides Software & Elektronik GmbH" 218 "Gits Manufacturing Company" 219 "Cat OEM Solutions" 220 "Beede Electrical Instrument Company, Inc." 221 "SiE" 222 "Generac Power Systems, Inc." 1850 "Teleflex" 1851 "Raymarine" 1852 "Navionics" 1853 "Japan Radio Co." 1854 "Northstar Technologies" 1855 "Furuno USA" 1856 "Trimble" 1857 "Simrad" 1858 "Litton" 1859 "Kvasar AB" 1860 "MMP" 1861 "Vector North America" 1862 "Sanshin" 1863 "Thomas G. Faria Co." 232 "TSD Integrated Controls" 233 "Yacht Monitoring Solutions Inc." 249 "Schaltbau GmbH" 250 "Kuhn Group" 251 "German Agricultural Society" 252 "Sensor-Technik Wiedemann GmbH" 328 "Qwerty Electronik AB" 329 "Deif A/S" 330 "Kidde Aerospace and Defense" 331 "Horton, Inc." 332 "HWH Corporation" 333 "Hadley Products Corporation" 334 "Takata-Petri AG" 335 "Evo Electric Ltd" 336 "APE s.r.o." 337 "Carraro S.p.A." 338 "GRAF-SYTECO" 339 "Competence Center ISOBUS e.V." 340 "Continental AG" 341 "Boning GmbH & Co" 342 "THOMAS MAGNETE GmbH" 343 "Baumer Group" 344 "Parvus Corporation" 345 "Korean Maritime University" 346 "Control Solutions" 347 "Honeywell" 348 "Amazonen Werke H. Dreyer" 349 "Suonentiet" 350 "Noris Marine Systems GmbH & Co KG" 351 "Thrane & Thrane" 352 "SAME DEUTZ-FAHR" 353 "Hegemon Electronics, Inc." 354 "Junkkari OY" 355 "Mastervolt International B.V." 356 "Fischer Panda Generators, Inc" 357 "Hardi International A/S" 358 "Victron Energy BV" 359 "Ludwig Bergmann GmbH" 360 "HJS Emission Technology GmbH & Co KG" 361 "InMach" 362 "Alois Poettinger Maschinenfabrik GmbH" 363 "BEI Duncan" 364 "OEM Controls Inc." 365 "Digi-Star, LLC" 366 "Viewnyx Corp." 367 "Fliegl Agrartechnik" 368 "HANSENHOF_electronic" 369 "Power Torque Engineering Ltd" 370 "Rolls-Royce Marine AS" 371 "Heinzmann GmbH & Co. KG" 373 "Electronic Design Inc." 374 "Northern Lights, Inc." 381 "B&G" 372 "Delphi" 375 "Williams Controls Inc." 376 "Quake Global" 377 "ifm electronic gmbh" 378 "Glendinning Marine Products" 379 "Yamabiko Corporation" 380 "Suntech International Ltd." 382 "National Agricultural and Food Research Organization" 383 "MCL Industries" 384 "Camano Light" 385 "Johnson Outdoor Marine Electronics" 386 "JLG Automation BVBA" 387 "Orscheln Products, LLC" 388 "Innomatix, LLC" 389 "Benchmark Electronics, Minnesota Division" 390 "Partech Inc." 391 "Electronic Design for Industry, Inc" 392 "Tianyuan Technology Co Ltd." 393 "Harvest Tec, Inc" 394 "Capi 2 Nederland BV" 395 "GENTEC S.R.L." 396 "Beyond Measure" 397 "Sanyo-kiki Co Ltd." 398 "Hilite International" 399 "ISEKI & Co., Ltd." 400 "Livorsi Marine" 401 "Torqeedo GmbH" 402 "Simma Software, Inc." 403 "Trackwell ADS, Inc." 404 "Com Nav Marine Ltd" 405 "Wema System AS" 406 "Vecima Networks Inc." 407 "Comtech Mobile Datacom" 408 "Corvus Energy Ltd." 409 "Transfluid S.r.L." 410 "COBO S.p.A. Divisione 3B6" 411 "Hy-Drive Technologies Ltd." 412 "WebTech Wireless Inc." 413 "Datapross Nijbroek bv" 414 "Cattron Group International" 415 "Valid Manufacturing Ltd." 416 "Kubota Corporation" 417 "KZValve" 418 "Intellistick Inc" 419 "Fusion Electronics Ltd" 420 "Vermeer Corporation, ACS Group" 421 "Vertex Standard Co., Ltd" 422 "True Heading AB" 423 "BSM Wireless, Inc." 424 "Odyne LLC" 425 "Methode Electronics Inc, MDI" 426 "Egersund Marine Electronics AS" 427 "em-trak Marine Electronics Ltd" 428 "Mfg_428" 429 "Rota Engineering Ltd." 455 "ADZ NAGANO GmbH" 456 "General Kinetics" 457 "RUSELPROM-ElectricDrive Ltd" 458 "Control Solutions, Inc." 459 "Alltek Marine Electronics Corp" 460 "San Giorgio S.E.I.N." 461 "HAWE Hydraulik SE" 462 "IHI Shibaura Machinery Corporation" 463 "PROBOTIQ" 464 "Leach International Corporation" 465 "Ashcroft Inc" 466 "Veethree Electronics and Marine LLC" 467 "Lely Industries N.V." 468 "Tyco Fire Protection Products" 469 "RA Consulting GmbH" 470 "SI-TEX Marine Electronics" 471 "Sea Cross Marine AB" 472 "Tenneco Inc." 473 "Boss Industries, Inc." 474 "Persen Technologies Inc." 475 "GME" 476 "Hummingbird Marine Electronics" 477 "OilQuick AB" 478 "OceanSat BV" 479 "Vapor Bus International" 430 "Auteq Telematica S.A." 431 "Tohatsu Corporation" 432 "S&A Systems, Inc." 433 "Rowe Electronics" 434 "Stored Energy Systems" 435 "Zunhammer GmbH" 436 "Kinze Manufacturing" 437 "Digital Yacht Limited" 438 "Comar Systems Ltd" 439 "Hyundai Heavy Industries" 440 "Cummins Power Generation" 441 "PTG Reifendruckregelsysteme GmbH" 442 "Horsch Maschinen GmbH" 443 "SignalQuest, Inc." 444 "ITT Power Solutions" 445 "KAT MECHATRONIC, Electronic Product Division" 446 "CertTech, L.L.C." 447 "Great Plains Mfg." 448 "Stanadyne Corporation, Electronics Systems" 449 "Polaris Industries Inc" 450 "Dycor Technologies Ltd." 451 "Parker Hannifin Corp" 452 "WIKA Alexander Wiegand SE & Co. KG" 453 "Cooper Bussmann" 454 "NGK Spark Plug Co. Ltd" 480 "EnerDel, Inc." 481 "Chetco Digital Instruments" 482 "Tricon Electronics" 483 "Valeo" 484 "Headsight Inc." 485 "MATT automotive" 486 "Westport Innovations Inc." 487 "DSE Test Solutions A/S" 488 "The Charles Machine Works, Inc." 489 "Appareo Systems" 490 "QuikQ" 491 "Penny and Giles Ltd" 492 "Inergy Automotive Systems" 493 "Watcheye" 494 "Synerject" 495 "HOLMER Maschinenbau GmbH" 496 "W. Gessmann GmbH" 497 "SENTRON Sistemas Embarcados" 498 "Innovative Design Solutions, Inc." 499 "LCJ Capteurs" 500 "Oxbo International Corporation" 501 "Agrotronix S.A." 502 "Attwood Corporation" 503 "Naviop S.R.L." 504 "Vesper Marine" 505 "Yetter Farm Equipment" 506 "IHI STAR Machinery Corporation" 507 "Test Center ISOBUS" 508 "Transtech Innovations" 509 "MOTORTECH GmbH" 510 "Marinesoft Co. Ltd" 511 "Sulky" 512 "Inpower LLC" 513 "FarmscanAg" 514 "DISTek Integration, Inc." 515 "GINAF Trucks Nederland B.V." 516 "AVAT Automation GmbH" 517 "Noland Engineering" 518 "Transas USA Inc." 519 "Peeters Landbouwmachines b.v." 520 "Trapeze" ;
VAL_ 2360147710 GuidSysComExitReasonCode 0 "No reason/all clear " 1 "Operator presence not detected" 2 "Implement released control of function " 3 "Operator override of function" 4 "Operator control not in valid position" 5 "Remote command timeout" 6 "Remote command out of range/invalid" 7 "Function not calibrated" 8 "Operator control fault" 9 "Function fault" 20 "Hydraulic oil level too low " 21 "Hydraulic oil temperature too low" 22 "Vehicle transmission gear does not allow remote commands" 23 "Vehicle speed too low " 24 "Vehicle speed too high" 25 "Alternate guidance system active" 26 "Control unit in diagnostic mode" 62 "Error " 63 "Not available (parameter not supported)" ;
VAL_ 2360147710 GuidanceLimitStatus 0 "Not limited" 1 "Operator limited/controlled (request cannot be implemented) " 2 "Limited high (only lower command values result in a change) " 3 "Limited low (only higher command values result in a change)" 4 "Reserved" 5 "Reserved" 6 "Non-recoverable fault " 7 "Not available (parameter not supported) " ;
VAL_ 2360147710 RequestResetCommandStatus 3 "NotAvailable" 2 "Error" 1 "ResetRequired" 0 "ResetNotRequired" ;
VAL_ 2360147710 SteeringInputPositionStatus 3 "NotAvailable" 2 "Error" 1 "CorrectPosition" 0 "NotTheCorrectPosition" ;
VAL_ 2360147710 SteeringSystemReadiness 3 "NotAvailable" 2 "Error" 1 "SystemIsReady" 0 "SystemIsNotReady" ;
VAL_ 2360147710 MechanicalSystemLockout 3 "NotAvailable" 2 "Error" 1 "Active" 0 "NotActive" ;
VAL_ 2360213246 CurvatureCommandStatus 3 "NotAvailable" 2 "Error" 1 "IntendedToSteer" 0 "NotIntendedToSteer" ;
VAL_ 2563047166 FailSaveModeCmd 3 "DoNotCare" 1 "Float" 0 "Block" ;
VAL_ 2563047166 StateCmd 15 "Reserved" 3 "Float" 2 "Retract" 1 "Extend" 0 "Block" ;
VAL_ 2563112702 ValveLimitStatus 0 "Not limited" 1 "Operator Limited" 2 "Limited High" 3 "Limited Low" 4 "Reserved" 5 "Reserver" 6 "Non-recoverable Fault" 7 "Not available" ;
VAL_ 2563178238 ValveLimitStatus 0 "Not limited" 1 "Operator Limited" 2 "Limited High" 3 "Limited Low" 4 "Reserved" 5 "Reserver" 6 "Non-recoverable Fault" 7 "Not available" ;
VAL_ 2563178238 FailSafeMode 3 "NotAvailable" 2 "ErrorIndication" 1 "Float" 0 "Block" ;
VAL_ 2563178238 ValveState 15 "DoNotCare" 14 "ErrorIndication" 3 "Floating" 2 "Retract" 1 "Extend" 0 "Blocked" ;
VAL_ 2628452094 RF_ReportHiddenFiles 0 "DoNotReportHiddenFiles" 1 "ReportHiddenFiles" 255 "NotAvailable" ;
VAL_ 2628452094 SF_PositionMode 0 "From the beginning of the file" 1 "From the current pointer pos" 2 "From the end of the file" ;
VAL_ 2628452094 OF_FlagExclusiveAccess 0 "Open file for shared read access" 1 "Open file with exclusive access" ;
VAL_ 2628452094 OF_FlagAppend 0 "Open file for random access" 1 "Open file for appending data" ;
VAL_ 2628452094 SET_ATTR_Hidden 0 "Clear 'hidden' attribute" 1 "Set 'hidden' attribute" 2 "Reserved" 3 "Leave 'hidden' attribute" ;
VAL_ 2628452094 OF_FlagCreateNew 0 "Open an existing file" 1 "Create new file if not existing" ;
VAL_ 2628452094 MF_MoveModeRecursive 0 "'recursive' mode is not set" 1 "'recursive' mode is set" ;
VAL_ 2628452094 DF_DeleteModeRecursive 0 "'recursive' mode is not set" 1 "'recursive' mode is set" ;
VAL_ 2628452094 MF_MoveModeForce 0 "'force' mode is not set" 1 "'force' mode is set" ;
VAL_ 2628452094 DF_DeleteModeForce 0 "'force' mode is not set" 1 "'force' mode is set" ;
VAL_ 2628452094 SET_ATTR_ReadOnly 0 "Clear 'read-only' attribute" 1 "Set 'read-only' attribute" 2 "Reserved" 3 "Leave 'read-only' attribute" ;
VAL_ 2628452094 OF_FlagReadWrite 0 "Open file for reading only" 1 "Open file for writing only" 2 "Open file for reading & writing" 3 "Open directory for reading" ;
VAL_ 2628452094 MF_MoveModeCopy 0 "'copy' mode is not set" 1 "'copy' mode is set" ;
VAL_ 2628452094 DF_DeleteMode 0 "'copy' mode is not set" 1 "'copy' mode is set" ;
VAL_ 2628452094 VS_RequestVolumeToPrepareForRemo 1 "RequestVolumeToPrepareForRemoval" ;
VAL_ 2628452094 VS_ReportVolumeUsedByClient 0 "ReportVolumeNotInUseByClient" 1 "ReportVolumeInUseByClient" ;
VAL_ 2628452094 CM_VersionNumber 0 "DIS" 1 "FDIS" 2 "FirstPublishedEditionOfIS" 3 "FirstPublishedEditionAndAmd1OfIS" 255 "CompliantToVersion2AndPrior" ;
VAL_ 2628452094 FSClientCommand 0 "CMConnectionMaintenance" 16 "DHGetCurrentDirectory" 32 "FAOpenFile" 33 "FASeekFile" 34 "FAReadFile" 35 "FAWriteFile" 36 "FACloseFile" 48 "FHMoveFile" 49 "FHDeleteFile" 50 "FHGetFileAttributes" 51 "FHSetFileAttributes" 17 "DHChangeCurrentDirectory" 52 "FHGetFileDateTime" 64 "VHVolumeInitialization" 1 "CMGetFileServerProperties" 2 "VSVolumeStatusRequest" ;
VAL_ 2628517630 GA_ATTR_VolumeRemovable 0 "Volume is removable" 1 "Volume is not removable" ;
VAL_ 2628517630 GA_ATTR_SupportsLongFilenames 0 "Volume supports no long filename" 1 "Volume supports long filenames" ;
VAL_ 2628517630 VI_ATTR_Directory 0 "Handle does not specify a dir" 1 "Handle specifies a directory" ;
VAL_ 2628517630 GA_ATTR_IsVolume 0 "'System' attribute is not set" 1 "'System' attribute is set" ;
VAL_ 2628517630 GA_ATTR_VolSupportsHiddenAttr 0 "Volume not support hidden attr." 1 "Volume supports hidden attribute" ;
VAL_ 2628517630 GA_ATTR_Hidden 0 "'Hidden' attribute is not set" 1 "'Hidden' attribute is set" ;
VAL_ 2628517630 GA_ATTR_ReadOnly 0 "'Read-only' attribute is not set" 1 "'Read-only' attribute is set" ;
VAL_ 2628517630 GSP_SupportMultipleVolumes 0 "Beschreibung für den Wert '0'" ;
VAL_ 2628517630 FDT_ErrorCode 0 "Success" 1 "Access Denied" 3 "Too many files open" 4 "File, path or volume not found" 6 "Invalid given source name" 10 "Media is not present" 44 "Any other error" 43 "Out ot memory" 11 "Failure during a read operation" 13 " Volume possibly not initialized" ;
VAL_ 2628517630 RF_ErrorCode 45 "File pointer at end of file" 44 "Any other error" 42 "Invalid request length" 5 "Invalid handle" 0 "Success" 11 "Failure during read operation" 43 "Out of memory" 1 "Access denied" ;
VAL_ 2628517630 SF_ErrorCode 0 "Success" 5 "Invalid handle" 42 "Invalid request length" 44 "Any other error" 45 "File pointer at end of file" 11 "Failure during read operation" 43 "Out of memory" ;
VAL_ 2628517630 OF_ErrorCode 0 "Success" 1 "Access Denied" 2 "Invalid Access" 3 "Too many files open" 4 "File, path or volume not found" 6 "Invalid given source name" 8 "Volume out of free space" 10 "Media is not present" 44 "Any other error" 43 "Out of memory" 13 "Volume possibly not initialized" ;
VAL_ 2628517630 WF_ErrorCode 0 "Success" 1 "Access Denied" 5 "Invalid handle" 8 "Volume out of free space" 9 "Failure during a write operation" 42 "Invalid request length" 44 "Any other error" 43 "Out of memory" ;
VAL_ 2628517630 CF_ErrorCode 0 "Success" 1 "Access Denied" 5 "Invalid handle" 8 "Volume out of free space" 9 "Failure during a write operation" 44 "Any other error" 43 "Out ot memory" ;
VAL_ 2628517630 MF_ErrorCode 0 "Success" 1 "Access Denied" 3 "Too many files open" 6 "Invalid given source name" 7 "Invalid given destination name" 8 "Volume out of free space" 9 "Verify failure during a write op" 10 "Media is not present" 44 "Any other error" 43 "Out of memory" 4 "File, path or volume not found" 13 "Volume possibly not initialized" ;
VAL_ 2628517630 GA_ErrorCode 0 "Success" 1 "Access Denied" 3 "Too many files open" 4 "File, path or volume not found" 6 "Invalid given source name" 10 "Media is not present" 44 "Any other error" 43 "Out of memory" 11 "Failure during read operation" 13 "Volume possibly not initialized" ;
VAL_ 2628517630 SA_ErrorCode 0 "Success" 1 "Access Denied" 3 "Too many files open" 4 "File, path or volume not found" 6 "Invalid given source name" 8 "Volume out of free space" 9 "Failure during write operation" 10 "Media is not present" 44 "Any other error" 43 "Out of memory" 11 "Failure during read operation" 13 "Volume possibly not initialized" ;
VAL_ 2628517630 GCD_ErrorCode 0 "Success" 10 "Media is not present" 44 "Any other error" 43 "Out of Memory" 13 "Volume possibly not initialized" ;
VAL_ 2628517630 CCD_ErrorCode 0 "Success" 10 "Media is not present" 44 "Any other error" 43 "Out of memory" 13 "Volume possibly not initialized" 1 "Access denied" 2 "Invalid Access" 4 "File, path or volume not found" 7 "Invalid destination name given" ;
VAL_ 2628517630 DF_ErrorCode 0 "Success" 1 "Access Denied" 4 "File, path or volume not found" 6 "Invalid given source name" 10 "Media is not present" 44 "Any other error" 43 "Out of memory" 9 "Failure during write operation" 11 "Failure during read operation" 13 "Volume possibly not initialized" ;
VAL_ 2628517630 VI_ErrorCode 0 "Success" 1 "Access Denied" 4 "File, path or volume not found" 6 "Invalid given source name" 8 "Volume out of free space" 9 "Failure during write operation" 42 "Invalid request length" 44 "Any other error" 43 "Out of memory" 10 "Media is not present" 11 "Failure during read operation" 13 "Volume possibly not initialized" ;
VAL_ 2628517630 GSP_VersionNumber 0 "DIS" 1 "FDIS" 2 "FirstPublishedEditionOfIS" 3 "FirstPublishedEditionAndAmd1OfIS" 255 "CompliantToVersion2AndPrior" ;
VAL_ 2628517630 VS_VolumeStatus 0 "Present" 1 "InUse" 2 "PreparingForRemoval" 3 "Removed" ;
VAL_ 2628517630 FSServerCommand 0 "CMFileServerStatus" 16 "DHGetCurrentDirectory" 32 "FAOpenFile" 33 "FASeekFile" 34 "FAReadFile" 35 "FAWriteFile" 36 "FACloseFile" 48 "FHMoveFile" 49 "FHDeleteFile" 50 "FHGetFileAttributes" 51 "FHSetFileAttribute" 17 "DHChangeCurrentDirectory" 52 "FHGetFileDateTime" 64 "VHVolumeInitialization" 1 "CMGetFileServerProperties" 2 "VSVolumeStatusResponse" ;
VAL_ 2364540158 EngStarterMode 15 "not available" 14 "error" 12 "starter inhibited  reason unknown" 9 "starter inhibited due to intake air shutoff valve being active" 8 "starter inhibited due to starter overtemp" 7 "starter inhibited due to active immobilizer" 6 "starter inhibited due to driveline engaged or other transmission inhibit" 5 "starter inhibited due to engine not ready for start preheating" 4 "starter inhibited due to engine already running" 3 "start finished starter not active after having been actively engaged after 50ms mode goes to 0000" 2 "starter active gear engaged" 1 "starter active gear not engaged" 0 "start not requested" 10 "starter inhibited due to active SCR inducement" 11 "Reserved" 13 "error legacy implementation only use 1110" ;
VAL_ 2364540158 ActlEngPrcntTorqueHighResolution 0 "0000" 1 "0125" 7 "0875" 8 "1111  not available" ;
VAL_ 2563309310 PGNumber 255 "NotAvailable" ;
VAL_ 2563309310 ControlByte 255 "EAbort" 20 "ERTS" 21 "ECTS" 22 "EDPO" 23 "EEoMACK" 24 "EAbort" ;
VAL_ 2563309310 ConnectionAbortReason 15 "ECTS requested packets exceeds message size" 14 "Unexpected ECTS PGN (PGN in ECTS is bad)" 13 "Deprecated use 254 instead" 12 "Bad EDPO offset" 11 "EDPO number of packets is greater than CTS" 10 "Unexpected EDPO PGN (PGN in EDPO is bad)" 9 "Unexpected EDPO packet" 8 "Duplicate sequence number" 1 "Already in one or more connection-managed sessions" 2 "System resources were needed for another task" 3 "Timeout occurred" 4 "CTS messages received when data transfer is in progress" 5 "Maximum retransmit request limit reached" 6 "Unexpected data transfer packet" 7 "Bad sequence number" ;
VAL_ 2583168510 RefrenceStationType1 14 "Error" 1 "GLONASS" 0 "GPS" ;
VAL_ 2583168510 GNSSIntegrity 3 "Unsafe" 2 "Caution" 1 "Safe" 0 "No integrity checking" ;
VAL_ 2583168510 GNSSMethod 14 "Error" 8 "Simulate mode" 7 "Manual input" 6 "Estimated (DR) mode" 5 "RTK float" 4 "RTK fixed integer" 3 "Precise GNSS" 2 "DGNSS fix" 1 "GNSS fix" 0 "no GPS" ;
VAL_ 2583168510 TypeOfSystem 4 "GPS and SBAS and GLONASS" 3 "GPS and SBAS(WAAS)" 2 "GPS and GLONASS" 1 "GLONASS" 0 "GPS" ;
VAL_ 2566849534 ManufacturerSpecific8 255 "NotAvailable" ;
VAL_ 2566849534 ManufacturerSpecific7 255 "NotAvailable" ;
VAL_ 2566849534 ManufacturerSpecific6 255 "NotAvailable" ;
VAL_ 2566849534 ManufacturerSpecific5 255 "NotAvailable" ;
VAL_ 2566849534 ManufacturerSpecific4 255 "NotAvailable" ;
VAL_ 2566849534 ManufacturerSpecific3 255 "NotAvailable" ;
VAL_ 2566849534 ManufacturerSpecific2 255 "NotAvailable" ;
VAL_ 2566849534 ManufacturerSpecific1 255 "NotAvailable" ;
VAL_ 2566849278 ManufacturerSpecific8 255 "NotAvailable" ;
VAL_ 2566849278 ManufacturerSpecific7 255 "NotAvailable" ;
VAL_ 2566849278 ManufacturerSpecific6 255 "NotAvailable" ;
VAL_ 2566849278 ManufacturerSpecific5 255 "NotAvailable" ;
VAL_ 2566849278 ManufacturerSpecific4 255 "NotAvailable" ;
VAL_ 2566849278 ManufacturerSpecific3 255 "NotAvailable" ;
VAL_ 2566849278 ManufacturerSpecific2 255 "NotAvailable" ;
VAL_ 2566849278 ManufacturerSpecific1 255 "NotAvailable" ;
VAL_ 2566849022 ManufacturerSpecific8 255 "NotAvailable" ;
VAL_ 2566849022 ManufacturerSpecific7 255 "NotAvailable" ;
VAL_ 2566849022 ManufacturerSpecific6 255 "NotAvailable" ;
VAL_ 2566849022 ManufacturerSpecific5 255 "NotAvailable" ;
VAL_ 2566849022 ManufacturerSpecific4 255 "NotAvailable" ;
VAL_ 2566849022 ManufacturerSpecific3 255 "NotAvailable" ;
VAL_ 2566849022 ManufacturerSpecific2 255 "NotAvailable" ;
VAL_ 2566849022 ManufacturerSpecific1 255 "NotAvailable" ;
VAL_ 2566848766 ManufacturerSpecific8 255 "NotAvailable" ;
VAL_ 2566848766 ManufacturerSpecific7 255 "NotAvailable" ;
VAL_ 2566848766 ManufacturerSpecific6 255 "NotAvailable" ;
VAL_ 2566848766 ManufacturerSpecific5 255 "NotAvailable" ;
VAL_ 2566848766 ManufacturerSpecific4 255 "NotAvailable" ;
VAL_ 2566848766 ManufacturerSpecific3 255 "NotAvailable" ;
VAL_ 2566848766 ManufacturerSpecific2 255 "NotAvailable" ;
VAL_ 2566848766 ManufacturerSpecific1 255 "NotAvailable" ;
SIG_VALTYPE_ 2565340673 ZoomValue_PanZoom : 1;
SIG_VALTYPE_ 2565340673 ZoomValue : 1;

SG_MUL_VAL_ 2565340673 UnsupportedVtFunction VTFunctionECUtoVT 253-253;
SG_MUL_VAL_ 2565340673 AuxiliaryInputID_1 VTFunctionECUtoVT 34-34;
SG_MUL_VAL_ 2565340673 AuxiliaryFunctionID_1 VTFunctionECUtoVT 34-34;
SG_MUL_VAL_ 2565340673 NumOfPreferredFunctions VTFunctionECUtoVT 34-34;
SG_MUL_VAL_ 2565340673 ModelIdentificationCode VTFunctionECUtoVT 34-34;
SG_MUL_VAL_ 2565340673 ArbitraryAddressCapable VTFunctionECUtoVT 34-34;
SG_MUL_VAL_ 2565340673 IndustryGroup VTFunctionECUtoVT 34-34;
SG_MUL_VAL_ 2565340673 VehicleSystemInstance VTFunctionECUtoVT 34-34;
SG_MUL_VAL_ 2565340673 VehicleSystem2 VTFunctionECUtoVT 34-34;
SG_MUL_VAL_ 2565340673 ZoomValue_PanZoom SubCommandID 16-16;
SG_MUL_VAL_ 2565340673 OperatingState2 VTFunctionECUtoVT 33-33;
SG_MUL_VAL_ 2565340673 Function VTFunctionECUtoVT 34-34;
SG_MUL_VAL_ 2565340673 OperatingState1 VTFunctionECUtoVT 33-33;
SG_MUL_VAL_ 2565340673 YPosChangeTopLeftLong VTFunctionECUtoVT 180-180;
SG_MUL_VAL_ 2565340673 LineDirection VTFunctionECUtoVT 169-169;
SG_MUL_VAL_ 2565340673 FunctionInstance VTFunctionECUtoVT 34-34;
SG_MUL_VAL_ 2565340673 ECUInstance VTFunctionECUtoVT 34-34;
SG_MUL_VAL_ 2565340673 NewValueY VTFunctionECUtoVT 182-182;
SG_MUL_VAL_ 2565340673 GraphicRepresentationObjectID VTFunctionECUtoVT 181-181;
SG_MUL_VAL_ 2565340673 FontStyle VTFunctionECUtoVT 170-170;
SG_MUL_VAL_ 2565340673 YPosChangeTopLeft VTFunctionECUtoVT 165-165;
SG_MUL_VAL_ 2565340673 OffTimeDuration_Audio VTFunctionECUtoVT 163-163;
SG_MUL_VAL_ 2565340673 ButtonKeyCode VTFunctionECUtoVT 1-1;
SG_MUL_VAL_ 2565340673 SoftKeyCode VTFunctionECUtoVT 0-0;
SG_MUL_VAL_ 2565340673 Status_2 VTFunctionECUtoVT 9-9;
SG_MUL_VAL_ 2565340673 NewViewportHeight SubCommandID 17-17;
SG_MUL_VAL_ 2565340673 ViewportY_PanZoom SubCommandID 16-16;
SG_MUL_VAL_ 2565340673 ViewportY SubCommandID 14-14;
SG_MUL_VAL_ 2565340673 EllipseHeight SubCommandID 11-11;
SG_MUL_VAL_ 2565340673 RectangleHeight_Draw SubCommandID 10-10;
SG_MUL_VAL_ 2565340673 EndPixelOffsetY SubCommandID 9-9;
SG_MUL_VAL_ 2565340673 PixelOffsetY SubCommandID 8-8;
SG_MUL_VAL_ 2565340673 CursorOffsetY SubCommandID 1-1;
SG_MUL_VAL_ 2565340673 CursorPosY SubCommandID 0-0;
SG_MUL_VAL_ 2565340673 NewStringValue VTFunctionECUtoVT 179-179;
SG_MUL_VAL_ 2565340673 Value2 VTFunctionECUtoVT 33-33;
SG_MUL_VAL_ 2565340673 NewHeigthAttribute VTFunctionECUtoVT 183-183;
SG_MUL_VAL_ 2565340673 FontType VTFunctionECUtoVT 170-170;
SG_MUL_VAL_ 2565340673 XPosChangeTopLeftLong VTFunctionECUtoVT 180-180;
SG_MUL_VAL_ 2565340673 FillPatternObjectID VTFunctionECUtoVT 172-172;
SG_MUL_VAL_ 2565340673 LineArt VTFunctionECUtoVT 171-171;
SG_MUL_VAL_ 2565340673 LabelFontType VTFunctionECUtoVT 181-181;
SG_MUL_VAL_ 2565340673 Height VTFunctionECUtoVT 169-169;
SG_MUL_VAL_ 2565340673 NewHeight VTFunctionECUtoVT 166-166;
SG_MUL_VAL_ 2565340673 XPosChangeTopLeft VTFunctionECUtoVT 165-165;
SG_MUL_VAL_ 2565340673 TouchState VTFunctionECUtoVT 2-2;
SG_MUL_VAL_ 2565340673 TextLength SubCommandID 13-13;
SG_MUL_VAL_ 2565340673 ManufacturerCode VTFunctionECUtoVT 34-34;
SG_MUL_VAL_ 2565340673 AuxErrorAnyOther VTFunctionECUtoVT 37-37;
SG_MUL_VAL_ 2565340673 CursorPosX SubCommandID 0-0;
SG_MUL_VAL_ 2565340673 CursorOffsetX SubCommandID 1-1;
SG_MUL_VAL_ 2565340673 ForegroundColour SubCommandID 2-2;
SG_MUL_VAL_ 2565340673 BackgroundColour SubCommandID 3-3;
SG_MUL_VAL_ 2565340673 LineAttributesObjectID SubCommandID 4-4;
SG_MUL_VAL_ 2565340673 FillAttributesObjectID SubCommandID 5-5;
SG_MUL_VAL_ 2565340673 FontAttributesObjectID SubCommandID 6-6;
SG_MUL_VAL_ 2565340673 RectangleWidth_Erase SubCommandID 7-7;
SG_MUL_VAL_ 2565340673 RectangleHeight_Erase SubCommandID 7-7;
SG_MUL_VAL_ 2565340673 PixelOffsetX SubCommandID 8-8;
SG_MUL_VAL_ 2565340673 EndPixelOffsetX SubCommandID 9-9;
SG_MUL_VAL_ 2565340673 RectangleWidth_Draw SubCommandID 10-10;
SG_MUL_VAL_ 2565340673 EllipseWidth SubCommandID 11-11;
SG_MUL_VAL_ 2565340673 NumberOfPoints SubCommandID 12-12;
SG_MUL_VAL_ 2565340673 TextOption SubCommandID 13-13;
SG_MUL_VAL_ 2565340673 ViewportX SubCommandID 14-14;
SG_MUL_VAL_ 2565340673 ZoomValue SubCommandID 15-15;
SG_MUL_VAL_ 2565340673 ViewportX_PanZoom SubCommandID 16-16;
SG_MUL_VAL_ 2565340673 NewViewportWidth SubCommandID 17-17;
SG_MUL_VAL_ 2565340673 ObjectID SubCommandID 18-18;
SG_MUL_VAL_ 2565340673 PictureGraphicsID_Canvas SubCommandID 19-19;
SG_MUL_VAL_ 2565340673 PictureGraphicsID_Viewport SubCommandID 20-20;
SG_MUL_VAL_ 2565340673 LastWideChar VTFunctionECUtoVT 193-193;
SG_MUL_VAL_ 2565340673 LockTimeout VTFunctionECUtoVT 189-189;
SG_MUL_VAL_ 2565340673 NewValueX VTFunctionECUtoVT 182-182;
SG_MUL_VAL_ 2565340673 NewObjectID VTFunctionECUtoVT 177-177;
SG_MUL_VAL_ 2565340673 NewAttributeValue VTFunctionECUtoVT 175-175;
SG_MUL_VAL_ 2565340673 NewSoftKeyMaskObjectID VTFunctionECUtoVT 174-174;
SG_MUL_VAL_ 2565340673 FillColour VTFunctionECUtoVT 172-172;
SG_MUL_VAL_ 2565340673 LineWidth VTFunctionECUtoVT 171-171;
SG_MUL_VAL_ 2565340673 FontSize VTFunctionECUtoVT 170-170;
SG_MUL_VAL_ 2565340673 NewValue VTFunctionECUtoVT 168-168;
SG_MUL_VAL_ 2565340673 OnTimeDuration_Audio VTFunctionECUtoVT 163-163;
SG_MUL_VAL_ 2565340673 AuxErrorInvalidInputID VTFunctionECUtoVT 37-37;
SG_MUL_VAL_ 2565340673 VTChangeNumericValueValue VTFunctionECUtoVT 5-5;
SG_MUL_VAL_ 2565340673 ButtonObjectParentID VTFunctionECUtoVT 1-1;
SG_MUL_VAL_ 2565340673 KeyObjectParentID VTFunctionECUtoVT 0-0;
SG_MUL_VAL_ 2565340673 ObjectId_2 VTFunctionECUtoVT 9-9;
SG_MUL_VAL_ 2565340673 Value1 VTFunctionECUtoVT 33-33;
SG_MUL_VAL_ 2565340673 TotalNumberOfBytes VTFunctionECUtoVT 179-179;
SG_MUL_VAL_ 2565340673 AttributeIDToChange VTFunctionECUtoVT 175-175;
SG_MUL_VAL_ 2565340673 SubCommandID VTFunctionECUtoVT 184-184;
SG_MUL_VAL_ 2565340673 NewWidthAttribute VTFunctionECUtoVT 183-183;
SG_MUL_VAL_ 2565340673 IndexOfThePointToReplace VTFunctionECUtoVT 182-182;
SG_MUL_VAL_ 2565340673 StringVariableObjectID VTFunctionECUtoVT 181-181;
SG_MUL_VAL_ 2565340673 ChangeChildLocationObjectID VTFunctionECUtoVT 165-165;
SG_MUL_VAL_ 2565340673 ListIndex VTFunctionECUtoVT 177-177;
SG_MUL_VAL_ 2565340673 NewPriority VTFunctionECUtoVT 176-176;
SG_MUL_VAL_ 2565340673 AttributeID VTFunctionECUtoVT 185-185;
SG_MUL_VAL_ 2565340673 NewActiveMaskObjectID VTFunctionECUtoVT 173-173;
SG_MUL_VAL_ 2565340673 FillType VTFunctionECUtoVT 172-172;
SG_MUL_VAL_ 2565340673 LineColour VTFunctionECUtoVT 171-171;
SG_MUL_VAL_ 2565340673 FontColour VTFunctionECUtoVT 170-170;
SG_MUL_VAL_ 2565340673 Width VTFunctionECUtoVT 169-169;
SG_MUL_VAL_ 2565340673 NewBackgroundColour VTFunctionECUtoVT 167-167;
SG_MUL_VAL_ 2565340673 NewWidth VTFunctionECUtoVT 166-166;
SG_MUL_VAL_ 2565340673 ChangeChildPositionObjectID VTFunctionECUtoVT 180-180;
SG_MUL_VAL_ 2565340673 SetFocusOpenForEditing VTFunctionECUtoVT 162-162;
SG_MUL_VAL_ 2565340673 EnableOrDisable VTFunctionECUtoVT 161-161;
SG_MUL_VAL_ 2565340673 ShowOrHide VTFunctionECUtoVT 160-160;
SG_MUL_VAL_ 2565340673 AuxInputEnable VTFunctionECUtoVT 37-37;
SG_MUL_VAL_ 2565340673 AssignmentErrorNotAccepted VTFunctionECUtoVT 36-36;
SG_MUL_VAL_ 2565340673 ObjectOfChangedStringValueID VTFunctionECUtoVT 8-8;
SG_MUL_VAL_ 2565340673 VTChangeSoftKeyMaskObjectID VTFunctionECUtoVT 7-7;
SG_MUL_VAL_ 2565340673 VTSelectInputObjectStatus VTFunctionECUtoVT 3-3;
SG_MUL_VAL_ 2565340673 YPosition VTFunctionECUtoVT 2-2;
SG_MUL_VAL_ 2565340673 AuxiliaryFunctionID VTFunctionECUtoVT 32-32;
SG_MUL_VAL_ 2565340673 Status_1 VTFunctionECUtoVT 9-9;
SG_MUL_VAL_ 2565340673 IdentityNumber VTFunctionECUtoVT 34-34;
SG_MUL_VAL_ 2565340673 FirstWideChar VTFunctionECUtoVT 193-193;
SG_MUL_VAL_ 2565340673 MemoryRequired VTFunctionECUtoVT 192-192;
SG_MUL_VAL_ 2565340673 ObjectIDOfDataMaskToLock VTFunctionECUtoVT 189-189;
SG_MUL_VAL_ 2565340673 DataOrAlarmMaskObjectID VTFunctionECUtoVT 174-174;
SG_MUL_VAL_ 2565340673 Frequency_Audio VTFunctionECUtoVT 163-163;
SG_MUL_VAL_ 2565340673 ButtonObjectID VTFunctionECUtoVT 1-1;
SG_MUL_VAL_ 2565340673 KeyObjectID VTFunctionECUtoVT 0-0;
SG_MUL_VAL_ 2565340673 WSMaintenanceVersion VTFunctionECUtoVT 255-255;
SG_MUL_VAL_ 2565340673 AuxiliaryInputNumber VTFunctionECUtoVT 32-32;
SG_MUL_VAL_ 2565340673 ExtendedVersionLabelToDelete VTFunctionECUtoVT 214-214;
SG_MUL_VAL_ 2565340673 ExtendedVersionLabelToLoad VTFunctionECUtoVT 213-213;
SG_MUL_VAL_ 2565340673 ExtendedVersionLabelToStore VTFunctionECUtoVT 212-212;
SG_MUL_VAL_ 2565340673 MacroObjectID_2 VTFunctionECUtoVT 188-188;
SG_MUL_VAL_ 2565340673 AuxCapabilitiesRequestType VTFunctionECUtoVT 39-39;
SG_MUL_VAL_ 2565340673 WSMaintenanceInitiating WSMaintenanceVersion 3-254;
SG_MUL_VAL_ 2565340673 VersionLabelToDelete VTFunctionECUtoVT 210-210;
SG_MUL_VAL_ 2565340673 VersionLabelToLoad VTFunctionECUtoVT 209-209;
SG_MUL_VAL_ 2565340673 VersionLabelToStore VTFunctionECUtoVT 208-208;
SG_MUL_VAL_ 2565340673 CodePlane VTFunctionECUtoVT 193-193;
SG_MUL_VAL_ 2565340673 MacroObjectID VTFunctionECUtoVT 190-190;
SG_MUL_VAL_ 2565340673 LockUnlockCommand VTFunctionECUtoVT 189-189;
SG_MUL_VAL_ 2565340673 ColourMapObjectID VTFunctionECUtoVT 186-186;
SG_MUL_VAL_ 2565340673 ObjectToGetAttributeID VTFunctionECUtoVT 185-185;
SG_MUL_VAL_ 2565340673 GraphicsContextObjectID VTFunctionECUtoVT 184-184;
SG_MUL_VAL_ 2565340673 PolygonObjectToScaleID VTFunctionECUtoVT 183-183;
SG_MUL_VAL_ 2565340673 PolygonObjectToChangeID VTFunctionECUtoVT 182-182;
SG_MUL_VAL_ 2565340673 ObjectToAssociateLabelWithID VTFunctionECUtoVT 181-181;
SG_MUL_VAL_ 2565340673 ParentObjectID VTFunctionECUtoVT 8-8;
SG_MUL_VAL_ 2565340673 ObjectToChangeStringValueID VTFunctionECUtoVT 179-179;
SG_MUL_VAL_ 2565340673 ListInputObjectID VTFunctionECUtoVT 177-177;
SG_MUL_VAL_ 2565340673 AlarmMaskObjectID VTFunctionECUtoVT 176-176;
SG_MUL_VAL_ 2565340673 ObjectToChangeAttributeID VTFunctionECUtoVT 175-175;
SG_MUL_VAL_ 2565340673 MaskType VTFunctionECUtoVT 174-174;
SG_MUL_VAL_ 2565340673 WorkingSetObjectID VTFunctionECUtoVT 173-173;
SG_MUL_VAL_ 2565340673 ObjectToChangeFillAttributesID VTFunctionECUtoVT 172-172;
SG_MUL_VAL_ 2565340673 ObjectToChangeLineAttributesID VTFunctionECUtoVT 171-171;
SG_MUL_VAL_ 2565340673 ObjectToChangeFontID VTFunctionECUtoVT 170-170;
SG_MUL_VAL_ 2565340673 ObjectToChangeEndPointID VTFunctionECUtoVT 169-169;
SG_MUL_VAL_ 2565340673 ObjectToChangeNumValueID VTFunctionECUtoVT 168-168;
SG_MUL_VAL_ 2565340673 ObjectToChangeColourID VTFunctionECUtoVT 167-167;
SG_MUL_VAL_ 2565340673 ObjectToSizeID VTFunctionECUtoVT 166-166;
SG_MUL_VAL_ 2565340673 ChangeChildLocationParentObjectI VTFunctionECUtoVT 165-165;
SG_MUL_VAL_ 2565340673 AudioVolume VTFunctionECUtoVT 164-164;
SG_MUL_VAL_ 2565340673 NumberOfRepetitions_Audio VTFunctionECUtoVT 163-163;
SG_MUL_VAL_ 2565340673 SelectInputObjectID VTFunctionECUtoVT 162-162;
SG_MUL_VAL_ 2565340673 ObjectoEnableDisbaleID VTFunctionECUtoVT 161-161;
SG_MUL_VAL_ 2565340673 ObjectToShowHideID VTFunctionECUtoVT 160-160;
SG_MUL_VAL_ 2565340673 InputStatusObjectId VTFunctionECUtoVT 37-37;
SG_MUL_VAL_ 2565340673 AuxModelIdentification VTFunctionECUtoVT 35-35;
SG_MUL_VAL_ 2565340673 NumberOfInpuUnits VTFunctionECUtoVT 34-34;
SG_MUL_VAL_ 2565340673 AuxiliaryFunctionObjectID VTFunctionECUtoVT 36-36;
SG_MUL_VAL_ 2565340673 ObjectPoolRecord VTFunctionECUtoVT 17-17;
SG_MUL_VAL_ 2565340673 ChangeChildPositionParentObjectI VTFunctionECUtoVT 180-180;
SG_MUL_VAL_ 2565340673 VTChangeSoftKeyMaskParentID VTFunctionECUtoVT 7-7;
SG_MUL_VAL_ 2565340673 VTChangeActiveMaskObjectID VTFunctionECUtoVT 6-6;
SG_MUL_VAL_ 2565340673 VTChangeNumericValueObjectID VTFunctionECUtoVT 5-5;
SG_MUL_VAL_ 2565340673 VTEscObjectID VTFunctionECUtoVT 4-4;
SG_MUL_VAL_ 2565340673 VTSelectInputObjectID VTFunctionECUtoVT 3-3;
SG_MUL_VAL_ 2565340673 XPosition VTFunctionECUtoVT 2-2;
SG_MUL_VAL_ 2565340673 ButtonActivationCode VTFunctionECUtoVT 1-1;
SG_MUL_VAL_ 2565340673 KeyActivationCode VTFunctionECUtoVT 0-0;
SG_MUL_VAL_ 2565340673 InputObjectId VTFunctionECUtoVT 33-33;
SG_MUL_VAL_ 2565340673 SourceAddressOfAuxiliaryInputDev VTFunctionECUtoVT 32-32;
SG_MUL_VAL_ 2565340673 ObjectId_1 VTFunctionECUtoVT 9-9;
